VERSION ""

NS_ :

BS_:

BU_:

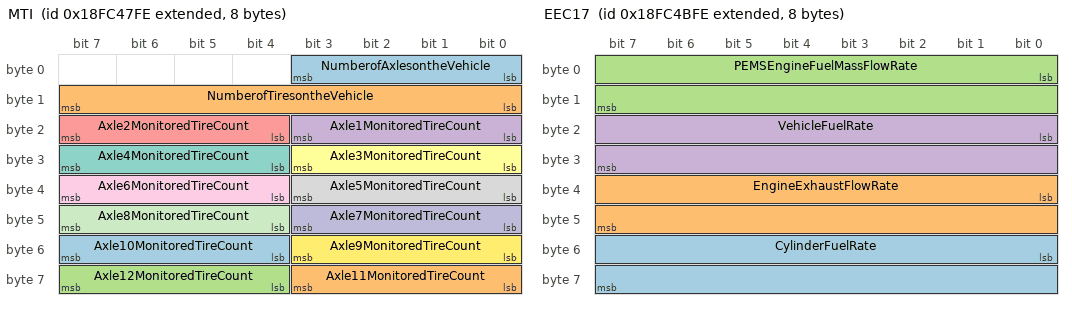
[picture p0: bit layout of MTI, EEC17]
BO_ 2566670334 MTI: 8 Vector__XXX
 SG_ Axle10MonitoredTireCount : 52|4@1+ (1,0) [0|13] "count" Vector__XXX
 SG_ Axle11MonitoredTireCount : 56|4@1+ (1,0) [0|13] "count" Vector__XXX
 SG_ Axle12MonitoredTireCount : 60|4@1+ (1,0) [0|13] "count" Vector__XXX
 SG_ Axle1MonitoredTireCount : 16|4@1+ (1,0) [0|13] "count" Vector__XXX
 SG_ Axle2MonitoredTireCount : 20|4@1+ (1,0) [0|13] "count" Vector__XXX
 SG_ Axle3MonitoredTireCount : 24|4@1+ (1,0) [0|13] "count" Vector__XXX
 SG_ Axle4MonitoredTireCount : 28|4@1+ (1,0) [0|13] "count" Vector__XXX
 SG_ Axle5MonitoredTireCount : 32|4@1+ (1,0) [0|13] "count" Vector__XXX
 SG_ Axle6MonitoredTireCount : 36|4@1+ (1,0) [0|13] "count" Vector__XXX
 SG_ Axle7MonitoredTireCount : 40|4@1+ (1,0) [0|13] "count" Vector__XXX
 SG_ Axle8MonitoredTireCount : 44|4@1+ (1,0) [0|13] "count" Vector__XXX
 SG_ Axle9MonitoredTireCount : 48|4@1+ (1,0) [0|13] "count" Vector__XXX
 SG_ NumberofAxlesontheVehicle : 0|4@1+ (1,0) [0|13] "count" Vector__XXX
 SG_ NumberofTiresontheVehicle : 8|8@1+ (1,0) [0|250] "count" Vector__XXX

BO_ 2566670590 AT2HI2: 24 Vector__XXX
 SG_ Atttt2SCRSstAvDstBtwSstCEvts : 160|32@1+ (0.125,0) [0|526385151.875] "km" Vector__XXX
 SG_ Atttt2SCRSstAvTBtwSstCEvts : 128|32@1+ (1,0) [0|4211081215] "s" Vector__XXX
 SG_ Atttt2SCRSstTtNSstCEvts : 32|32@1+ (1,0) [0|4211081215] "count" Vector__XXX
 SG_ Atttt2SCRSstTtNSstCItRqsts : 64|32@1+ (1,0) [0|4211081215] "count" Vector__XXX
 SG_ Atttt2SCRSstTtNSstCMRqsts : 96|32@1+ (1,0) [0|4211081215] "count" Vector__XXX
 SG_ Atttt2SCRSstTtSstCT : 0|32@1+ (1,0) [0|4211081215] "s" Vector__XXX

BO_ 2566670846 AT1HI2: 28 Vector__XXX
 SG_ Aftrtrtmnt1SCRSstmTtlClnngTm : 0|32@1+ (1,0) [0|4211081215] "s" Vector__XXX
 SG_ Atttt1SCRSstAvDstBtwSstCEvts : 160|32@1+ (0.125,0) [0|526385151.875] "km" Vector__XXX
 SG_ Atttt1SCRSstAvTBtwSstCEvts : 128|32@1+ (1,0) [0|4211081215] "s" Vector__XXX
 SG_ Atttt1SCRSstTtNSstCEvts : 32|32@1+ (1,0) [0|4211081215] "count" Vector__XXX
 SG_ Atttt1SCRSstTtNSstCItRqsts : 64|32@1+ (1,0) [0|4211081215] "count" Vector__XXX
 SG_ Atttt1SCRSstTtNSstCMRqsts : 96|32@1+ (1,0) [0|4211081215] "count" Vector__XXX
 SG_ TtlAftrtrtmntOprtngHrs : 192|32@1+ (1,0) [0|4211081215] "s" Vector__XXX

BO_ 2566671102 SCRSC: 8 Vector__XXX
 SG_ Atttt1SCRSstCdtsNtMtAtvC : 60|2@1+ (1,0) [0|3] "" Vector__XXX
 SG_ SCRSstCItdDtAtPdOId : 26|2@1+ (1,0) [0|3] "" Vector__XXX
 SG_ SCRSstCItdDtLwExstTpt : 34|2@1+ (1,0) [0|3] "" Vector__XXX
 SG_ SCRSstCItdDtPtSstLt : 42|2@1+ (1,0) [0|3] "" Vector__XXX
 SG_ SCRSstCItdDtVSpdAvAwdSpd : 30|2@1+ (1,0) [0|3] "" Vector__XXX
 SG_ SCRSstCItdDtVSpdBwAwdSpd : 46|2@1+ (1,0) [0|3] "" Vector__XXX
 SG_ SCRSstmClnngAtmtInttnCnfgrtn : 48|2@1+ (1,0) [0|3] "" Vector__XXX
 SG_ SCRSstmClnngInhtdDtClthDsnggd : 20|2@1+ (1,0) [0|3] "" Vector__XXX
 SG_ SCRSstmClnngInhtdDtEngnNtWrmdUp : 44|2@1+ (1,0) [0|3] "" Vector__XXX
 SG_ SCRSstmClnngInhtdDtInhtSwth : 18|2@1+ (1,0) [0|3] "" Vector__XXX
 SG_ SCRSstmClnngInhtdDtOtfNtrl : 28|2@1+ (1,0) [0|3] "" Vector__XXX
 SG_ SCRSstmClnngInhtdDtPrkngBrkNtSt : 32|2@1+ (1,0) [0|3] "" Vector__XXX
 SG_ SCRSstmClnngInhtdDtPTOAtv : 24|2@1+ (1,0) [0|3] "" Vector__XXX
 SG_ SCRSstmClnngInhtdDtSrvBrkAtv : 22|2@1+ (1,0) [0|3] "" Vector__XXX
 SG_ SCRSstmClnngInhtdDtSstmFltAtv : 36|2@1+ (1,0) [0|3] "" Vector__XXX
 SG_ SCRSstmClnngInhtdDtSstmTmt : 38|2@1+ (1,0) [0|3] "" Vector__XXX
 SG_ SCRSstmClnngInhtdDtTmprrSstmLkt : 40|2@1+ (1,0) [0|3] "" Vector__XXX
 SG_ SCRSstmClnngInhtdStts : 16|2@1+ (1,0) [0|3] "" Vector__XXX
 SG_ SCRSystemCleaningForcedStatus : 53|3@1+ (1,0) [0|7] "" Vector__XXX
 SG_ SCRSystemCleaningLampCommand : 0|3@1+ (1,0) [0|7] "" Vector__XXX
 SG_ SCRSystemCleaningStatus : 10|2@1+ (1,0) [0|3] "" Vector__XXX

BO_ 2566671358 EEC17: 8 Vector__XXX
 SG_ CylinderFuelRate : 48|16@1+ (0.03125,0) [0|2007.96875] "mg/stroke" Vector__XXX
 SG_ EngineExhaustFlowRate : 32|16@1+ (0.2,0) [0|12851] "kg/h" Vector__XXX
 SG_ PEMSEngineFuelMassFlowRate : 0|16@1+ (0.02,0) [0|1285.1] "g/s" Vector__XXX
 SG_ VehicleFuelRate : 16|16@1+ (0.02,0) [0|1285.1] "g/s" Vector__XXX

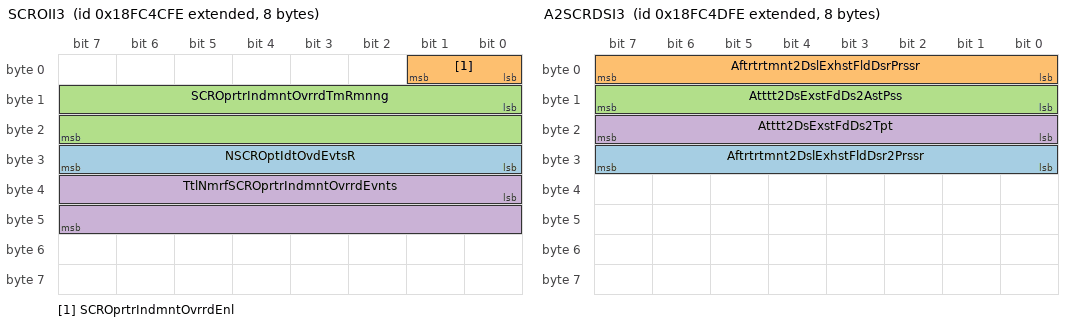
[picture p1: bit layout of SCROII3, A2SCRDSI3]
BO_ 2566671614 SCROII3: 8 Vector__XXX
 SG_ NSCROptIdtOvdEvtsR : 24|8@1+ (1,0) [0|250] "count" Vector__XXX
 SG_ SCROprtrIndmntOvrrdEnl : 0|2@1+ (1,0) [0|3] "" Vector__XXX
 SG_ SCROprtrIndmntOvrrdTmRmnng : 8|16@1+ (1,0) [0|64255] "s" Vector__XXX
 SG_ TtlNmrfSCROprtrIndmntOvrrdEvnts : 32|16@1+ (1,0) [0|64255] "count" Vector__XXX

BO_ 2566671870 A2SCRDSI3: 8 Vector__XXX
 SG_ Aftrtrtmnt2DslExhstFldDsr2Prssr : 24|8@1+ (4,0) [0|1000] "kPa" Vector__XXX
 SG_ Aftrtrtmnt2DslExhstFldDsrPrssr : 0|8@1+ (4,0) [0|1000] "kPa" Vector__XXX
 SG_ Atttt2DsExstFdDs2AstPss : 8|8@1+ (8,0) [0|2000] "kPa" Vector__XXX
 SG_ Atttt2DsExstFdDs2Tpt : 16|8@1+ (1,-40) [-40|210] "degC" Vector__XXX

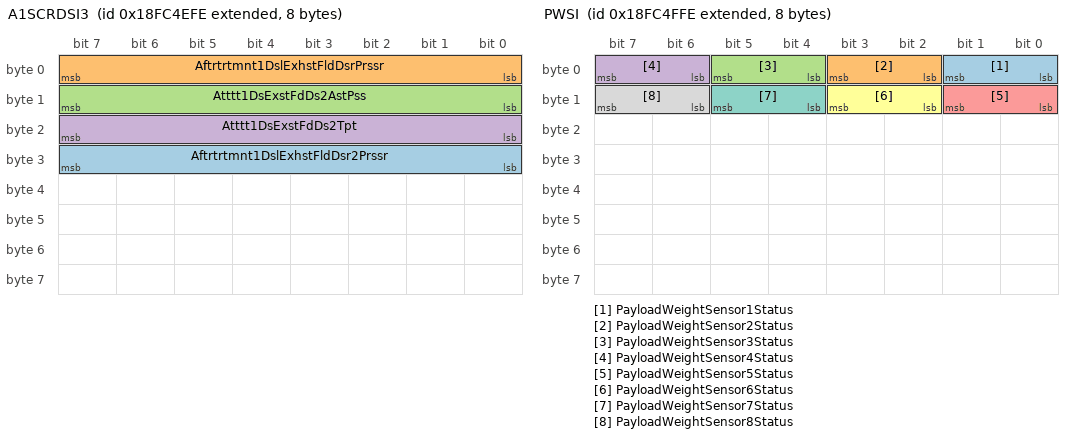
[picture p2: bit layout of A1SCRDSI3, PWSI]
BO_ 2566672126 A1SCRDSI3: 8 Vector__XXX
 SG_ Aftrtrtmnt1DslExhstFldDsr2Prssr : 24|8@1+ (4,0) [0|1000] "kPa" Vector__XXX
 SG_ Aftrtrtmnt1DslExhstFldDsrPrssr : 0|8@1+ (4,0) [0|1000] "kPa" Vector__XXX
 SG_ Atttt1DsExstFdDs2AstPss : 8|8@1+ (8,0) [0|2000] "kPa" Vector__XXX
 SG_ Atttt1DsExstFdDs2Tpt : 16|8@1+ (1,-40) [-40|210] "degC" Vector__XXX

BO_ 2566672382 PWSI: 8 Vector__XXX
 SG_ PayloadWeightSensor1Status : 0|2@1+ (1,0) [0|3] "" Vector__XXX
 SG_ PayloadWeightSensor2Status : 2|2@1+ (1,0) [0|3] "" Vector__XXX
 SG_ PayloadWeightSensor3Status : 4|2@1+ (1,0) [0|3] "" Vector__XXX
 SG_ PayloadWeightSensor4Status : 6|2@1+ (1,0) [0|3] "" Vector__XXX
 SG_ PayloadWeightSensor5Status : 8|2@1+ (1,0) [0|3] "" Vector__XXX
 SG_ PayloadWeightSensor6Status : 10|2@1+ (1,0) [0|3] "" Vector__XXX
 SG_ PayloadWeightSensor7Status : 12|2@1+ (1,0) [0|3] "" Vector__XXX
 SG_ PayloadWeightSensor8Status : 14|2@1+ (1,0) [0|3] "" Vector__XXX

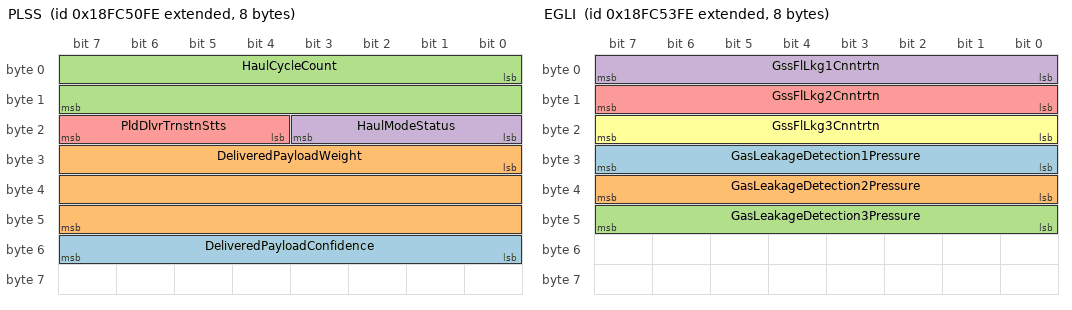
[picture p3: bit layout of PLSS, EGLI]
BO_ 2566672638 PLSS: 8 Vector__XXX
 SG_ DeliveredPayloadConfidence : 48|8@1+ (0.5,0) [0|125] "%" Vector__XXX
 SG_ DeliveredPayloadWeight : 24|24@1+ (2,0) [0|32899070] "kg" Vector__XXX
 SG_ HaulCycleCount : 0|16@1+ (1,0) [0|64255] "count" Vector__XXX
 SG_ HaulModeStatus : 16|4@1+ (1,0) [0|15] "" Vector__XXX
 SG_ PldDlvrTrnstnStts : 20|4@1+ (1,0) [0|15] "" Vector__XXX

BO_ 2566673406 EGLI: 8 Vector__XXX
 SG_ GasLeakageDetection1Pressure : 24|8@1+ (4,0) [0|1000] "kPa" Vector__XXX
 SG_ GasLeakageDetection2Pressure : 32|8@1+ (4,0) [0|1000] "kPa" Vector__XXX
 SG_ GasLeakageDetection3Pressure : 40|8@1+ (4,0) [0|1000] "kPa" Vector__XXX
 SG_ GssFlLkg1Cnntrtn : 0|8@1+ (0.5,0) [0|125] "%" Vector__XXX
 SG_ GssFlLkg2Cnntrtn : 8|8@1+ (0.5,0) [0|125] "%" Vector__XXX
 SG_ GssFlLkg3Cnntrtn : 16|8@1+ (0.5,0) [0|125] "%" Vector__XXX

BO_ 2566674174 SCROII2: 8 Vector__XXX
 SG_ AftrtrtmntSCRMlfntnTm : 0|32@1+ (1,0) [0|4211081215] "s" Vector__XXX
 SG_ SCROperatorInducementTotalTime : 32|32@1+ (1,0) [0|4211081215] "s" Vector__XXX

BO_ 2566674430 SCROII1: 8 Vector__XXX
 SG_ DslExhstFldQltMlfntnTm : 32|32@1+ (1,0) [0|4211081215] "s" Vector__XXX
 SG_ DslExhstFldTnk1EmptTm : 0|32@1+ (1,0) [0|4211081215] "s" Vector__XXX

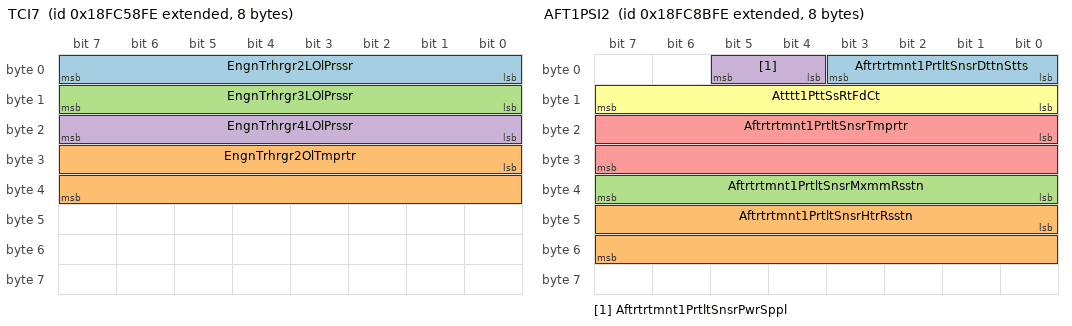
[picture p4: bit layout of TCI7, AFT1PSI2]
BO_ 2566674686 TCI7: 8 Vector__XXX
 SG_ EngnTrhrgr2LOlPrssr : 0|8@1+ (4,0) [0|1000] "kPa" Vector__XXX
 SG_ EngnTrhrgr2OlTmprtr : 24|16@1+ (0.03125,-273) [-273|1734.96875] "degC" Vector__XXX
 SG_ EngnTrhrgr3LOlPrssr : 8|8@1+ (4,0) [0|1000] "kPa" Vector__XXX
 SG_ EngnTrhrgr4LOlPrssr : 16|8@1+ (4,0) [0|1000] "kPa" Vector__XXX

BO_ 2566675966 HVESSCFG: 200 Vector__XXX
 SG_ HVESSNominalVoltage : 0|16@1+ (0.05,0) [0|3212.75] "V" Vector__XXX
 SG_ HVESSRmmnddMnmmOprtngVltg : 16|16@1+ (0.05,0) [0|3212.75] "V" Vector__XXX
 SG_ HVESSRmmnddMxmmOprtngVltg : 32|16@1+ (0.05,0) [0|3212.75] "V" Vector__XXX
 SG_ HVESSRmmnddMnmmSttOfChrg : 48|16@1+ (0.0015625,0) [0|100.3984375] "%" Vector__XXX
 SG_ HVESSRmmnddMxmmSttOfChrg : 64|16@1+ (0.0015625,0) [0|100.3984375] "%" Vector__XXX
 SG_ HVESSRmmnddMxmmOprtngTmprtr : 80|16@1+ (0.03125,-273) [-273|1734.96875] "degC" Vector__XXX
 SG_ HVESSRmmnddMnmmOprtngTmprtr : 96|16@1+ (0.03125,-273) [-273|1734.96875] "degC" Vector__XXX
 SG_ HVESSCellMaximumVoltageLimit : 112|8@1+ (0.02044,0) [0|5.11] "V" Vector__XXX
 SG_ HVESSCellMinimumVoltageLimit : 120|8@1+ (0.02044,0) [0|5.11] "V" Vector__XXX
 SG_ HVESSNumberofHVESPsConfigured : 128|8@1+ (1,0) [0|250] "count" Vector__XXX

BO_ 2566687742 AFT1PSI2: 8 Vector__XXX
 SG_ Aftrtrtmnt1PrtltSnsrDttnStts : 0|4@1+ (1,0) [0|15] "" Vector__XXX
 SG_ Aftrtrtmnt1PrtltSnsrHtrRsstn : 40|16@1+ (0.1,0) [0|6425.5] "ohm" Vector__XXX
 SG_ Aftrtrtmnt1PrtltSnsrMxmmRsstn : 32|8@1+ (250,0) [0|62500] "kohm" Vector__XXX
 SG_ Aftrtrtmnt1PrtltSnsrPwrSppl : 4|2@1+ (1,0) [0|3] "" Vector__XXX
 SG_ Aftrtrtmnt1PrtltSnsrTmprtr : 16|16@1+ (0.03125,-273) [-273|1734.96875] "degC" Vector__XXX
 SG_ Atttt1PttSsRtFdCt : 8|8@1+ (1,0) [0|250] "count" Vector__XXX

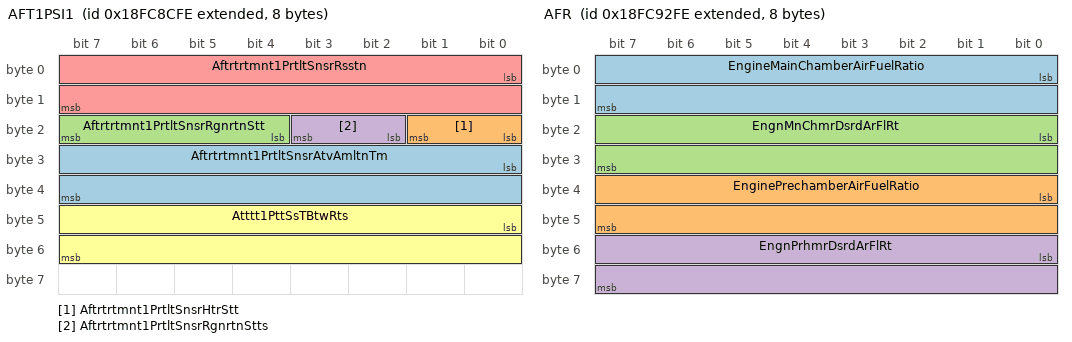
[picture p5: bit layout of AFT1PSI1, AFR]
BO_ 2566687998 AFT1PSI1: 8 Vector__XXX
 SG_ Aftrtrtmnt1PrtltSnsrAtvAmltnTm : 24|16@1+ (6,0) [0|385530] "s" Vector__XXX
 SG_ Aftrtrtmnt1PrtltSnsrHtrStt : 16|2@1+ (1,0) [0|3] "" Vector__XXX
 SG_ Aftrtrtmnt1PrtltSnsrRgnrtnStt : 20|4@1+ (1,0) [0|15] "" Vector__XXX
 SG_ Aftrtrtmnt1PrtltSnsrRgnrtnStts : 18|2@1+ (1,0) [0|3] "" Vector__XXX
 SG_ Aftrtrtmnt1PrtltSnsrRsstn : 0|16@1+ (1,0) [0|64255] "kohm" Vector__XXX
 SG_ Atttt1PttSsTBtwRts : 40|16@1+ (6,0) [0|385530] "s" Vector__XXX

BO_ 2566689278 EEN: 8 Vector__XXX
 SG_ EngineExhaustDesiredNOx : 16|16@1+ (0.05,-200) [-200|3012.75] "ppm" Vector__XXX
 SG_ EngineExhaustNOx : 0|16@1+ (0.05,-200) [-200|3012.75] "ppm" Vector__XXX
 SG_ EngnExhstNOxSnsrPwrSppl : 32|2@1+ (1,0) [0|3] "" Vector__XXX

BO_ 2566689534 AFR: 8 Vector__XXX
 SG_ EngineMainChamberAirFuelRatio : 0|16@1+ (0.001,0) [0|64.255] "Ratio" Vector__XXX
 SG_ EnginePrechamberAirFuelRatio : 32|16@1+ (0.001,0) [0|64.255] "Ratio" Vector__XXX
 SG_ EngnMnChmrDsrdArFlRt : 16|16@1+ (0.001,0) [0|64.255] "Ratio" Vector__XXX
 SG_ EngnPrhmrDsrdArFlRt : 48|16@1+ (0.001,0) [0|64.255] "Ratio" Vector__XXX

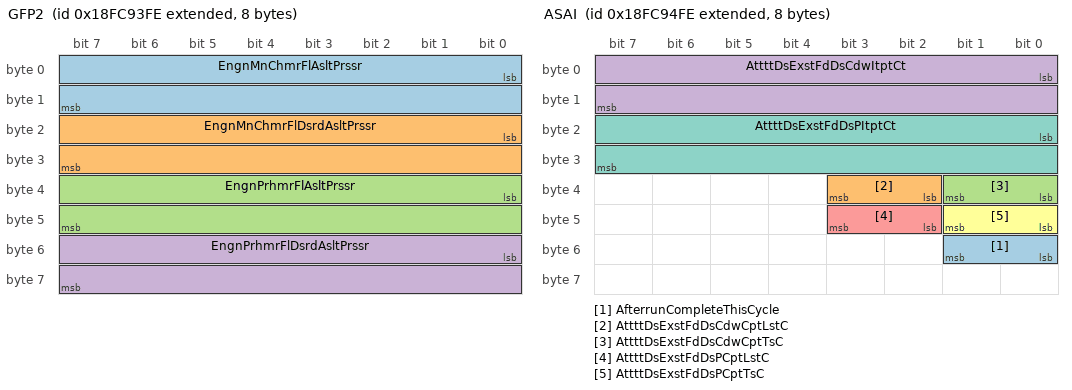
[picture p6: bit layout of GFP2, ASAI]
BO_ 2566689790 GFP2: 8 Vector__XXX
 SG_ EngnMnChmrFlAsltPrssr : 0|16@1+ (0.1,0) [0|6425.5] "kPa" Vector__XXX
 SG_ EngnMnChmrFlDsrdAsltPrssr : 16|16@1+ (0.1,0) [0|6425.5] "kPa" Vector__XXX
 SG_ EngnPrhmrFlAsltPrssr : 32|16@1+ (0.1,0) [0|6425.5] "kPa" Vector__XXX
 SG_ EngnPrhmrFlDsrdAsltPrssr : 48|16@1+ (0.1,0) [0|6425.5] "kPa" Vector__XXX

BO_ 2566690046 ASAI: 8 Vector__XXX
 SG_ AfterrunCompleteThisCycle : 48|2@1+ (1,0) [0|3] "" Vector__XXX
 SG_ AttttDsExstFdDsCdwCptLstC : 34|2@1+ (1,0) [0|3] "" Vector__XXX
 SG_ AttttDsExstFdDsCdwCptTsC : 32|2@1+ (1,0) [0|3] "" Vector__XXX
 SG_ AttttDsExstFdDsCdwItptCt : 0|16@1+ (1,0) [0|64255] "count" Vector__XXX
 SG_ AttttDsExstFdDsPCptLstC : 42|2@1+ (1,0) [0|3] "" Vector__XXX
 SG_ AttttDsExstFdDsPCptTsC : 40|2@1+ (1,0) [0|3] "" Vector__XXX
 SG_ AttttDsExstFdDsPItptCt : 16|16@1+ (1,0) [0|64255] "count" Vector__XXX

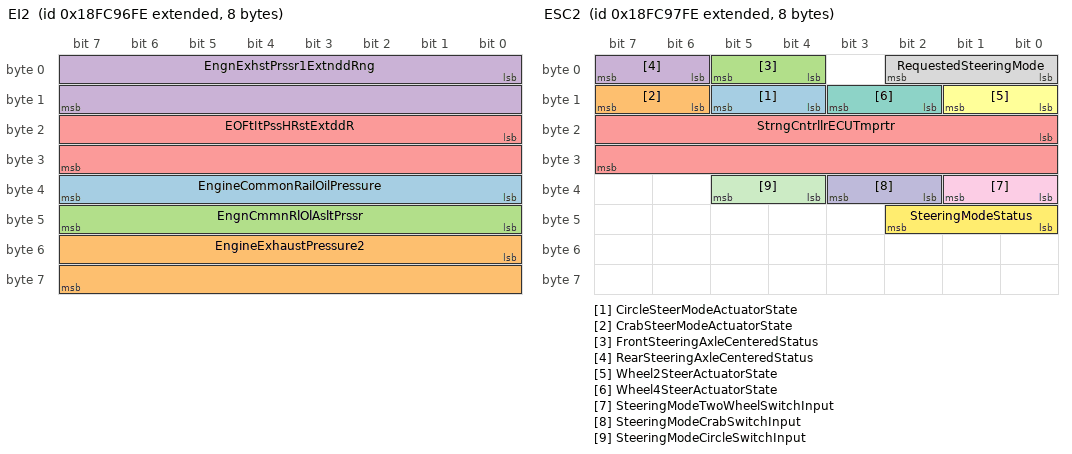
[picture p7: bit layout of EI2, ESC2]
BO_ 2566690558 EI2: 8 Vector__XXX
 SG_ EngineCommonRailOilPressure : 32|8@1+ (4,0) [0|1000] "kPa" Vector__XXX
 SG_ EngineExhaustPressure2 : 48|16@1+ (0.0078125,-250) [-250|251.99] "kPa" Vector__XXX
 SG_ EngnCmmnRlOlAsltPrssr : 40|8@1+ (4,0) [0|1000] "kPa" Vector__XXX
 SG_ EngnExhstPrssr1ExtnddRng : 0|16@1+ (0.125,0) [0|8031.875] "kPa" Vector__XXX
 SG_ EOFtItPssHRstExtddR : 16|16@1+ (0.1,0) [0|6425.5] "kPa" Vector__XXX

BO_ 2566690814 ESC2: 8 Vector__XXX
 SG_ CircleSteerModeActuatorState : 12|2@1+ (1,0) [0|3] "" Vector__XXX
 SG_ CrabSteerModeActuatorState : 14|2@1+ (1,0) [0|3] "" Vector__XXX
 SG_ FrontSteeringAxleCenteredStatus : 4|2@1+ (1,0) [0|3] "" Vector__XXX
 SG_ RearSteeringAxleCenteredStatus : 6|2@1+ (1,0) [0|3] "" Vector__XXX
 SG_ StrngCntrllrECUTmprtr : 16|16@1+ (0.03125,-273) [-273|1734.96875] "degC" Vector__XXX
 SG_ Wheel2SteerActuatorState : 8|2@1+ (1,0) [0|3] "" Vector__XXX
 SG_ Wheel4SteerActuatorState : 10|2@1+ (1,0) [0|3] "" Vector__XXX
 SG_ RequestedSteeringMode : 0|3@1+ (1,0) [0|7] "" Vector__XXX
 SG_ SteeringModeTwoWheelSwitchInput : 32|2@1+ (1,0) [0|3] "" Vector__XXX
 SG_ SteeringModeCrabSwitchInput : 34|2@1+ (1,0) [0|3] "" Vector__XXX
 SG_ SteeringModeCircleSwitchInput : 36|2@1+ (1,0) [0|3] "" Vector__XXX
 SG_ SteeringModeStatus : 40|3@1+ (1,0) [0|7] "" Vector__XXX

BO_ 2566691326 AUI: 200 Vector__XXX
 SG_ AssemblyUnitIdentification : 8|8@1+ (1,0) [0|255] "ASCII" Vector__XXX
 SG_ NmrfAssmlUntIdntftnFlds : 0|8@1+ (1,0) [0|250] "count" Vector__XXX

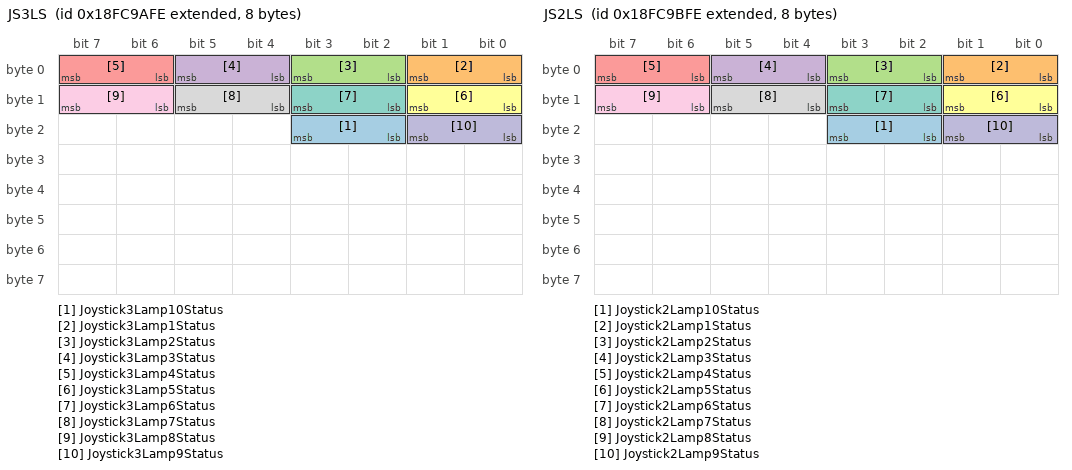
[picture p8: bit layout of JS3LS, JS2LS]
BO_ 2566691582 JS3LS: 8 Vector__XXX
 SG_ Joystick3Lamp10Status : 18|2@1+ (1,0) [0|3] "" Vector__XXX
 SG_ Joystick3Lamp1Status : 0|2@1+ (1,0) [0|3] "" Vector__XXX
 SG_ Joystick3Lamp2Status : 2|2@1+ (1,0) [0|3] "" Vector__XXX
 SG_ Joystick3Lamp3Status : 4|2@1+ (1,0) [0|3] "" Vector__XXX
 SG_ Joystick3Lamp4Status : 6|2@1+ (1,0) [0|3] "" Vector__XXX
 SG_ Joystick3Lamp5Status : 8|2@1+ (1,0) [0|3] "" Vector__XXX
 SG_ Joystick3Lamp6Status : 10|2@1+ (1,0) [0|3] "" Vector__XXX
 SG_ Joystick3Lamp7Status : 12|2@1+ (1,0) [0|3] "" Vector__XXX
 SG_ Joystick3Lamp8Status : 14|2@1+ (1,0) [0|3] "" Vector__XXX
 SG_ Joystick3Lamp9Status : 16|2@1+ (1,0) [0|3] "" Vector__XXX

BO_ 2566691838 JS2LS: 8 Vector__XXX
 SG_ Joystick2Lamp10Status : 18|2@1+ (1,0) [0|3] "" Vector__XXX
 SG_ Joystick2Lamp1Status : 0|2@1+ (1,0) [0|3] "" Vector__XXX
 SG_ Joystick2Lamp2Status : 2|2@1+ (1,0) [0|3] "" Vector__XXX
 SG_ Joystick2Lamp3Status : 4|2@1+ (1,0) [0|3] "" Vector__XXX
 SG_ Joystick2Lamp4Status : 6|2@1+ (1,0) [0|3] "" Vector__XXX
 SG_ Joystick2Lamp5Status : 8|2@1+ (1,0) [0|3] "" Vector__XXX
 SG_ Joystick2Lamp6Status : 10|2@1+ (1,0) [0|3] "" Vector__XXX
 SG_ Joystick2Lamp7Status : 12|2@1+ (1,0) [0|3] "" Vector__XXX
 SG_ Joystick2Lamp8Status : 14|2@1+ (1,0) [0|3] "" Vector__XXX
 SG_ Joystick2Lamp9Status : 16|2@1+ (1,0) [0|3] "" Vector__XXX

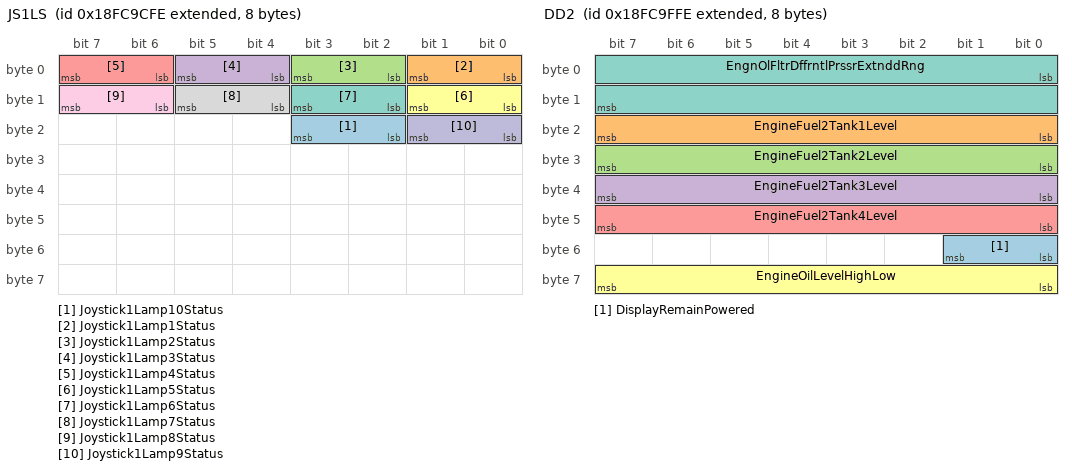
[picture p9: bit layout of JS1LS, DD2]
BO_ 2566692094 JS1LS: 8 Vector__XXX
 SG_ Joystick1Lamp10Status : 18|2@1+ (1,0) [0|3] "" Vector__XXX
 SG_ Joystick1Lamp1Status : 0|2@1+ (1,0) [0|3] "" Vector__XXX
 SG_ Joystick1Lamp2Status : 2|2@1+ (1,0) [0|3] "" Vector__XXX
 SG_ Joystick1Lamp3Status : 4|2@1+ (1,0) [0|3] "" Vector__XXX
 SG_ Joystick1Lamp4Status : 6|2@1+ (1,0) [0|3] "" Vector__XXX
 SG_ Joystick1Lamp5Status : 8|2@1+ (1,0) [0|3] "" Vector__XXX
 SG_ Joystick1Lamp6Status : 10|2@1+ (1,0) [0|3] "" Vector__XXX
 SG_ Joystick1Lamp7Status : 12|2@1+ (1,0) [0|3] "" Vector__XXX
 SG_ Joystick1Lamp8Status : 14|2@1+ (1,0) [0|3] "" Vector__XXX
 SG_ Joystick1Lamp9Status : 16|2@1+ (1,0) [0|3] "" Vector__XXX

BO_ 2566692862 DD2: 8 Vector__XXX
 SG_ DisplayRemainPowered : 48|2@1+ (1,0) [0|3] "" Vector__XXX
 SG_ EngineFuel2Tank1Level : 16|8@1+ (0.4,0) [0|100] "%" Vector__XXX
 SG_ EngineFuel2Tank2Level : 24|8@1+ (0.4,0) [0|100] "%" Vector__XXX
 SG_ EngineFuel2Tank3Level : 32|8@1+ (0.4,0) [0|100] "%" Vector__XXX
 SG_ EngineFuel2Tank4Level : 40|8@1+ (0.4,0) [0|100] "%" Vector__XXX
 SG_ EngineOilLevelHighLow : 56|8@1+ (0.5,-62.5) [-62.5|62.5] "l" Vector__XXX
 SG_ EngnOlFltrDffrntlPrssrExtnddRng : 0|16@1+ (0.0078125,-250) [-250|251.99] "kPa" Vector__XXX

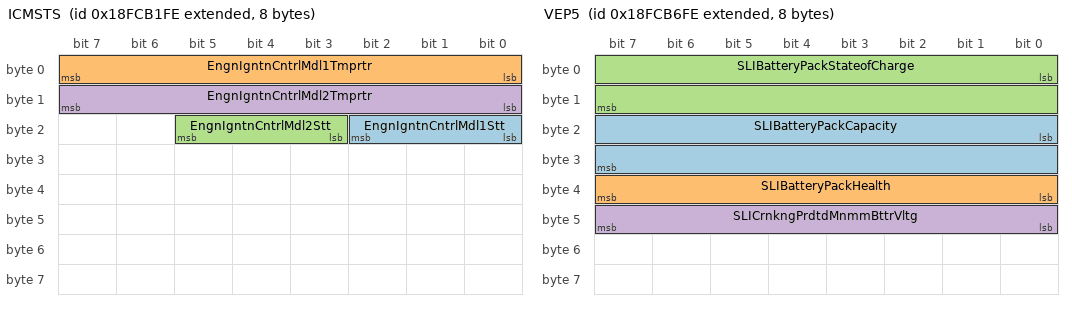
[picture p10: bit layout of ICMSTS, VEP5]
BO_ 2566697470 ICMSTS: 8 Vector__XXX
 SG_ EngnIgntnCntrlMdl1Stt : 16|3@1+ (1,0) [0|7] "" Vector__XXX
 SG_ EngnIgntnCntrlMdl1Tmprtr : 0|8@1+ (1,-40) [-40|210] "degC" Vector__XXX
 SG_ EngnIgntnCntrlMdl2Stt : 19|3@1+ (1,0) [0|7] "" Vector__XXX
 SG_ EngnIgntnCntrlMdl2Tmprtr : 8|8@1+ (1,-40) [-40|210] "degC" Vector__XXX

BO_ 2566697726 SPOC1: 64 Vector__XXX
 SG_ SwitchedOutput10Current : 144|16@1+ (0.005,0) [0|321.275] "A" Vector__XXX
 SG_ SwitchedOutput11Current : 160|16@1+ (0.005,0) [0|321.275] "A" Vector__XXX
 SG_ SwitchedOutput12Current : 176|16@1+ (0.005,0) [0|321.275] "A" Vector__XXX
 SG_ SwitchedOutput13Current : 192|16@1+ (0.005,0) [0|321.275] "A" Vector__XXX
 SG_ SwitchedOutput14Current : 208|16@1+ (0.005,0) [0|321.275] "A" Vector__XXX
 SG_ SwitchedOutput15Current : 224|16@1+ (0.005,0) [0|321.275] "A" Vector__XXX
 SG_ SwitchedOutput16Current : 240|16@1+ (0.005,0) [0|321.275] "A" Vector__XXX
 SG_ SwitchedOutput17Current : 256|16@1+ (0.005,0) [0|321.275] "A" Vector__XXX
 SG_ SwitchedOutput18Current : 272|16@1+ (0.005,0) [0|321.275] "A" Vector__XXX
 SG_ SwitchedOutput19Current : 288|16@1+ (0.005,0) [0|321.275] "A" Vector__XXX
 SG_ SwitchedOutput1Current : 0|16@1+ (0.005,0) [0|321.275] "A" Vector__XXX
 SG_ SwitchedOutput20Current : 304|16@1+ (0.005,0) [0|321.275] "A" Vector__XXX
 SG_ SwitchedOutput21Current : 320|16@1+ (0.005,0) [0|321.275] "A" Vector__XXX
 SG_ SwitchedOutput22Current : 336|16@1+ (0.005,0) [0|321.275] "A" Vector__XXX
 SG_ SwitchedOutput23Current : 352|16@1+ (0.005,0) [0|321.275] "A" Vector__XXX
 SG_ SwitchedOutput24Current : 368|16@1+ (0.005,0) [0|321.275] "A" Vector__XXX
 SG_ SwitchedOutput25Current : 384|16@1+ (0.005,0) [0|321.275] "A" Vector__XXX
 SG_ SwitchedOutput26Current : 400|16@1+ (0.005,0) [0|321.275] "A" Vector__XXX
 SG_ SwitchedOutput27Current : 416|16@1+ (0.005,0) [0|321.275] "A" Vector__XXX
 SG_ SwitchedOutput28Current : 432|16@1+ (0.005,0) [0|321.275] "A" Vector__XXX
 SG_ SwitchedOutput29Current : 448|16@1+ (0.005,0) [0|321.275] "A" Vector__XXX
 SG_ SwitchedOutput2Current : 16|16@1+ (0.005,0) [0|321.275] "A" Vector__XXX
 SG_ SwitchedOutput30Current : 464|16@1+ (0.005,0) [0|321.275] "A" Vector__XXX
 SG_ SwitchedOutput31Current : 480|16@1+ (0.005,0) [0|321.275] "A" Vector__XXX
 SG_ SwitchedOutput32Current : 496|16@1+ (0.005,0) [0|321.275] "A" Vector__XXX
 SG_ SwitchedOutput3Current : 32|16@1+ (0.005,0) [0|321.275] "A" Vector__XXX
 SG_ SwitchedOutput4Current : 48|16@1+ (0.005,0) [0|321.275] "A" Vector__XXX
 SG_ SwitchedOutput5Current : 64|16@1+ (0.005,0) [0|321.275] "A" Vector__XXX
 SG_ SwitchedOutput6Current : 80|16@1+ (0.005,0) [0|321.275] "A" Vector__XXX
 SG_ SwitchedOutput7Current : 96|16@1+ (0.005,0) [0|321.275] "A" Vector__XXX
 SG_ SwitchedOutput8Current : 112|16@1+ (0.005,0) [0|321.275] "A" Vector__XXX
 SG_ SwitchedOutput9Current : 128|16@1+ (0.005,0) [0|321.275] "A" Vector__XXX

BO_ 2566697982 FPOC: 64 Vector__XXX
 SG_ FusedOutput10Current : 144|16@1+ (0.005,0) [0|321.275] "A" Vector__XXX
 SG_ FusedOutput11Current : 160|16@1+ (0.005,0) [0|321.275] "A" Vector__XXX
 SG_ FusedOutput12Current : 176|16@1+ (0.005,0) [0|321.275] "A" Vector__XXX
 SG_ FusedOutput13Current : 192|16@1+ (0.005,0) [0|321.275] "A" Vector__XXX
 SG_ FusedOutput14Current : 208|16@1+ (0.005,0) [0|321.275] "A" Vector__XXX
 SG_ FusedOutput15Current : 224|16@1+ (0.005,0) [0|321.275] "A" Vector__XXX
 SG_ FusedOutput16Current : 240|16@1+ (0.005,0) [0|321.275] "A" Vector__XXX
 SG_ FusedOutput17Current : 256|16@1+ (0.005,0) [0|321.275] "A" Vector__XXX
 SG_ FusedOutput18Current : 272|16@1+ (0.005,0) [0|321.275] "A" Vector__XXX
 SG_ FusedOutput19Current : 288|16@1+ (0.005,0) [0|321.275] "A" Vector__XXX
 SG_ FusedOutput1Current : 0|16@1+ (0.005,0) [0|321.275] "A" Vector__XXX
 SG_ FusedOutput20Current : 304|16@1+ (0.005,0) [0|321.275] "A" Vector__XXX
 SG_ FusedOutput21Current : 320|16@1+ (0.005,0) [0|321.275] "A" Vector__XXX
 SG_ FusedOutput22Current : 336|16@1+ (0.005,0) [0|321.275] "A" Vector__XXX
 SG_ FusedOutput23Current : 352|16@1+ (0.005,0) [0|321.275] "A" Vector__XXX
 SG_ FusedOutput24Current : 368|16@1+ (0.005,0) [0|321.275] "A" Vector__XXX
 SG_ FusedOutput25Current : 384|16@1+ (0.005,0) [0|321.275] "A" Vector__XXX
 SG_ FusedOutput26Current : 400|16@1+ (0.005,0) [0|321.275] "A" Vector__XXX
 SG_ FusedOutput27Current : 416|16@1+ (0.005,0) [0|321.275] "A" Vector__XXX
 SG_ FusedOutput28Current : 432|16@1+ (0.005,0) [0|321.275] "A" Vector__XXX
 SG_ FusedOutput29Current : 448|16@1+ (0.005,0) [0|321.275] "A" Vector__XXX
 SG_ FusedOutput2Current : 16|16@1+ (0.005,0) [0|321.275] "A" Vector__XXX
 SG_ FusedOutput30Current : 464|16@1+ (0.005,0) [0|321.275] "A" Vector__XXX
 SG_ FusedOutput31Current : 480|16@1+ (0.005,0) [0|321.275] "A" Vector__XXX
 SG_ FusedOutput32Current : 496|16@1+ (0.005,0) [0|321.275] "A" Vector__XXX
 SG_ FusedOutput3Current : 32|16@1+ (0.005,0) [0|321.275] "A" Vector__XXX
 SG_ FusedOutput4Current : 48|16@1+ (0.005,0) [0|321.275] "A" Vector__XXX
 SG_ FusedOutput5Current : 64|16@1+ (0.005,0) [0|321.275] "A" Vector__XXX
 SG_ FusedOutput6Current : 80|16@1+ (0.005,0) [0|321.275] "A" Vector__XXX
 SG_ FusedOutput7Current : 96|16@1+ (0.005,0) [0|321.275] "A" Vector__XXX
 SG_ FusedOutput8Current : 112|16@1+ (0.005,0) [0|321.275] "A" Vector__XXX
 SG_ FusedOutput9Current : 128|16@1+ (0.005,0) [0|321.275] "A" Vector__XXX

BO_ 2566698238 SPOS: 8 Vector__XXX
 SG_ SwitchedOutput1 : 6|2@1+ (1,0) [0|3] "" Vector__XXX
 SG_ SwitchedOutput10 : 20|2@1+ (1,0) [0|3] "" Vector__XXX
 SG_ SwitchedOutput11 : 18|2@1+ (1,0) [0|3] "" Vector__XXX
 SG_ SwitchedOutput12 : 16|2@1+ (1,0) [0|3] "" Vector__XXX
 SG_ SwitchedOutput13 : 30|2@1+ (1,0) [0|3] "" Vector__XXX
 SG_ SwitchedOutput14 : 28|2@1+ (1,0) [0|3] "" Vector__XXX
 SG_ SwitchedOutput15 : 26|2@1+ (1,0) [0|3] "" Vector__XXX
 SG_ SwitchedOutput16 : 24|2@1+ (1,0) [0|3] "" Vector__XXX
 SG_ SwitchedOutput17 : 38|2@1+ (1,0) [0|3] "" Vector__XXX
 SG_ SwitchedOutput18 : 36|2@1+ (1,0) [0|3] "" Vector__XXX
 SG_ SwitchedOutput19 : 34|2@1+ (1,0) [0|3] "" Vector__XXX
 SG_ SwitchedOutput2 : 4|2@1+ (1,0) [0|3] "" Vector__XXX
 SG_ SwitchedOutput20 : 32|2@1+ (1,0) [0|3] "" Vector__XXX
 SG_ SwitchedOutput21 : 46|2@1+ (1,0) [0|3] "" Vector__XXX
 SG_ SwitchedOutput22 : 44|2@1+ (1,0) [0|3] "" Vector__XXX
 SG_ SwitchedOutput23 : 42|2@1+ (1,0) [0|3] "" Vector__XXX
 SG_ SwitchedOutput24 : 40|2@1+ (1,0) [0|3] "" Vector__XXX
 SG_ SwitchedOutput25 : 54|2@1+ (1,0) [0|3] "" Vector__XXX
 SG_ SwitchedOutput26 : 52|2@1+ (1,0) [0|3] "" Vector__XXX
 SG_ SwitchedOutput27 : 50|2@1+ (1,0) [0|3] "" Vector__XXX
 SG_ SwitchedOutput28 : 48|2@1+ (1,0) [0|3] "" Vector__XXX
 SG_ SwitchedOutput29 : 62|2@1+ (1,0) [0|3] "" Vector__XXX
 SG_ SwitchedOutput3 : 2|2@1+ (1,0) [0|3] "" Vector__XXX
 SG_ SwitchedOutput30 : 60|2@1+ (1,0) [0|3] "" Vector__XXX
 SG_ SwitchedOutput31 : 58|2@1+ (1,0) [0|3] "" Vector__XXX
 SG_ SwitchedOutput32 : 56|2@1+ (1,0) [0|3] "" Vector__XXX
 SG_ SwitchedOutput4 : 0|2@1+ (1,0) [0|3] "" Vector__XXX
 SG_ SwitchedOutput5 : 14|2@1+ (1,0) [0|3] "" Vector__XXX
 SG_ SwitchedOutput6 : 12|2@1+ (1,0) [0|3] "" Vector__XXX
 SG_ SwitchedOutput7 : 10|2@1+ (1,0) [0|3] "" Vector__XXX
 SG_ SwitchedOutput8 : 8|2@1+ (1,0) [0|3] "" Vector__XXX
 SG_ SwitchedOutput9 : 22|2@1+ (1,0) [0|3] "" Vector__XXX

BO_ 2566698494 FPOS: 8 Vector__XXX
 SG_ FusedOutput1 : 6|2@1+ (1,0) [0|3] "" Vector__XXX
 SG_ FusedOutput10 : 20|2@1+ (1,0) [0|3] "" Vector__XXX
 SG_ FusedOutput11 : 18|2@1+ (1,0) [0|3] "" Vector__XXX
 SG_ FusedOutput12 : 16|2@1+ (1,0) [0|3] "" Vector__XXX
 SG_ FusedOutput13 : 30|2@1+ (1,0) [0|3] "" Vector__XXX
 SG_ FusedOutput14 : 28|2@1+ (1,0) [0|3] "" Vector__XXX
 SG_ FusedOutput15 : 26|2@1+ (1,0) [0|3] "" Vector__XXX
 SG_ FusedOutput16 : 24|2@1+ (1,0) [0|3] "" Vector__XXX
 SG_ FusedOutput17 : 38|2@1+ (1,0) [0|3] "" Vector__XXX
 SG_ FusedOutput18 : 36|2@1+ (1,0) [0|3] "" Vector__XXX
 SG_ FusedOutput19 : 34|2@1+ (1,0) [0|3] "" Vector__XXX
 SG_ FusedOutput2 : 4|2@1+ (1,0) [0|3] "" Vector__XXX
 SG_ FusedOutput20 : 32|2@1+ (1,0) [0|3] "" Vector__XXX
 SG_ FusedOutput21 : 46|2@1+ (1,0) [0|3] "" Vector__XXX
 SG_ FusedOutput22 : 44|2@1+ (1,0) [0|3] "" Vector__XXX
 SG_ FusedOutput23 : 42|2@1+ (1,0) [0|3] "" Vector__XXX
 SG_ FusedOutput24 : 40|2@1+ (1,0) [0|3] "" Vector__XXX
 SG_ FusedOutput25 : 54|2@1+ (1,0) [0|3] "" Vector__XXX
 SG_ FusedOutput26 : 52|2@1+ (1,0) [0|3] "" Vector__XXX
 SG_ FusedOutput27 : 50|2@1+ (1,0) [0|3] "" Vector__XXX
 SG_ FusedOutput28 : 48|2@1+ (1,0) [0|3] "" Vector__XXX
 SG_ FusedOutput29 : 62|2@1+ (1,0) [0|3] "" Vector__XXX
 SG_ FusedOutput3 : 2|2@1+ (1,0) [0|3] "" Vector__XXX
 SG_ FusedOutput30 : 60|2@1+ (1,0) [0|3] "" Vector__XXX
 SG_ FusedOutput31 : 58|2@1+ (1,0) [0|3] "" Vector__XXX
 SG_ FusedOutput32 : 56|2@1+ (1,0) [0|3] "" Vector__XXX
 SG_ FusedOutput4 : 0|2@1+ (1,0) [0|3] "" Vector__XXX
 SG_ FusedOutput5 : 14|2@1+ (1,0) [0|3] "" Vector__XXX
 SG_ FusedOutput6 : 12|2@1+ (1,0) [0|3] "" Vector__XXX
 SG_ FusedOutput7 : 10|2@1+ (1,0) [0|3] "" Vector__XXX
 SG_ FusedOutput8 : 8|2@1+ (1,0) [0|3] "" Vector__XXX
 SG_ FusedOutput9 : 22|2@1+ (1,0) [0|3] "" Vector__XXX

BO_ 2566698750 VEP5: 8 Vector__XXX
 SG_ SLIBatteryPackCapacity : 16|16@1+ (1,0) [0|64255] "Ah" Vector__XXX
 SG_ SLIBatteryPackHealth : 32|8@1+ (0.5,0) [0|125] "%" Vector__XXX
 SG_ SLIBatteryPackStateofCharge : 0|16@1+ (0.0025,0) [0|160.6375] "%" Vector__XXX
 SG_ SLICrnkngPrdtdMnmmBttrVltg : 40|8@1+ (0.2,0) [0|50] "V" Vector__XXX

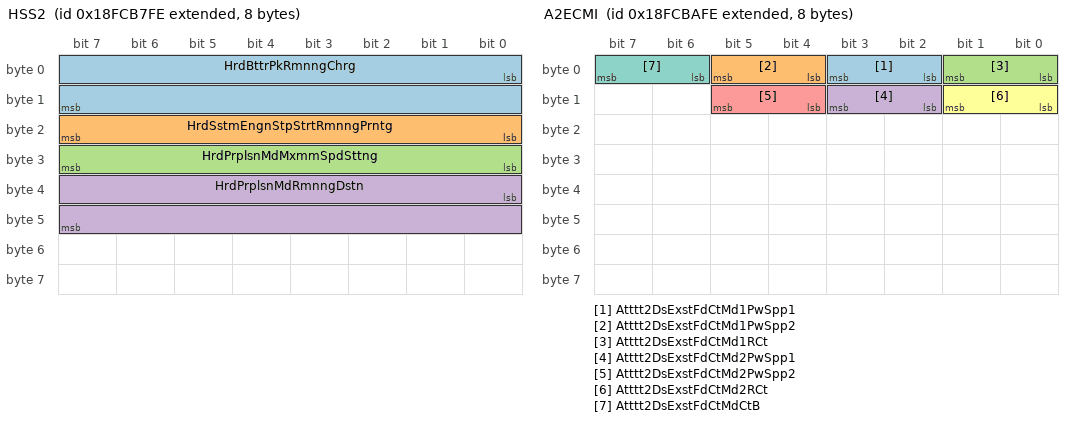
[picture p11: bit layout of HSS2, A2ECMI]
BO_ 2566699006 HSS2: 8 Vector__XXX
 SG_ HrdBttrPkRmnngChrg : 0|16@1+ (0.0025,0) [0|160.6375] "%" Vector__XXX
 SG_ HrdSstmEngnStpStrtRmnngPrntg : 16|8@1+ (0.4,0) [0|100] "%" Vector__XXX
 SG_ HrdPrplsnMdMxmmSpdSttng : 24|8@1+ (1,0) [0|250] "km/h" Vector__XXX
 SG_ HrdPrplsnMdRmnngDstn : 32|16@1+ (0.03125,0) [0|2007.96875] "km" Vector__XXX

BO_ 2566699262 AT2S2: 8 Vector__XXX
 SG_ Atttt2DsPttFtTtNxtAtvRt : 0|32@1+ (1,0) [0|4211081215] "s" Vector__XXX
 SG_ Atttt2SCRSstTSLstSstCEvt : 32|32@1+ (1,0) [0|4211081215] "s" Vector__XXX

BO_ 2566699518 AT1S2: 8 Vector__XXX
 SG_ Atttt1DsPttFtTtNxtAtvRt : 0|32@1+ (1,0) [0|4211081215] "s" Vector__XXX
 SG_ Atttt1SCRSstTSLstSstCEvt : 32|32@1+ (1,0) [0|4211081215] "s" Vector__XXX

BO_ 2566699774 A2ECMI: 8 Vector__XXX
 SG_ Atttt2DsExstFdCtMd1PwSpp1 : 2|2@1+ (1,0) [0|3] "" Vector__XXX
 SG_ Atttt2DsExstFdCtMd1PwSpp2 : 4|2@1+ (1,0) [0|3] "" Vector__XXX
 SG_ Atttt2DsExstFdCtMd1RCt : 0|2@1+ (1,0) [0|3] "" Vector__XXX
 SG_ Atttt2DsExstFdCtMd2PwSpp1 : 10|2@1+ (1,0) [0|3] "" Vector__XXX
 SG_ Atttt2DsExstFdCtMd2PwSpp2 : 12|2@1+ (1,0) [0|3] "" Vector__XXX
 SG_ Atttt2DsExstFdCtMd2RCt : 8|2@1+ (1,0) [0|3] "" Vector__XXX
 SG_ Atttt2DsExstFdCtMdCtB : 6|2@1+ (1,0) [0|3] "" Vector__XXX

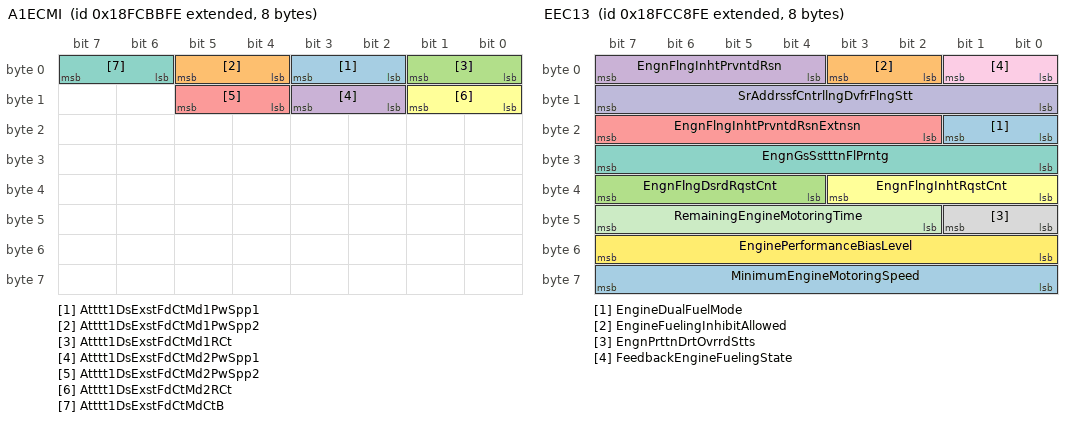
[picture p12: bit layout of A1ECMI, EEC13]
BO_ 2566700030 A1ECMI: 8 Vector__XXX
 SG_ Atttt1DsExstFdCtMd1PwSpp1 : 2|2@1+ (1,0) [0|3] "" Vector__XXX
 SG_ Atttt1DsExstFdCtMd1PwSpp2 : 4|2@1+ (1,0) [0|3] "" Vector__XXX
 SG_ Atttt1DsExstFdCtMd1RCt : 0|2@1+ (1,0) [0|3] "" Vector__XXX
 SG_ Atttt1DsExstFdCtMd2PwSpp1 : 10|2@1+ (1,0) [0|3] "" Vector__XXX
 SG_ Atttt1DsExstFdCtMd2PwSpp2 : 12|2@1+ (1,0) [0|3] "" Vector__XXX
 SG_ Atttt1DsExstFdCtMd2RCt : 8|2@1+ (1,0) [0|3] "" Vector__XXX
 SG_ Atttt1DsExstFdCtMdCtB : 6|2@1+ (1,0) [0|3] "" Vector__XXX

BO_ 2566700286 A2SCRSI2: 8 Vector__XXX
 SG_ Aftrtrtmnt2TtlDslExhstFldUsd : 0|32@1+ (0.5,0) [0|2105540607.5] "l" Vector__XXX

BO_ 2566700542 A1SCRSI2: 8 Vector__XXX
 SG_ Aftrtrtmnt1TtlDslExhstFldUsd : 0|32@1+ (0.5,0) [0|2105540607.5] "l" Vector__XXX
 SG_ AftrtrtmntTrpDslExhstFld : 32|32@1+ (0.05,0) [0|210554060.75] "l" Vector__XXX

BO_ 2566701566 TRF3: 8 Vector__XXX
 SG_ TransmissionClutch2Pressure : 0|8@1+ (16,0) [0|4000] "kPa" Vector__XXX
 SG_ TrnsmssnOlTrnsmssnClrOtltTmprtr : 8|8@1+ (1,-40) [-40|210] "degC" Vector__XXX

BO_ 2566701822 HSS1: 8 Vector__XXX
 SG_ ExtrnlEnrgSrCnntnStts : 48|4@1+ (1,0) [0|15] "" Vector__XXX
 SG_ HrdPrplsnMdTrnstnStts : 44|4@1+ (1,0) [0|15] "" Vector__XXX
 SG_ HrdSstmEltrAltrntrIndtr : 18|2@1+ (1,0) [0|3] "" Vector__XXX
 SG_ HrdSstmHghVltgExpsrIndtr : 24|2@1+ (1,0) [0|3] "" Vector__XXX
 SG_ HrdSstmIntlztnIndtr : 22|2@1+ (1,0) [0|3] "" Vector__XXX
 SG_ HrdSstmMtrOvrspdAdlAlrm : 16|2@1+ (1,0) [0|3] "" Vector__XXX
 SG_ HrdSstmMtrOvrspdIndtr : 14|2@1+ (1,0) [0|3] "" Vector__XXX
 SG_ HrdSstmPrplsnDslStts : 52|2@1+ (1,0) [0|3] "" Vector__XXX
 SG_ HrdSstmRgnrtvBrkngIndtr : 20|2@1+ (1,0) [0|3] "" Vector__XXX
 SG_ HybridPropulsionModeStatus : 40|4@1+ (1,0) [0|15] "" Vector__XXX
 SG_ HybridSystemEngineAssistStatus : 10|2@1+ (1,0) [0|3] "" Vector__XXX
 SG_ HybridSystemOBDRelatedDTCStatus : 6|2@1+ (1,0) [0|3] "" Vector__XXX
 SG_ HybridSystemOverheatIndicator : 2|2@1+ (1,0) [0|3] "" Vector__XXX
 SG_ HybridSystemServiceIndicator : 12|2@1+ (1,0) [0|3] "" Vector__XXX
 SG_ HybridSystemStopIndicator : 4|2@1+ (1,0) [0|3] "" Vector__XXX
 SG_ HybridSystemWarningIndicator : 0|2@1+ (1,0) [0|3] "" Vector__XXX
 SG_ PropulsionSystemActive : 8|2@1+ (1,0) [0|3] "" Vector__XXX
 SG_ StoredEnergySourceLevel : 32|8@1+ (0.4,0) [0|100] "%" Vector__XXX
 SG_ StrdEnrgSrInrsngMdAllwd : 28|2@1+ (1,0) [0|3] "" Vector__XXX
 SG_ StrdEnrgSrOnlMdAllwd : 26|2@1+ (1,0) [0|3] "" Vector__XXX

BO_ 2566702078 GFI4: 8 Vector__XXX
 SG_ SupplyGasMethanePercentage : 0|16@1+ (0.0025,0) [0|160.6375] "%" Vector__XXX

BO_ 2566702334 A2SCREGT2: 8 Vector__XXX
 SG_ Aftrtrtmnt2SCRIntrmdtTmprtr : 0|16@1+ (0.03125,-273) [-273|1734.96875] "degC" Vector__XXX
 SG_ Atttt2SCRItdtTptPFMI : 16|5@1+ (1,0) [0|31] "binary" Vector__XXX

BO_ 2566702590 A1SCREGT2: 8 Vector__XXX
 SG_ Aftrtrtmnt1SCRIntrmdtTmprtr : 0|16@1+ (0.03125,-273) [-273|1734.96875] "degC" Vector__XXX
 SG_ Atttt1SCRItdtTptPFMI : 16|5@1+ (1,0) [0|31] "binary" Vector__XXX

BO_ 2566703358 EEC13: 8 Vector__XXX
 SG_ EngineDualFuelMode : 16|2@1+ (1,0) [0|3] "" Vector__XXX
 SG_ EngineFuelingInhibitAllowed : 2|2@1+ (1,0) [0|3] "" Vector__XXX
 SG_ EngnFlngDsrdRqstCnt : 36|4@1+ (1,0) [0|15] "" Vector__XXX
 SG_ EngnFlngInhtPrvntdRsn : 4|4@1+ (1,0) [0|15] "" Vector__XXX
 SG_ EngnFlngInhtPrvntdRsnExtnsn : 18|6@1+ (1,0) [0|63] "" Vector__XXX
 SG_ EngnFlngInhtRqstCnt : 32|4@1+ (1,0) [0|15] "" Vector__XXX
 SG_ EngnGsSstttnFlPrntg : 24|8@1+ (0.5,0) [0|125] "%" Vector__XXX
 SG_ EngnPrttnDrtOvrrdStts : 40|2@1+ (1,0) [0|3] "" Vector__XXX
 SG_ FeedbackEngineFuelingState : 0|2@1+ (1,0) [0|3] "" Vector__XXX
 SG_ SrAddrssfCntrllngDvfrFlngStt : 8|8@1+ (1,0) [0|255] "SA" Vector__XXX
 SG_ RemainingEngineMotoringTime : 42|6@1+ (1,0) [0|58] "s" Vector__XXX
 SG_ EnginePerformanceBiasLevel : 48|8@1+ (0.4,0) [0|100] "%" Vector__XXX
 SG_ MinimumEngineMotoringSpeed : 56|8@1+ (10,0) [0|2500] "rpm" Vector__XXX

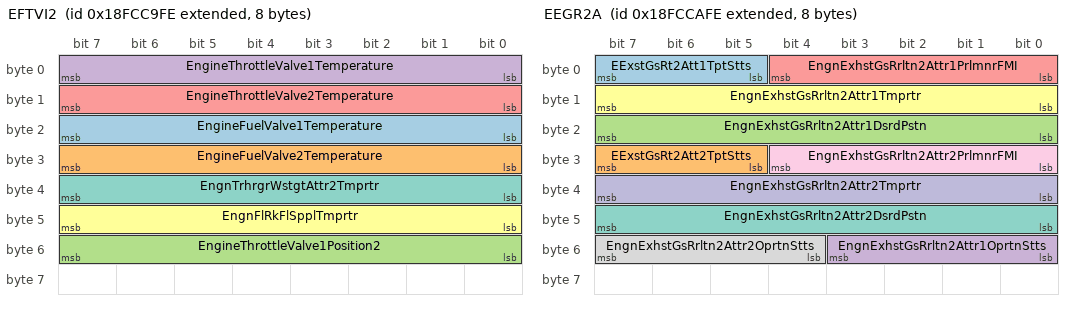
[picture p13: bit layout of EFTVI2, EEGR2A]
BO_ 2566703614 EFTVI2: 8 Vector__XXX
 SG_ EngineFuelValve1Temperature : 16|8@1+ (1,-40) [-40|210] "degC" Vector__XXX
 SG_ EngineFuelValve2Temperature : 24|8@1+ (1,-40) [-40|210] "degC" Vector__XXX
 SG_ EngineThrottleValve1Position2 : 48|8@1+ (0.4,0) [0|100] "%" Vector__XXX
 SG_ EngineThrottleValve1Temperature : 0|8@1+ (1,-40) [-40|210] "degC" Vector__XXX
 SG_ EngineThrottleValve2Temperature : 8|8@1+ (1,-40) [-40|210] "degC" Vector__XXX
 SG_ EngnFlRkFlSpplTmprtr : 40|8@1+ (1,-40) [-40|210] "degC" Vector__XXX
 SG_ EngnTrhrgrWstgtAttr2Tmprtr : 32|8@1+ (1,-40) [-40|210] "degC" Vector__XXX

BO_ 2566703870 EEGR2A: 8 Vector__XXX
 SG_ EExstGsRt2Att1TptStts : 5|3@1+ (1,0) [0|7] "" Vector__XXX
 SG_ EExstGsRt2Att2TptStts : 29|3@1+ (1,0) [0|7] "" Vector__XXX
 SG_ EngnExhstGsRrltn2Attr1DsrdPstn : 16|8@1+ (0.4,0) [0|100] "%" Vector__XXX
 SG_ EngnExhstGsRrltn2Attr1OprtnStts : 48|4@1+ (1,0) [0|15] "" Vector__XXX
 SG_ EngnExhstGsRrltn2Attr1PrlmnrFMI : 0|5@1+ (1,0) [0|31] "binary" Vector__XXX
 SG_ EngnExhstGsRrltn2Attr1Tmprtr : 8|8@1+ (1,-40) [-40|210] "degC" Vector__XXX
 SG_ EngnExhstGsRrltn2Attr2DsrdPstn : 40|8@1+ (0.4,0) [0|100] "%" Vector__XXX
 SG_ EngnExhstGsRrltn2Attr2OprtnStts : 52|4@1+ (1,0) [0|15] "" Vector__XXX
 SG_ EngnExhstGsRrltn2Attr2PrlmnrFMI : 24|5@1+ (1,0) [0|31] "binary" Vector__XXX
 SG_ EngnExhstGsRrltn2Attr2Tmprtr : 32|8@1+ (1,-40) [-40|210] "degC" Vector__XXX

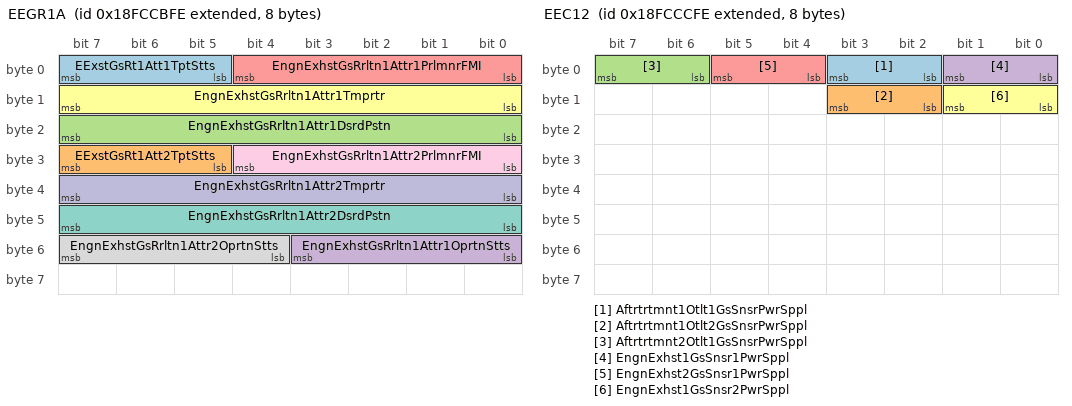
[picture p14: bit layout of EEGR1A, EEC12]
BO_ 2566704126 EEGR1A: 8 Vector__XXX
 SG_ EExstGsRt1Att1TptStts : 5|3@1+ (1,0) [0|7] "" Vector__XXX
 SG_ EExstGsRt1Att2TptStts : 29|3@1+ (1,0) [0|7] "" Vector__XXX
 SG_ EngnExhstGsRrltn1Attr1DsrdPstn : 16|8@1+ (0.4,0) [0|100] "%" Vector__XXX
 SG_ EngnExhstGsRrltn1Attr1OprtnStts : 48|4@1+ (1,0) [0|15] "" Vector__XXX
 SG_ EngnExhstGsRrltn1Attr1PrlmnrFMI : 0|5@1+ (1,0) [0|31] "binary" Vector__XXX
 SG_ EngnExhstGsRrltn1Attr1Tmprtr : 8|8@1+ (1,-40) [-40|210] "degC" Vector__XXX
 SG_ EngnExhstGsRrltn1Attr2DsrdPstn : 40|8@1+ (0.4,0) [0|100] "%" Vector__XXX
 SG_ EngnExhstGsRrltn1Attr2OprtnStts : 52|4@1+ (1,0) [0|15] "" Vector__XXX
 SG_ EngnExhstGsRrltn1Attr2PrlmnrFMI : 24|5@1+ (1,0) [0|31] "binary" Vector__XXX
 SG_ EngnExhstGsRrltn1Attr2Tmprtr : 32|8@1+ (1,-40) [-40|210] "degC" Vector__XXX

BO_ 2566704382 EEC12: 8 Vector__XXX
 SG_ Aftrtrtmnt1Otlt1GsSnsrPwrSppl : 2|2@1+ (1,0) [0|3] "" Vector__XXX
 SG_ Aftrtrtmnt1Otlt2GsSnsrPwrSppl : 10|2@1+ (1,0) [0|3] "" Vector__XXX
 SG_ Aftrtrtmnt2Otlt1GsSnsrPwrSppl : 6|2@1+ (1,0) [0|3] "" Vector__XXX
 SG_ EngnExhst1GsSnsr1PwrSppl : 0|2@1+ (1,0) [0|3] "" Vector__XXX
 SG_ EngnExhst2GsSnsr1PwrSppl : 4|2@1+ (1,0) [0|3] "" Vector__XXX
 SG_ EngnExhst1GsSnsr2PwrSppl : 8|2@1+ (1,0) [0|3] "" Vector__XXX

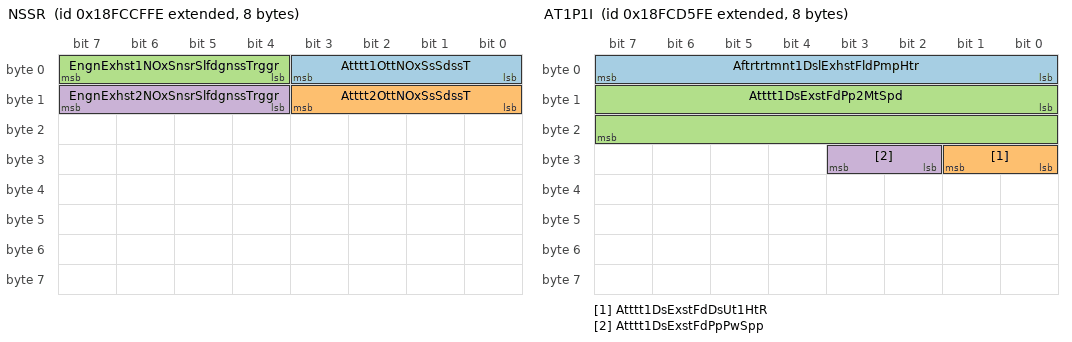
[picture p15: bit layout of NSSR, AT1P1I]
BO_ 2566705150 NSSR: 8 Vector__XXX
 SG_ Atttt1OttNOxSsSdssT : 0|4@1+ (1,0) [0|15] "" Vector__XXX
 SG_ Atttt2OttNOxSsSdssT : 8|4@1+ (1,0) [0|15] "" Vector__XXX
 SG_ EngnExhst1NOxSnsrSlfdgnssTrggr : 4|4@1+ (1,0) [0|15] "" Vector__XXX
 SG_ EngnExhst2NOxSnsrSlfdgnssTrggr : 12|4@1+ (1,0) [0|15] "" Vector__XXX

BO_ 2566705406 EPSI: 8 Vector__XXX
 SG_ Aftrtrtmnt1PrtltSnsr : 0|16@1+ (0.0125,0) [0|803.1875] "mg/(m*m*m)" Vector__XXX
 SG_ Aftrtrtmnt1PrtltSnsrCrrnt : 32|16@1+ (0.00390625,0) [0|250.99609375] "micro A" Vector__XXX
 SG_ Aftrtrtmnt2PrtltSnsr : 16|16@1+ (0.0125,0) [0|803.1875] "mg/(m*m*m)" Vector__XXX

BO_ 2566706686 AT1P1I: 8 Vector__XXX
 SG_ Aftrtrtmnt1DslExhstFldPmpHtr : 0|8@1+ (0.4,0) [0|100] "%" Vector__XXX
 SG_ Atttt1DsExstFdDsUt1HtR : 24|2@1+ (1,0) [0|3] "" Vector__XXX
 SG_ Atttt1DsExstFdPp2MtSpd : 8|16@1+ (0.5,0) [0|32127.5] "rpm" Vector__XXX
 SG_ Atttt1DsExstFdPpPwSpp : 26|2@1+ (1,0) [0|3] "" Vector__XXX

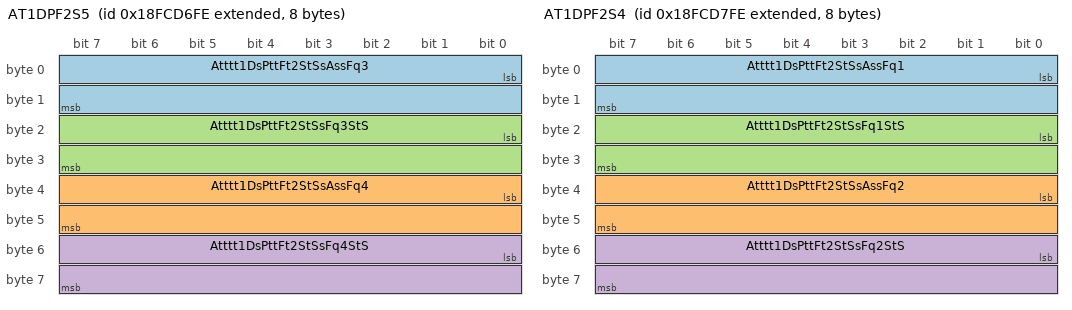
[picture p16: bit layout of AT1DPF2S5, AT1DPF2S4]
BO_ 2566706942 AT1DPF2S5: 8 Vector__XXX
 SG_ Atttt1DsPttFt2StSsAssFq3 : 0|16@1+ (0.1,0) [0|6425.5] "MHz" Vector__XXX
 SG_ Atttt1DsPttFt2StSsAssFq4 : 32|16@1+ (0.1,0) [0|6425.5] "MHz" Vector__XXX
 SG_ Atttt1DsPttFt2StSsFq3StS : 16|16@1+ (0.0025,0) [0|160.6375] "%" Vector__XXX
 SG_ Atttt1DsPttFt2StSsFq4StS : 48|16@1+ (0.0025,0) [0|160.6375] "%" Vector__XXX

BO_ 2566707198 AT1DPF2S4: 8 Vector__XXX
 SG_ Atttt1DsPttFt2StSsAssFq1 : 0|16@1+ (0.1,0) [0|6425.5] "MHz" Vector__XXX
 SG_ Atttt1DsPttFt2StSsAssFq2 : 32|16@1+ (0.1,0) [0|6425.5] "MHz" Vector__XXX
 SG_ Atttt1DsPttFt2StSsFq1StS : 16|16@1+ (0.0025,0) [0|160.6375] "%" Vector__XXX
 SG_ Atttt1DsPttFt2StSsFq2StS : 48|16@1+ (0.0025,0) [0|160.6375] "%" Vector__XXX

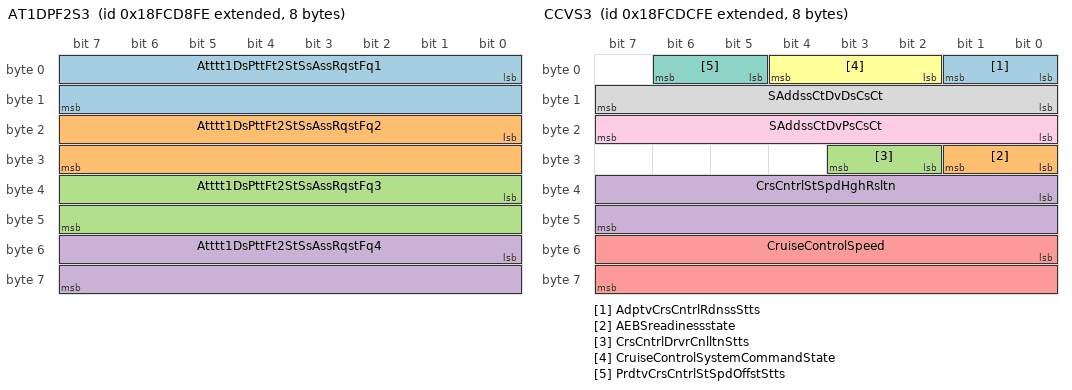
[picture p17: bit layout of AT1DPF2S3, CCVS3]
BO_ 2566707454 AT1DPF2S3: 8 Vector__XXX
 SG_ Atttt1DsPttFt2StSsAssRqstFq1 : 0|16@1+ (0.1,0) [0|6425.5] "MHz" Vector__XXX
 SG_ Atttt1DsPttFt2StSsAssRqstFq2 : 16|16@1+ (0.1,0) [0|6425.5] "MHz" Vector__XXX
 SG_ Atttt1DsPttFt2StSsAssRqstFq3 : 32|16@1+ (0.1,0) [0|6425.5] "MHz" Vector__XXX
 SG_ Atttt1DsPttFt2StSsAssRqstFq4 : 48|16@1+ (0.1,0) [0|6425.5] "MHz" Vector__XXX

BO_ 2566707710 AT1DPF1S5: 8 Vector__XXX
 SG_ Atttt1DsPttFt1StSsAssFq3 : 0|16@1+ (0.1,0) [0|6425.5] "MHz" Vector__XXX
 SG_ Atttt1DsPttFt1StSsAssFq4 : 32|16@1+ (0.1,0) [0|6425.5] "MHz" Vector__XXX
 SG_ Atttt1DsPttFt1StSsFq3StS : 16|16@1+ (0.0025,0) [0|160.6375] "%" Vector__XXX
 SG_ Atttt1DsPttFt1StSsFq4StS : 48|16@1+ (0.0025,0) [0|160.6375] "%" Vector__XXX

BO_ 2566707966 AT1DPF1S4: 8 Vector__XXX
 SG_ Atttt1DsPttFt1StSsAssFq1 : 0|16@1+ (0.1,0) [0|6425.5] "MHz" Vector__XXX
 SG_ Atttt1DsPttFt1StSsAssFq2 : 32|16@1+ (0.1,0) [0|6425.5] "MHz" Vector__XXX
 SG_ Atttt1DsPttFt1StSsFq1StS : 16|16@1+ (0.0025,0) [0|160.6375] "%" Vector__XXX
 SG_ Atttt1DsPttFt1StSsFq2StS : 48|16@1+ (0.0025,0) [0|160.6375] "%" Vector__XXX

BO_ 2566708222 AT1DPF1S3: 8 Vector__XXX
 SG_ Atttt1DsPttFt1StSsAssRqstFq1 : 0|16@1+ (0.1,0) [0|6425.5] "MHz" Vector__XXX
 SG_ Atttt1DsPttFt1StSsAssRqstFq2 : 16|16@1+ (0.1,0) [0|6425.5] "MHz" Vector__XXX
 SG_ Atttt1DsPttFt1StSsAssRqstFq3 : 32|16@1+ (0.1,0) [0|6425.5] "MHz" Vector__XXX
 SG_ Atttt1DsPttFt1StSsAssRqstFq4 : 48|16@1+ (0.1,0) [0|6425.5] "MHz" Vector__XXX

BO_ 2566708478 CCVS3: 8 Vector__XXX
 SG_ AdptvCrsCntrlRdnssStts : 0|2@1+ (1,0) [0|3] "" Vector__XXX
 SG_ AEBSreadinessstate : 24|2@1+ (1,0) [0|3] "" Vector__XXX
 SG_ CrsCntrlDrvrCnlltnStts : 26|2@1+ (1,0) [0|3] "" Vector__XXX
 SG_ CrsCntrlStSpdHghRsltn : 32|16@1+ (0.00390625,0) [0|250.996] "km/h" Vector__XXX
 SG_ CruiseControlSpeed : 48|16@1+ (0.00390625,0) [0|250.996] "km/h" Vector__XXX
 SG_ CruiseControlSystemCommandState : 2|3@1+ (1,0) [0|7] "" Vector__XXX
 SG_ PrdtvCrsCntrlStSpdOffstStts : 5|2@1+ (1,0) [0|3] "" Vector__XXX
 SG_ SAddssCtDvDsCsCt : 8|8@1+ (1,0) [0|255] "SA" Vector__XXX
 SG_ SAddssCtDvPsCsCt : 16|8@1+ (1,0) [0|255] "SA" Vector__XXX

BO_ 2566708734 AT2AC3: 8 Vector__XXX
 SG_ Aftrtrtmnt2SndrArAsltPrssr : 0|16@1+ (0.1,0) [0|6425.5] "kPa" Vector__XXX

BO_ 2566708990 AT1AC3: 8 Vector__XXX
 SG_ Aftrtrtmnt1SndrArAsltPrssr : 0|16@1+ (0.1,0) [0|6425.5] "kPa" Vector__XXX
 SG_ OprtrIndmntOvrrdRnwlRqrd : 16|2@1+ (1,0) [0|3] "" Vector__XXX

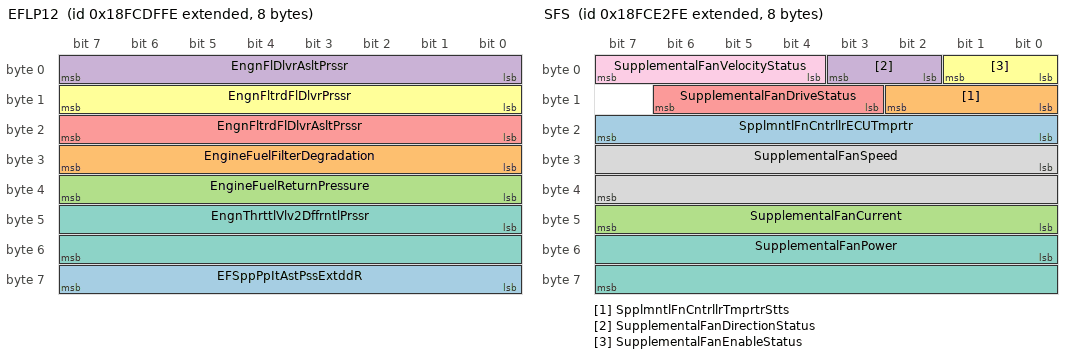
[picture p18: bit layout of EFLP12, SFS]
BO_ 2566709246 EFLP12: 8 Vector__XXX
 SG_ EFSppPpItAstPssExtddR : 56|8@1+ (5,0) [0|1250] "kPa" Vector__XXX
 SG_ EngineFuelFilterDegradation : 24|8@1+ (1,0) [0|250] "%" Vector__XXX
 SG_ EngineFuelReturnPressure : 32|8@1+ (1.64,-7) [-7|403] "kPa" Vector__XXX
 SG_ EngnFlDlvrAsltPrssr : 0|8@1+ (4,0) [0|1000] "kPa" Vector__XXX
 SG_ EngnFltrdFlDlvrAsltPrssr : 16|8@1+ (4,0) [0|1000] "kPa" Vector__XXX
 SG_ EngnFltrdFlDlvrPrssr : 8|8@1+ (4,0) [0|1000] "kPa" Vector__XXX
 SG_ EngnThrttlVlv2DffrntlPrssr : 40|16@1+ (0.1,0) [0|6425.5] "kPa" Vector__XXX

BO_ 2566709502 DPFC2: 8 Vector__XXX
 SG_ Aftertreatment1FuelMassRate : 32|16@1+ (0.05,0) [0|3212.75] "g/min" Vector__XXX
 SG_ Aftertreatment2FuelMassRate : 48|16@1+ (0.05,0) [0|3212.75] "g/min" Vector__XXX
 SG_ Atttt1DsPttFtItTptStPt : 0|16@1+ (0.03125,-273) [-273|1734.96875] "degC" Vector__XXX
 SG_ EngineUnburnedFuelPercentage : 16|16@1+ (0.0025,0) [0|160.6375] "%" Vector__XXX

BO_ 2566709758 LFE2: 8 Vector__XXX
 SG_ EngineDieselFuelDemandRate : 32|16@1+ (0.05,0) [0|3212.75] "l/h" Vector__XXX
 SG_ EngineFuelRateHighResolution : 0|32@1+ (0.001,0) [0|4211081.215] "l/h" Vector__XXX

BO_ 2566710014 SFS: 8 Vector__XXX
 SG_ SpplmntlFnCntrllrECUTmprtr : 16|8@1+ (1,-40) [-40|210] "degC" Vector__XXX
 SG_ SpplmntlFnCntrllrTmprtrStts : 8|3@1+ (1,0) [0|7] "" Vector__XXX
 SG_ SupplementalFanCurrent : 40|8@1+ (1,-125) [-125|125] "A" Vector__XXX
 SG_ SupplementalFanDirectionStatus : 2|2@1+ (1,0) [0|3] "" Vector__XXX
 SG_ SupplementalFanDriveStatus : 11|4@1+ (1,0) [0|15] "" Vector__XXX
 SG_ SupplementalFanEnableStatus : 0|2@1+ (1,0) [0|3] "" Vector__XXX
 SG_ SupplementalFanPower : 48|16@1+ (0.5,0) [0|32127.5] "W" Vector__XXX
 SG_ SupplementalFanSpeed : 24|16@1+ (0.5,0) [0|32127.5] "rpm" Vector__XXX
 SG_ SupplementalFanVelocityStatus : 4|4@1+ (1,0) [0|15] "" Vector__XXX

BO_ 2566710526 EFP: 8 Vector__XXX
 SG_ EngineFuelDensity : 16|16@1+ (0.00003052,0) [0|1.961] "g/cc" Vector__XXX
 SG_ EngineFuelDynamicViscosity : 0|16@1+ (0.015625,0) [0|1003.984375] "Cp" Vector__XXX
 SG_ EngnFl1Tmprtr1HghRsltn : 48|16@1+ (0.03125,-273) [-273|1734.96875] "degC" Vector__XXX
 SG_ EngnFlDltrtHghRsltn : 32|16@1+ (0.0001220703125,0) [0|7.844] "" Vector__XXX

BO_ 2566710782 HOP: 8 Vector__XXX
 SG_ HdrlOlRltvDltrtHghRsltn : 32|16@1+ (0.0001220703125,0) [0|7.844] "" Vector__XXX
 SG_ HdrlOlTmprtrHghRsltn : 48|16@1+ (0.03125,-273) [-273|1734.96875] "degC" Vector__XXX
 SG_ HydraulicOilDensity : 16|16@1+ (0.00003052,0) [0|1.961] "g/cc" Vector__XXX
 SG_ HydraulicOilDynamicViscosity : 0|16@1+ (0.015625,0) [0|1003.984375] "Cp" Vector__XXX

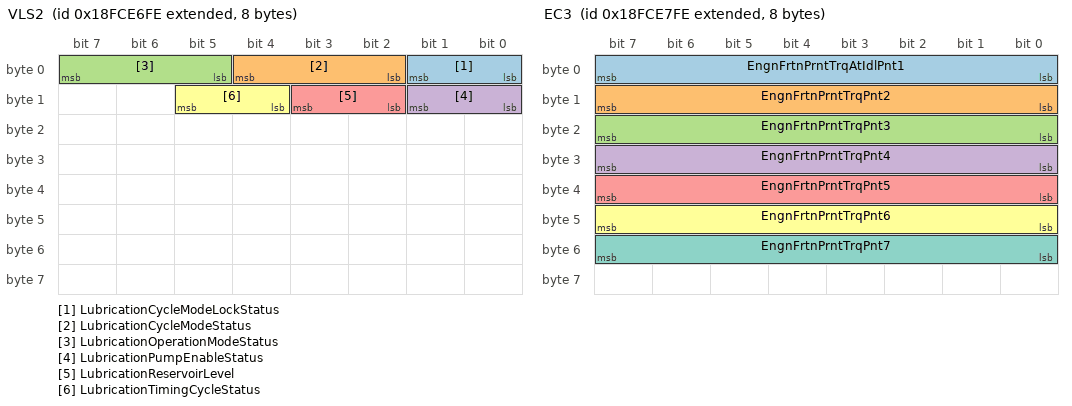
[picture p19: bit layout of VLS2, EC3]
BO_ 2566711038 VLS2: 8 Vector__XXX
 SG_ LubricationCycleModeLockStatus : 0|2@1+ (1,0) [0|3] "" Vector__XXX
 SG_ LubricationCycleModeStatus : 2|3@1+ (1,0) [0|7] "" Vector__XXX
 SG_ LubricationOperationModeStatus : 5|3@1+ (1,0) [0|7] "" Vector__XXX
 SG_ LubricationPumpEnableStatus : 8|2@1+ (1,0) [0|3] "" Vector__XXX
 SG_ LubricationReservoirLevel : 10|2@1+ (1,0) [0|3] "" Vector__XXX
 SG_ LubricationTimingCycleStatus : 12|2@1+ (1,0) [0|3] "" Vector__XXX

BO_ 2566711294 EC3: 8 Vector__XXX
 SG_ EngnFrtnPrntTrqAtIdlPnt1 : 0|8@1+ (1,-125) [-125|125] "%" Vector__XXX
 SG_ EngnFrtnPrntTrqPnt2 : 8|8@1+ (1,-125) [-125|125] "%" Vector__XXX
 SG_ EngnFrtnPrntTrqPnt3 : 16|8@1+ (1,-125) [-125|125] "%" Vector__XXX
 SG_ EngnFrtnPrntTrqPnt4 : 24|8@1+ (1,-125) [-125|125] "%" Vector__XXX
 SG_ EngnFrtnPrntTrqPnt5 : 32|8@1+ (1,-125) [-125|125] "%" Vector__XXX
 SG_ EngnFrtnPrntTrqPnt6 : 40|8@1+ (1,-125) [-125|125] "%" Vector__XXX
 SG_ EngnFrtnPrntTrqPnt7 : 48|8@1+ (1,-125) [-125|125] "%" Vector__XXX

BO_ 2566711550 IVAC: 8 Vector__XXX
 SG_ ItVvAttSstOPss1SdCt : 0|2@1+ (1,0) [0|3] "" Vector__XXX
 SG_ ItVvAttSstOPss2SdCt : 2|2@1+ (1,0) [0|3] "" Vector__XXX

CM_ BO_ 2566670334 "Monitored Tire Information";
CM_ SG_ 2566670334 Axle10MonitoredTireCount "Axle 10 Monitored Tire Count: The number of tires on Axle 10 which are monitored by the tire monitor controller. The axle number increments from front to rear of the vehicle when facing the vehicle in the forward vehicle travel orientation. If the ax...";
CM_ SG_ 2566670334 Axle11MonitoredTireCount "Axle 11 Monitored Tire Count: The number of tires on Axle 11 which are monitored by the tire monitor controller. The axle number increments from front to rear of the vehicle when facing the vehicle in the forward vehicle travel orientation. If the ax...";
CM_ SG_ 2566670334 Axle12MonitoredTireCount "Axle 12 Monitored Tire Count: The number of tires on Axle 12 which are monitored by the tire monitor controller. The axle number increments from front to rear of the vehicle when facing the vehicle in the forward vehicle travel orientation. If the ax...";
CM_ SG_ 2566670334 Axle1MonitoredTireCount "Axle 1 Monitored Tire Count: The number of tires on Axle 1 which are monitored by the tire monitor controller. The axle number increments from front to rear of the vehicle when facing the vehicle in the forward vehicle travel orientation. If the axle...";
CM_ SG_ 2566670334 Axle2MonitoredTireCount "Axle 2 Monitored Tire Count: The number of tires on Axle 2 which are monitored by the tire monitor controller. The axle number increments from front to rear of the vehicle when facing the vehicle in the forward vehicle travel orientation. If the axle...";
CM_ SG_ 2566670334 Axle3MonitoredTireCount "Axle 3 Monitored Tire Count: The number of tires on Axle 3 which are monitored by the tire monitor controller. The axle number increments from front to rear of the vehicle when facing the vehicle in the forward vehicle travel orientation. If the axle...";
CM_ SG_ 2566670334 Axle4MonitoredTireCount "Axle 4 Monitored Tire Count: The number of tires on Axle 4 which are monitored by the tire monitor controller. The axle number increments from front to rear of the vehicle when facing the vehicle in the forward vehicle travel orientation. If the axle...";
CM_ SG_ 2566670334 Axle5MonitoredTireCount "Axle 5 Monitored Tire Count: The number of tires on Axle 5 which are monitored by the tire monitor controller. The axle number increments from front to rear of the vehicle when facing the vehicle in the forward vehicle travel orientation. If the axle...";
CM_ SG_ 2566670334 Axle6MonitoredTireCount "Axle 6 Monitored Tire Count: The number of tires on Axle 6 which are monitored by the tire monitor controller. The axle number increments from front to rear of the vehicle when facing the vehicle in the forward vehicle travel orientation. If the axle...";
CM_ SG_ 2566670334 Axle7MonitoredTireCount "Axle 7 Monitored Tire Count: The number of tires on Axle 7 which are monitored by the tire monitor controller. The axle number increments from front to rear of the vehicle when facing the vehicle in the forward vehicle travel orientation. If the axle...";
CM_ SG_ 2566670334 Axle8MonitoredTireCount "Axle 8 Monitored Tire Count: The number of tires on Axle 8 which are monitored by the tire monitor controller. The axle number increments from front to rear of the vehicle when facing the vehicle in the forward vehicle travel orientation. If the axle...";
CM_ SG_ 2566670334 Axle9MonitoredTireCount "Axle 9 Monitored Tire Count: The number of tires on Axle 9 which are monitored by the tire monitor controller. The axle number increments from front to rear of the vehicle when facing the vehicle in the forward vehicle travel orientation. If the axle...";
CM_ SG_ 2566670334 NumberofAxlesontheVehicle "Number of Axles on the Vehicle: The number of axles monitored for tire parameters. A maximum of 12 axles is defined.";
CM_ SG_ 2566670334 NumberofTiresontheVehicle "Number of Tires on the Vehicle: The total number of tires monitored for tire parameters. A maximum of 250 tires is defined.";
CM_ BO_ 2566670590 "Aftertreatment 2 Historical Information 2";
CM_ SG_ 2566670590 Atttt2SCRSstAvDstBtwSstCEvts "Aftertreatment 2 SCR System Average Distance Between System Cleaning Events: Indicates the average distance since last reset between cleaning events for the SCR system in bank 2.If the manufacturer allows this parameter to be reset, this distance is ...";
CM_ SG_ 2566670590 Atttt2SCRSstAvTBtwSstCEvts "Aftertreatment 2 SCR System Average Time Between System Cleaning Events: Indicates the average time since last reset between cleaning events for the SCR system in bank 2.If the manufacturer allows this parameter to be reset, this time is the average ...";
CM_ SG_ 2566670590 Atttt2SCRSstTtNSstCEvts "Aftertreatment 2 SCR System Total Number of System Cleaning Events: Total number of cleaning events that have occurred on the SCR system in bank 2 over the lifetime of the device.";
CM_ SG_ 2566670590 Atttt2SCRSstTtNSstCItRqsts "Aftertreatment 2 SCR System Total Number of System Cleaning Inhibit Requests: Total number of cleaning inhibit requests on the SCR system in bank 2 by the operator over the lifetime of the device.";
CM_ SG_ 2566670590 Atttt2SCRSstTtNSstCMRqsts "Aftertreatment 2 SCR System Total Number of System Cleaning Manual Requests: Total number of manual cleaning requests on the SCR system in bank 2 by the operator over the lifetime of the device.";
CM_ SG_ 2566670590 Atttt2SCRSstTtSstCT "Aftertreatment 2 SCR System Total System Cleaning Time: Total amount of time that a cleaning event has been active in the SCR system in bank 2 over the lifetime of the device.";
CM_ BO_ 2566670846 "Aftertreatment 1 Historical Information 2";
CM_ SG_ 2566670846 Aftrtrtmnt1SCRSstmTtlClnngTm "Aftertreatment 1 SCR System Total Cleaning Time: Total amount of time that a cleaning event has been active in the SCR system in bank 1 over the lifetime of the device.";
CM_ SG_ 2566670846 Atttt1SCRSstAvDstBtwSstCEvts "Aftertreatment 1 SCR System Average Distance Between System Cleaning Events: Indicates the average distance since last reset between cleaning events for the SCR system in bank 1.If the manufacturer allows this parameter to be reset, this distance is ...";
CM_ SG_ 2566670846 Atttt1SCRSstAvTBtwSstCEvts "Aftertreatment 1 SCR System Average Time Between System Cleaning Events: Indicates the average time since last reset between cleaning events for the SCR system in bank 1. If the manufacturer allows this parameter to be reset, this time is the average...";
CM_ SG_ 2566670846 Atttt1SCRSstTtNSstCEvts "Aftertreatment 1 SCR System Total Number of System Cleaning Events: Total number of cleaning events that have occurred on the SCR system in bank 1 over the lifetime of the device.";
CM_ SG_ 2566670846 Atttt1SCRSstTtNSstCItRqsts "Aftertreatment 1 SCR System Total Number of System Cleaning Inhibit Requests: Total number of cleaning inhibit requests on the SCR system in bank 1 by the operator over the lifetime of the device.";
CM_ SG_ 2566670846 Atttt1SCRSstTtNSstCMRqsts "Aftertreatment 1 SCR System Total Number of System Cleaning Manual Requests: Total number of manual cleaning requests on the SCR system in bank 1 by the operator over the lifetime of the device.";
CM_ SG_ 2566670846 TtlAftrtrtmntOprtngHrs "Total Aftertreatment Operating Hours: Accumulated time of operation of aftertreatment system.  Operating hours are accumulated only when there is air flowing thru the aftertreatment system.";
CM_ BO_ 2566671102 "SCR System Cleaning";
CM_ SG_ 2566671102 Atttt1SCRSstCdtsNtMtAtvC "Aftertreatment 1 SCR System Conditions Not Met for Active Cleaning: Indicates that SCR System 1 is not able to begin or continue an active cleaning event at the current engine operating conditions.00b = SCR System Cleaning not Inhibited01b = SCR Syst...";
CM_ SG_ 2566671102 SCRSstCItdDtAtPdOId "SCR System Cleaning Inhibited Due to Accelerator Pedal Off Idle: Indicates the state of SCR system cleaning inhibition due to the accelerator pedal being off idle.00b = not inhibited01b = inhibited10b = reserved for SAE assignment11b = not availableT...";
CM_ SG_ 2566671102 SCRSstCItdDtLwExstTpt "SCR System Cleaning Inhibited Due to Low Exhaust Temperature: Indicates the state of SCR system cleaning inhibition due to the exhaust temperature being too low.  This implies that the SCR system is too cold for cleaning.00b = not inhibited01b = inhi...";
CM_ SG_ 2566671102 SCRSstCItdDtPtSstLt "SCR System Cleaning Inhibited Due to Permanent System Lockout: Indicates the state of SCR system cleaning inhibition due to a permanent system lockout.00b = not inhibited01b = inhibited10b = reserved for SAE assignment11b = not availableThis SP indic...";
CM_ SG_ 2566671102 SCRSstCItdDtVSpdAvAwdSpd "SCR System Cleaning Inhibited Due to Vehicle Speed Above Allowed Speed: Indicates the state of SCR system cleaning inhibition due to the vehicle speed being above an allowed limit.00b = not inhibited01b = inhibited10b = reserved for SAE assignment11b...";
CM_ SG_ 2566671102 SCRSstCItdDtVSpdBwAwdSpd "SCR System Cleaning Inhibited Due to Vehicle Speed Below Allowed Speed: Indicates the state of SCR system cleaning inhibition due to the vehicle speed being less than the allowed vehicle speed.00b = not inhibited01b = inhibited10b = reserved for SAE ...";
CM_ SG_ 2566671102 SCRSstmClnngAtmtInttnCnfgrtn "SCR System Cleaning Automatic Initiation Configuration: Indicates the configuration of SCR system cleaning automatic initiation.00b = not enabled01b = enabled10b = reserved for SAE assignment11b = not available";
CM_ SG_ 2566671102 SCRSstmClnngInhtdDtClthDsnggd "SCR System Cleaning Inhibited Due to Clutch Disengaged: Indicates the state of SCR system cleaning event inhibition due to the clutch being disengaged.00b = not inhibited01b = inhibited10b = reserved for SAE assignment11b = not availableThis SP indic...";
CM_ SG_ 2566671102 SCRSstmClnngInhtdDtEngnNtWrmdUp "SCR System Cleaning Inhibited Due to Engine Not Warmed Up: Indicates the state of SCR system cleaning inhibition due to the engine not being warmed up.00b = not inhibited01b = inhibited10b = reserved for SAE assignment11b = not availableThis SP indic...";
CM_ SG_ 2566671102 SCRSstmClnngInhtdDtInhtSwth "SCR System Cleaning Inhibited Due to Inhibit Switch: Indicates the state of SCR system cleaning inhibition due to the SCR system cleaning Inhibit Switch.00b = not inhibited01b = inhibited10b = reserved for SAE assignment11b = not availableThis SP ind...";
CM_ SG_ 2566671102 SCRSstmClnngInhtdDtOtfNtrl "SCR System Cleaning Inhibited Due to Out of Neutral: Indicates the state of SCR system cleaning inhibition due to the accelerator pedal being out of neutral.00b = not inhibited01b = inhibited10b = reserved for SAE assignment11b = not availableThis SP...";
CM_ SG_ 2566671102 SCRSstmClnngInhtdDtPrkngBrkNtSt "SCR System Cleaning Inhibited Due to Parking Brake Not Set: Indicates the state of SCR system cleaning inhibition due to the parking brake being not set.00b = not inhibited01b = inhibited10b = reserved for SAE assignment11b = not availableThis SP ind...";
CM_ SG_ 2566671102 SCRSstmClnngInhtdDtPTOAtv "SCR System Cleaning Inhibited Due to PTO Active: Indicates the state of SCR system cleaning inhibition due to the PTO being active.00b = not inhibited01b = inhibited10b = reserved for SAE assignment11b = not availableThis SP indicates the reason for ...";
CM_ SG_ 2566671102 SCRSstmClnngInhtdDtSrvBrkAtv "SCR System Cleaning Inhibited Due to Service Brake Active: Indicates the state of SCR system cleaning inhibition due to the service brake being active.00b = not inhibited01b = inhibited10b = reserved for SAE assignment11b = not availableThis SP indic...";
CM_ SG_ 2566671102 SCRSstmClnngInhtdDtSstmFltAtv "SCR System Cleaning Inhibited Due to System Fault Active: Indicates the state of SCR system cleaning inhibition due to a system fault being active.00b = not inhibited01b = inhibited10b = reserved for SAE assignment11b = not availableThis SP indicates...";
CM_ SG_ 2566671102 SCRSstmClnngInhtdDtSstmTmt "SCR System Cleaning Inhibited Due to System Timeout: Indicates the state of SCR system cleaning inhibition due to a system timeout.00b = not inhibited01b = inhibited10b = reserved for SAE assignment11b = not availableThis SP indicates the reason for ...";
CM_ SG_ 2566671102 SCRSstmClnngInhtdDtTmprrSstmLkt "SCR System Cleaning Inhibited Due to Temporary System Lockout: Indicates the state of SCR system cleaning inhibition due to a temporary system lockout.00b = not inhibited01b = inhibited10b = reserved for SAE assignment11b = not availableThis SP indic...";
CM_ SG_ 2566671102 SCRSstmClnngInhtdStts "SCR System Cleaning Inhibited Status: Indicates the state of SCR system cleaning inhibition.00b = not inhibited01b = inhibited10b = reserved for SAE assignment11b = not availableThis SP indicates the reason for the SCR system cleaning event not being...";
CM_ SG_ 2566671102 SCRSystemCleaningForcedStatus "SCR System Cleaning Forced Status: Indicates the forced execution status of SCR system cleaning.000b = Not Active001b = Active – Forced by Switch (See SPN 3696)010b = Active – Forced by Service Tool 011b = Reserved for SAE Assignment100b = Reserved f...";
CM_ SG_ 2566671102 SCRSystemCleaningLampCommand "SCR System Cleaning Lamp Command: Command to control the SCR system cleaning lamp.000b = Off001b = On – solid010b = reserved for SAE assignment 011b = reserved for SAE assignment100b = On – fast blink (1 HZ)101b = reserved for SAE assignment110b = re...";
CM_ SG_ 2566671102 SCRSystemCleaningStatus "SCR System Cleaning Status: Indicates the state of SCR system cleaning.  This is an aggregate of bank 1 and bank 2.  It is a system status and not individual bank status.00b = not active01b = active10b = SCR system cleaning is needed - automatically ...";
CM_ BO_ 2566671358 "Electronic Engine Controller 17";
CM_ SG_ 2566671358 CylinderFuelRate "Cylinder Fuel Rate: Cylinder fuel rate shall indicate the amount of fuel injected into the cylinder for combustion during the most recent intake stroke of the engine.NOTE: Cylinder fuel rate shall indicate zero mg/stroke when the engine is not runnin...";
CM_ SG_ 2566671358 EngineExhaustFlowRate "Engine Exhaust Flow Rate: Engine Exhaust Flow Rate shall indicate the measured/calculated exhaust gas mass flow upstream of the aftertreatment system.Engine Exhaust Flow Rate shall be calculated as the average exhaust flow rate over the last 1000 mil...";
CM_ SG_ 2566671358 PEMSEngineFuelMassFlowRate "PEMS Engine Fuel Mass Flow Rate: PEMS Engine Fuel Mass Flow Rate shall indicate the amount of fuel consumed by the engine per unit of time (does not include fuel injected directly into the aftertreatment system, but does include fuel injected into th...";
CM_ SG_ 2566671358 VehicleFuelRate "Vehicle Fuel Rate: Vehicle Fuel Rate shall indicate the amount of fuel consumed by the engine and fuel injected directly into the aftertreatment system per unit of time, in grams per second.Vehicle Fuel Rate shall be calculated as the sum of the fuel...";
CM_ BO_ 2566671614 "SCR Operator Inducement Information 3";
CM_ SG_ 2566671614 NSCROptIdtOvdEvtsR "Number of SCR Operator Inducement Override Events Remaining: During an operator inducement event, the operator may be able to override the inducement multiple times. This parameter indicates the remaining number of times that the currently active ind...";
CM_ SG_ 2566671614 SCROprtrIndmntOvrrdEnl "SCR Operator Inducement Override Enable: Indicates if an operator inducement derate is allowed to be overridden.Note: Inducement override is only allowed under certain conditions approved by EPA/ARB.00b = Override not allowed01b = Override allowed10b...";
CM_ SG_ 2566671614 SCROprtrIndmntOvrrdTmRmnng "SCR Operator Inducement Override Time Remaining: This parameter is used to indicate the time remaining during an operator inducement override event.  See also SPN 7344 for an alternate SLOT.When an operator inducement is not active, this parameter in...";
CM_ SG_ 2566671614 TtlNmrfSCROprtrIndmntOvrrdEvnts "Total Number of SCR Operator Inducement Override Events: Indicates total number of operator inducement override events activated throughout the lifetime of engine operation.This number will remain at the maximum value once it is reached.See EU Commis...";
CM_ BO_ 2566671870 "Aftertreatment 2 SCR Dosing System Information 3";
CM_ SG_ 2566671870 Aftrtrtmnt2DslExhstFldDsr2Prssr "Aftertreatment 2 Diesel Exhaust Fluid Doser 2 Pressure: The SCR doser 2 diesel exhaust fluid gage pressure (measured closest to dosing valve) for aftertreatment system 2 (exhaust bank ). This is the gage equivalent to SPN 7464 .";
CM_ SG_ 2566671870 Aftrtrtmnt2DslExhstFldDsrPrssr "Aftertreatment 2 Diesel Exhaust Fluid Doser Pressure: The SCR dosing diesel exhaust fluid gage pressure (measured closest to dosing valve) for aftertreatment system 2 (exhaust bank 2). This is the gage equivalent to SPN 4387.";
CM_ SG_ 2566671870 Atttt2DsExstFdDs2AstPss "Aftertreatment 2 Diesel Exhaust Fluid Doser 2 Absolute Pressure: The SCR doser 2 diesel exhaust fluid absolute pressure (measured closest to dosing valve) for aftertreatment system 2 (exhaust bank 2).";
CM_ SG_ 2566671870 Atttt2DsExstFdDs2Tpt "Aftertreatment 2 Diesel Exhaust Fluid Doser 2 Temperature: The temperature (measured closest to doser valve) of the second DEF doser unit for aftertreatment system 2 (exhaust bank 2).";
CM_ BO_ 2566672126 "Aftertreatment 1 SCR Dosing System Information 3";
CM_ SG_ 2566672126 Aftrtrtmnt1DslExhstFldDsr2Prssr "Aftertreatment 1 Diesel Exhaust Fluid Doser 2 Pressure: The SCR doser 2 diesel exhaust fluid gage pressure (measured closest to dosing valve) for aftertreatment system 1 (exhaust bank 1). This is the gage equivalent to SPN 7459 .";
CM_ SG_ 2566672126 Aftrtrtmnt1DslExhstFldDsrPrssr "Aftertreatment 1 Diesel Exhaust Fluid Doser Pressure: The SCR dosing diesel exhaust fluid gage pressure (measured closest to dosing valve) for aftertreatment system 1 (exhaust bank 1). This is the gage equivalent to SPN 4334.";
CM_ SG_ 2566672126 Atttt1DsExstFdDs2AstPss "Aftertreatment 1 Diesel Exhaust Fluid Doser 2 Absolute Pressure: The SCR doser 2 diesel exhaust fluid absolute pressure (measured closest to dosing valve) for aftertreatment system 1 (exhaust bank 1).";
CM_ SG_ 2566672126 Atttt1DsExstFdDs2Tpt "Aftertreatment 1 Diesel Exhaust Fluid Doser 2 Temperature: The temperature (measured closest to dosing valve) of the second DEF dosing unit for aftertreatment system 1 (exhaust bank 1).";
CM_ BO_ 2566672382 "Payload Weight Sensor Information";
CM_ SG_ 2566672382 PayloadWeightSensor1Status "Payload Weight Sensor 1 Status: Status of the payload system sensor 1 measurement.00b = Sensor fully functional01b = Sensor degraded10b = Error (Sensor failed)11b = Not available";
CM_ SG_ 2566672382 PayloadWeightSensor2Status "Payload Weight Sensor 2 Status: Status of the payload system sensor 2 measurement.00b = Sensor fully functional01b = Sensor degraded10b = Error (Sensor failed)11b = Not available";
CM_ SG_ 2566672382 PayloadWeightSensor3Status "Payload Weight Sensor 3 Status: Status of the payload system sensor 3 measurement.00b = Sensor fully functional01b = Sensor degraded10b = Error (Sensor failed)11b = Not available";
CM_ SG_ 2566672382 PayloadWeightSensor4Status "Payload Weight Sensor 4 Status: Status of the payload system sensor 4 measurement.00b = Sensor fully functional01b = Sensor degraded10b = Error (Sensor failed)11b = Not available";
CM_ SG_ 2566672382 PayloadWeightSensor5Status "Payload Weight Sensor 5 Status: Status of the payload system sensor 5 measurement.00b = Sensor fully functional01b = Sensor degraded10b = Error (Sensor failed)11b = Not available";
CM_ SG_ 2566672382 PayloadWeightSensor6Status "Payload Weight Sensor 6 Status: Status of the payload system sensor 6 measurement.00b = Sensor fully functional01b = Sensor degraded10b = Error (Sensor failed)11b = Not available";
CM_ SG_ 2566672382 PayloadWeightSensor7Status "Payload Weight Sensor 7 Status: Status of the payload system sensor 7 measurement.00b = Sensor fully functional01b = Sensor degraded10b = Error (Sensor failed)11b = Not available";
CM_ SG_ 2566672382 PayloadWeightSensor8Status "Payload Weight Sensor 8 Status: Status of the payload system sensor 8 measurement.00b = Sensor fully functional01b = Sensor degraded10b = Error (Sensor failed)11b = Not available";
CM_ BO_ 2566672638 "Payload System Status";
CM_ SG_ 2566672638 DeliveredPayloadConfidence "Delivered Payload Confidence: The level of confidence of the delivered payload weight measurement. Higher confidence values indicate greater probability the delivered payload weight is the actual weight and providing feedback on the potential for imp...";
CM_ SG_ 2566672638 DeliveredPayloadWeight "Delivered Payload Weight: The delivered payload mass during the last haul cycle. This is the amount of material moved and delivered by a machine is a key work cycle parameter.Delivered payload weight is defined as the last loaded weight less the carr...";
CM_ SG_ 2566672638 HaulCycleCount "Haul Cycle Count: A counter incremented by 1 with each instance of a new haul cycle, defined as a dump to dump cycle. The counter shall increment from 0 to 64255, rolling over to 0 on the next increment after 64255.";
CM_ SG_ 2566672638 HaulModeStatus "Haul Mode Status: The current operating state of the haul cycle.0000b = Not in Haul Mode0001b = Loading -- Payload is being added to the machine0010b = Approaching Loaded -- Machine is near its maximum capacity0011b = Loaded -- Loading operation has ...";
CM_ SG_ 2566672638 PldDlvrTrnstnStts "Payload Delivery Transaction Status: The current state of the payload delivery transaction.When a transaction is in progress, a receiving node may monitor Haul Cycle Count (SPN 6847) and Delivered Payload Weight (SPN 6849) in order to track the progr...";
CM_ BO_ 2566673406 "Engine Gaseous Leakage Information";
CM_ SG_ 2566673406 GasLeakageDetection1Pressure "Gas Leakage Detection 1 Pressure: Pressure measured in gas leakage detection point 1. Measured media is of the gas, meaning it could be air, inert gas, fuel air mixture or charge air mixture, depending on the failure mode detected. The measurement po...";
CM_ SG_ 2566673406 GasLeakageDetection2Pressure "Gas Leakage Detection 2 Pressure: Pressure measured in gas leakage detection point 2. Measured media is of the gas, meaning it could be air, inert gas, fuel air mixture or charge air mixture, depending on the failure mode detected. The second measure...";
CM_ SG_ 2566673406 GasLeakageDetection3Pressure "Gas Leakage Detection 3 Pressure: Pressure measured in gas leakage detection point 3. Measured media is of the gas, meaning it could be air, inert gas, fuel air mixture or charge air mixture, depending on the failure mode detected. The third measurem...";
CM_ SG_ 2566673406 GssFlLkg1Cnntrtn "Gaseous Fuel Leakage 1 Concentration: Percentage of detected gaseous fuel leak compared to the lower explosion limit (LEL). 100% means the measured value is on the lower explosion limit. 0% means no detected gaseous fuel in measurement point. The mea...";
CM_ SG_ 2566673406 GssFlLkg2Cnntrtn "Gaseous Fuel Leakage 2 Concentration: Percentage of detected gaseous fuel leak compared to the lower explosion limit (LEL). 100% means the measured value is on the lower explosion limit. 0% means no detected gaseous fuel in measurement point. The sec...";
CM_ SG_ 2566673406 GssFlLkg3Cnntrtn "Gaseous Fuel Leakage 3 Concentration: Percentage of detected gaseous fuel leak compared to the lower explosion limit (LEL). 100% means the measured value is on the lower explosion limit. 0% means no detected gaseous fuel in measurement point. The thi...";
CM_ BO_ 2566674174 "SCR Operator Inducement Information 2";
CM_ SG_ 2566674174 AftrtrtmntSCRMlfntnTm "Aftertreatment SCR Malfunction Time: Indicates the amount of time an error condition has been active due to a malfunction in the Aftertreatment SCR system.The source of the malfunction condition could be a component failure, detection of tampering, o...";
CM_ SG_ 2566674174 SCROperatorInducementTotalTime "SCR Operator Inducement Total Time: Indicates the time that operator inducement has been active. This will accumulate over the life of the product and will never be reset.";
CM_ BO_ 2566674430 "SCR Operator Inducement Information 1";
CM_ SG_ 2566674430 DslExhstFldQltMlfntnTm "Diesel Exhaust Fluid Quality Malfunction Time: Indicates the amount of time an error has been active due to detection of low Diesel Exhaust Fluid Quality. This will accumulate over the life of the product and will never be reset.";
CM_ SG_ 2566674430 DslExhstFldTnk1EmptTm "Diesel Exhaust Fluid Tank 1 Empty Time: Indicates the time the Diesel Exhaust Fluid Tank 1 Level is indicated as empty. This will accumulate over the life of the product and will never be reset.";
CM_ BO_ 2566674686 "Turbocharger Information 7";
CM_ SG_ 2566674686 EngnTrhrgr2LOlPrssr "Engine Turbocharger 2 Lube Oil Pressure: Gage pressure of oil in the lubrication system for the 2nd turbocharger.";
CM_ SG_ 2566674686 EngnTrhrgr2OlTmprtr "Engine Turbocharger 2 Oil Temperature: Temperature of the lubricant for the second turbocharger.";
CM_ SG_ 2566674686 EngnTrhrgr3LOlPrssr "Engine Turbocharger 3 Lube Oil Pressure: Gage pressure of oil in the lubrication system for the 3rd turbocharger.";
CM_ SG_ 2566674686 EngnTrhrgr4LOlPrssr "Engine Turbocharger 4 Lube Oil Pressure: Gage pressure of oil in the lubrication system for the 4th turbocharger.";
CM_ BO_ 2566675966 "High Voltage Energy Storage System Configuration";
CM_ SG_ 2566675966 HVESSNominalVoltage "HVESS Nominal Voltage: Per the HVES manufacturer, this is the nominal operating voltage of the High Voltage Energy Storage System (or Pack 1 in systems with only one pack), e.g. “300V” or “600V”.This parameter provides HVES system level information. ...";
CM_ SG_ 2566675966 HVESSRmmnddMnmmOprtngVltg "HVESS Recommended Minimum Operating Voltage: Per the HVES manufacturer, this is the minimum recommended voltage level for High Voltage Energy Storage System (or Pack 1 in systems with only one pack) operation.  Operating below this value may compromi...";
CM_ SG_ 2566675966 HVESSRmmnddMxmmOprtngVltg "HVESS Recommended Maximum Operating Voltage: Per the HVES manufacturer, this is the maximum recommended voltage level for High Voltage Energy Storage System (or Pack 1 in systems with only one pack) operation.  Operating above this value may compromi...";
CM_ SG_ 2566675966 HVESSRmmnddMnmmSttOfChrg "HVESS Recommended Minimum State Of Charge: Per the HVES manufacturer, this is the recommended minimum state of charge for High Voltage Energy Storage System (or Pack 1 in systems with only one pack) operation.  Operating below this value may compromi...";
CM_ SG_ 2566675966 HVESSRmmnddMxmmSttOfChrg "HVESS Recommended Maximum State Of Charge: Per the HVES manufacturer, this is the recommended maximum state of charge for High Voltage Energy Storage System (or Pack 1 in systems with only one pack) operation.  Operating above this value may compromi...";
CM_ SG_ 2566675966 HVESSRmmnddMxmmOprtngTmprtr "HVESS Recommended Maximum Operating Temperature: Per the HVES manufacturer, this is the recommended maximum temperature for High Voltage Energy Storage System (or Pack 1 in systems with only one pack) operation.  Operating above this value may damage...";
CM_ SG_ 2566675966 HVESSRmmnddMnmmOprtngTmprtr "HVESS Recommended Minimum Operating Temperature: Per the HVES manufacturer, this is the recommended minimum temperature for High Voltage Energy Storage System (or Pack 1 in systems with only one pack) operation.  Operating below this value may damage...";
CM_ SG_ 2566675966 HVESSCellMaximumVoltageLimit "HVESS Cell Maximum Voltage Limit: Per the HVES manufacturer, this is the maximum cell voltage for High Voltage Energy Storage System (or Pack 1 in systems with only one pack) operation.  Operating above this value may damage HVES hardware, or comprom...";
CM_ SG_ 2566675966 HVESSCellMinimumVoltageLimit "HVESS Cell Minimum Voltage Limit: Per the HVES manufacturer, this is the minimum cell voltage for High Voltage Energy Storage System (or Pack 1 in systems with only one pack) operation.  Operating below this value may damage HVES hardware, or comprom...";
CM_ SG_ 2566675966 HVESSNumberofHVESPsConfigured "HVESS Number of HVESPs Configured: The number of High Voltage Energy Storage Packs that are currently configured in the HVESS system.";
CM_ BO_ 2566687742 "Aftertreatment 1 Particulate Sensor Information 2";
CM_ SG_ 2566687742 Aftrtrtmnt1PrtltSnsrDttnStts "Aftertreatment 1 Particulate Sensor Detection Status: Detection status of the particulate sensor0000b = Initialization for particulate matter detection0001b = Waiting for dew point (see SPN 6784)0010b = Particulate matter detection0011b = Heater is a...";
CM_ SG_ 2566687742 Aftrtrtmnt1PrtltSnsrHtrRsstn "Aftertreatment 1 Particulate Sensor Heater Resistance: The resistance of the particulate sensor heater.";
CM_ SG_ 2566687742 Aftrtrtmnt1PrtltSnsrMxmmRsstn "Aftertreatment 1 Particulate Sensor Maximum Resistance: This is the maximum resistance that the particulate sensor can measure.";
CM_ SG_ 2566687742 Aftrtrtmnt1PrtltSnsrPwrSppl "Aftertreatment 1 Particulate Sensor Power Supply: State signal which indicates when the Aftertreatment 1 particulate sensor has power applied to it. Note that this is referring to the power supplied to the sensor, not the power supplied to the contro...";
CM_ SG_ 2566687742 Aftrtrtmnt1PrtltSnsrTmprtr "Aftertreatment 1 Particulate Sensor Temperature: Temperature of the particulate sensor.";
CM_ SG_ 2566687742 Atttt1PttSsRtFdCt "Aftertreatment 1 Particulate Sensor Regeneration Failed Count: This is the number of times that the particulate sensor regeneration process has been attempted but failed to complete this power cycle.";
CM_ BO_ 2566687998 "Aftertreatment 1 Particulate Sensor Information 1";
CM_ SG_ 2566687998 Aftrtrtmnt1PrtltSnsrAtvAmltnTm "Aftertreatment 1 Particulate Sensor Active Accumulation Time: This is the amount of time since the last successful regeneration completed.  The sensor has been accumulating particulate matter since that time.";
CM_ SG_ 2566687998 Aftrtrtmnt1PrtltSnsrHtrStt "Aftertreatment 1 Particulate Sensor Heater State: The states of the particulate sensor heater.  The heater will change states from 11b to 10b, 10b to 01b, and 01b to 00b in a typical heating event.00b = Heater is in closed loop control01b = Heater is...";
CM_ SG_ 2566687998 Aftrtrtmnt1PrtltSnsrRgnrtnStt "Aftertreatment 1 Particulate Sensor Regeneration State: Indicates if the particulate sensor regeneration is currently active, and if so, the reason for the regeneration.0000b = Regeneration is not active0001b = Regneration is active and has been init...";
CM_ SG_ 2566687998 Aftrtrtmnt1PrtltSnsrRgnrtnStts "Aftertreatment 1 Particulate Sensor Regeneration Status: The status of the most recent attempt of this power cycle to activate the particulate sensor regeneration process. This will not be updated until the regeneration is no longer active, as indica...";
CM_ SG_ 2566687998 Aftrtrtmnt1PrtltSnsrRsstn "Aftertreatment 1 Particulate Sensor Resistance: This sensor is located in the exhaust stream somewhere after the DPF, but not necessarily immediately after the DPF.  It provides a resistance value that can be used to determine particulate matter in t...";
CM_ SG_ 2566687998 Atttt1PttSsTBtwRts "Aftertreatment 1 Particulate Sensor Time Between Regenerations: This is the time between the last two successful regenerations of the particulate sensor for the current power cycle. This parameter reflects the time when the engine was running, not a ...";
CM_ BO_ 2566689278 "Engine Exhaust NOx";
CM_ SG_ 2566689278 EngineExhaustDesiredNOx "Engine Exhaust Desired NOx: Desired NOx concentration in the engine exhaust, prior to any aftertreatment of the exhaust.";
CM_ SG_ 2566689278 EngineExhaustNOx "Engine Exhaust NOx: Calculated NOx concentration for the total engine exhaust, prior to any aftertreatment of the exhaust.  This parameter is primarily intended for engines that have separate NOx sensors in separate exhaust manifolds, but the engine ...";
CM_ SG_ 2566689278 EngnExhstNOxSnsrPwrSppl "Engine Exhaust NOx Sensor Power Supply: State signal which indicates when the engine exhaust NOx sensor power supply driver output is being driven. On means the ECU is powering the engine exhaust NOx sensor. Note that the ECU is external to the senso...";
CM_ BO_ 2566689534 "Air Fuel Ratio";
CM_ SG_ 2566689534 EngineMainChamberAirFuelRatio "Engine Main Chamber Air Fuel Ratio: Actual air to fuel ratio of the charge entering the cylinder main chamber.";
CM_ SG_ 2566689534 EnginePrechamberAirFuelRatio "Engine Prechamber Air Fuel Ratio: Actual air to fuel ratio of the charge entering the cylinder prechamber.";
CM_ SG_ 2566689534 EngnMnChmrDsrdArFlRt "Engine Main Chamber Desired Air Fuel Ratio: Desired air to fuel ratio of the charge entering the cylinder main chamber.";
CM_ SG_ 2566689534 EngnPrhmrDsrdArFlRt "Engine Prechamber Desired Air Fuel Ratio: Desired air to fuel ratio of the charge entering the cylinder prechamber.";
CM_ BO_ 2566689790 "Gaseous Fuel Pressure 2";
CM_ SG_ 2566689790 EngnMnChmrFlAsltPrssr "Engine Main Chamber Fuel Absolute Pressure: Absolute pressure of the gaseous fuel for the main chamber of the cylinder. This parameter is intended for applications, which use a pre and main chamber fuel systems, which report the pressure of more than...";
CM_ SG_ 2566689790 EngnMnChmrFlDsrdAsltPrssr "Engine Main Chamber Fuel Desired Absolute Pressure: Desired absolute pressure of the gaseous fuel for the main chamber of the cylinder. This parameter is intended for applications with pre and main chamber fuel systems, which report the pressure of m...";
CM_ SG_ 2566689790 EngnPrhmrFlAsltPrssr "Engine Prechamber Fuel Absolute Pressure: Absolute pressure of the gaseous fuel for the separate cylinder pre-chamber rail. This parameter is intended for applications, which use a pre and main chamber fuel systems, which report the pressure of more ...";
CM_ SG_ 2566689790 EngnPrhmrFlDsrdAsltPrssr "Engine Prechamber Fuel Desired Absolute Pressure: Desired absolute pressure of the gaseous fuel in the separate cylinder pre-chamber rail. This parameter is intended for applications with pre and main chamber fuel systems, which report the pressure o...";
CM_ BO_ 2566690046 "Aftertreatment System Abuse Information";
CM_ SG_ 2566690046 AfterrunCompleteThisCycle "After-run Complete This Cycle: Indication of after-run routine completion in the current power cycle.Complete This Cycle parameters are used to indicate to the engine controller that is powering the aftertreatment controller via relay that it is ok t...";
CM_ SG_ 2566690046 AttttDsExstFdDsCdwCptLstC "Aftertreatment Diesel Exhaust Fluid Doser Cooldown Complete Last Cycle: Indication of cooldown routine completion in the previous power cycle.00b = Not complete01b = Complete10b = Error11b = Not SupportedNote:  One purpose for tracking the status of ...";
CM_ SG_ 2566690046 AttttDsExstFdDsCdwCptTsC "Aftertreatment Diesel Exhaust Fluid Doser Cooldown Complete This Cycle: Indication of cooldown routine completion in the current power cycle.Complete This Cycle parameters are used to indicate to the engine controller that is powering the aftertreatm...";
CM_ SG_ 2566690046 AttttDsExstFdDsCdwItptCt "Aftertreatment Diesel Exhaust Fluid Doser Cooldown Interrupt Count: Non-volatile record of the number of interrupted cooldown routines since the last clear event.  The counter shall be reset by PGN 56832 request.";
CM_ SG_ 2566690046 AttttDsExstFdDsPCptLstC "Aftertreatment Diesel Exhaust Fluid Doser Purge Complete Last Cycle: Indication of purge routine completion in the previous power cycle00b = Not complete01b = Complete10b = Error11b = Not SupportedNote:  One purpose for tracking the status of the Die...";
CM_ SG_ 2566690046 AttttDsExstFdDsPCptTsC "Aftertreatment Diesel Exhaust Fluid Doser Purge Complete This Cycle: Indication of purge routine completion in the current power cycle.Complete This Cycle parameters are used to indicate to the engine controller that is powering the aftertreatment co...";
CM_ SG_ 2566690046 AttttDsExstFdDsPItptCt "Aftertreatment Diesel Exhaust Fluid Doser Purge Interrupt Count: Non-volatile record of the number of interrupted purge routines since the last clear event.  The counter shall be reset by PGN 56832 request.";
CM_ BO_ 2566690558 "Engine Information 2";
CM_ SG_ 2566690558 EngineCommonRailOilPressure "Engine Common Rail Oil Pressure: Gage pressure of oil in common rail's lubrication system as provided by oil pump.";
CM_ SG_ 2566690558 EngineExhaustPressure2 "Engine Exhaust Pressure 2: Gage pressure of the exhaust gasses as measured at the turbine intake of the turbocharger of exhaust bank 2. See SPN 1209 for exhaust bank 1.";
CM_ SG_ 2566690558 EngnCmmnRlOlAsltPrssr "Engine Common Rail Oil Absolute Pressure: Absolute pressure of oil in common rail's lubrication system as provided by oil pump.";
CM_ SG_ 2566690558 EngnExhstPrssr1ExtnddRng "Engine Exhaust Pressure 1 (Extended Range): Gage pressure of the exhaust gasses as measured at the turbine intake of the turbocharger. This SP to be used for inline engines or exhaust bank 1 of multiple bank engines.  See SPN 1209 for alternate resol...";
CM_ SG_ 2566690558 EOFtItPssHRstExtddR "Engine Oil Filter Intake Pressure (High Resolution/Extended Range): Gage pressure of the engine oil before the oil reaches the oil filter. See SPN 1208 for alternate resolution.";
CM_ BO_ 2566690814 "Electronic Steering Control 2";
CM_ SG_ 2566690814 CircleSteerModeActuatorState "Circle Steer Mode Actuator State: Signal which indicates the current state of the actuator that control the circle steering mode00b = Circle Steer Mode actuator inactive01b = Circle Steer Mode actuator active10b = Error11b = Not Available";
CM_ SG_ 2566690814 CrabSteerModeActuatorState "Crab Steer Mode Actuator State: Signal which indicates the current state of the actuator that control the crab steering mode00b = Crab Steer Mode actuator inactive01b = Crab Steer Mode actuator active10b = Error11b = Not Available";
CM_ SG_ 2566690814 FrontSteeringAxleCenteredStatus "Front Steering Axle Centered Status: The status of the front steering axle being centered. The axle is centered if the axle's centerline is parallel to the vehicle's X-axis, where the vehicle's X-axis is as defined in SAE J67000b = Front Axle Centere...";
CM_ SG_ 2566690814 RearSteeringAxleCenteredStatus "Rear Steering Axle Centered Status: The status of the rear steering axle being centered. The axle is centered if the axle's centerline is parallel to the vehicle's X-axis, where the vehicle's X-axis is as defined in SAE J67000b = Rear Axle Centered01...";
CM_ SG_ 2566690814 StrngCntrllrECUTmprtr "Steering Controller ECU Temperature: Temperature of the steering controller ECU";
CM_ SG_ 2566690814 Wheel2SteerActuatorState "2 Wheel Steer Actuator State: The current state of the actuator that control the 2 wheel steering mode00b = 2 Wheel Steer actuator inactive01b = 2 Wheel Steer actuator active10b = Error11b = Not Available";
CM_ SG_ 2566690814 Wheel4SteerActuatorState "4 Wheel Steer Actuator State: Signal which indicates the current state of the actuator that control the 4 wheel steering mode00b = 4 Wheel Steer actuator inactive01b = 4 Wheel Steer actuator active10b = Error11b = Not Available";
CM_ SG_ 2566690814 RequestedSteeringMode "Requested Steering Mode: The operator's desired steering input to the electronic steering controller. For the individual status parameters, reference Two Wheel, Circle, and Crab Mode Switch Inputs.000b = 2 Wheel Steer Mode001b = Circle Steer Mode010b...";
CM_ SG_ 2566690814 SteeringModeTwoWheelSwitchInput "Steering Mode Two Wheel Switch Input: The status of the Two Wheel Steering Mode input to the ECU for determining the operator requested steering mode.00b = Off01b = On10b = Error11b = Not available";
CM_ SG_ 2566690814 SteeringModeCrabSwitchInput "Steering Mode Crab Switch Input: The status of the Crab Steering Mode input to the ECU for determining the operator requested steering mode.00b = Off01b = On10b = Error11b = Not available";
CM_ SG_ 2566690814 SteeringModeCircleSwitchInput "Steering Mode Circle Switch Input: The status of the Circle Steering Mode input to the ECU for determining the operator requested steering mode00b = Off01b = On10b = Error11b = Not available";
CM_ SG_ 2566690814 SteeringModeStatus "Steering Mode Status: The actual mode of the all-wheel steering system.000b = 2 Wheel Steer Mode001b = Circle Steer Mode010b = Reserved for future use011b = Crab Steer Mode100b = Reserved for future use101b = Reserved for future use110b = Error111b =...";
CM_ BO_ 2566691326 "Assembly Unit Identification";
CM_ SG_ 2566691326 AssemblyUnitIdentification "Assembly Unit Identification: A combination of alphanumeric characters representing the Identification number of an assembly unit installed on a component.  Multiple assembly unit IDs can be transmitted by appropriately setting Number of Assembly Uni...";
CM_ SG_ 2566691326 NmrfAssmlUntIdntftnFlds "Number of Assembly Unit Identification Fields: Number of Assembly Unit Identification designators represented in the Assembly Unit Identification parameter group.";
CM_ BO_ 2566691582 "Joystick 3 Lamp Status";
CM_ SG_ 2566691582 Joystick3Lamp10Status "Joystick 3 Lamp 10 Status: Report the actual value of Joystick 3 Lamp 1000b = Off01b = On10b = Flashing11b = Not available";
CM_ SG_ 2566691582 Joystick3Lamp1Status "Joystick 3 Lamp 1 Status: Report the actual value of Joystick 3 Lamp 100b = Off01b = On10b = Flashing11b = Not available";
CM_ SG_ 2566691582 Joystick3Lamp2Status "Joystick 3 Lamp 2 Status: Report the actual value of Joystick 3 Lamp 200b = Off01b = On10b = Flashing11b = Not available";
CM_ SG_ 2566691582 Joystick3Lamp3Status "Joystick 3 Lamp 3 Status: Report the actual value of Joystick 3 Lamp 300b = Off01b = On10b = Flashing11b = Not available";
CM_ SG_ 2566691582 Joystick3Lamp4Status "Joystick 3 Lamp 4 Status: Report the actual value of Joystick 3 Lamp 400b = Off01b = On10b = Flashing11b = Not available";
CM_ SG_ 2566691582 Joystick3Lamp5Status "Joystick 3 Lamp 5 Status: Report the actual value of Joystick 3 Lamp 500b = Off01b = On10b = Flashing11b = Not available";
CM_ SG_ 2566691582 Joystick3Lamp6Status "Joystick 3 Lamp 6 Status: Report the actual value of Joystick 3 Lamp 600b = Off01b = On10b = Flashing11b = Not available";
CM_ SG_ 2566691582 Joystick3Lamp7Status "Joystick 3 Lamp 7 Status: Report the actual value of Joystick 3 Lamp 700b = Off01b = On10b = Flashing11b = Not available";
CM_ SG_ 2566691582 Joystick3Lamp8Status "Joystick 3 Lamp 8 Status: Report the actual value of Joystick 3 Lamp 800b = Off01b = On10b = Flashing11b = Not available";
CM_ SG_ 2566691582 Joystick3Lamp9Status "Joystick 3 Lamp 9 Status: Report the actual value of Joystick 3 Lamp 900b = Off01b = On10b = Flashing11b = Not available";
CM_ BO_ 2566691838 "Joystick 2 Lamp Status";
CM_ SG_ 2566691838 Joystick2Lamp10Status "Joystick 2 Lamp 10 Status: Report the actual value of Joystick 2 Lamp 1000b = Off01b = On10b = Flashing11b = Not available";
CM_ SG_ 2566691838 Joystick2Lamp1Status "Joystick 2 Lamp 1 Status: Report the actual value of Joystick 2 Lamp 100b = Off01b = On10b = Flashing11b = Not available";
CM_ SG_ 2566691838 Joystick2Lamp2Status "Joystick 2 Lamp 2 Status: Report the actual value of Joystick 2 Lamp 200b = Off01b = On10b = Flashing11b = Not available";
CM_ SG_ 2566691838 Joystick2Lamp3Status "Joystick 2 Lamp 3 Status: Report the actual value of Joystick 2 Lamp 300b = Off01b = On10b = Flashing11b = Not available";
CM_ SG_ 2566691838 Joystick2Lamp4Status "Joystick 2 Lamp 4 Status: Report the actual value of Joystick 2 Lamp 400b = Off01b = On10b = Flashing11b = Not available";
CM_ SG_ 2566691838 Joystick2Lamp5Status "Joystick 2 Lamp 5 Status: Report the actual value of Joystick 2 Lamp 500b = Off01b = On10b = Flashing11b = Not available";
CM_ SG_ 2566691838 Joystick2Lamp6Status "Joystick 2 Lamp 6 Status: Report the actual value of Joystick 2 Lamp 600b = Off01b = On10b = Flashing11b = Not available";
CM_ SG_ 2566691838 Joystick2Lamp7Status "Joystick 2 Lamp 7 Status: Report the actual value of Joystick 2 Lamp 700b = Off01b = On10b = Flashing11b = Not available";
CM_ SG_ 2566691838 Joystick2Lamp8Status "Joystick 2 Lamp 8 Status: Report the actual value of Joystick 2 Lamp 800b = Off01b = On10b = Flashing11b = Not available";
CM_ SG_ 2566691838 Joystick2Lamp9Status "Joystick 2 Lamp 9 Status: Report the actual value of Joystick 2 Lamp 900b = Off01b = On10b = Flashing11b = Not available";
CM_ BO_ 2566692094 "Joystick 1 Lamp Status";
CM_ SG_ 2566692094 Joystick1Lamp10Status "Joystick 1 Lamp 10 Status: Report the actual value of Joystick 1 Lamp 1000b = Off01b = On10b = Flashing11b = Not available";
CM_ SG_ 2566692094 Joystick1Lamp1Status "Joystick 1 Lamp 1 Status: Report the actual value of Joystick 1 Lamp 100b = Off01b = On10b = Flashing11b = Not available";
CM_ SG_ 2566692094 Joystick1Lamp2Status "Joystick 1 Lamp 2 Status: Report the actual value of Joystick 1 Lamp 200b = Off01b = On10b = Flashing11b = Not available";
CM_ SG_ 2566692094 Joystick1Lamp3Status "Joystick 1 Lamp 3 Status: Report the actual value of Joystick 1 Lamp 300b = Off01b = On10b = Flashing11b = Not available";
CM_ SG_ 2566692094 Joystick1Lamp4Status "Joystick 1 Lamp 4 Status: Report the actual value of Joystick 1 Lamp 400b = Off01b = On10b = Flashing11b = Not available";
CM_ SG_ 2566692094 Joystick1Lamp5Status "Joystick 1 Lamp 5 Status: Report the actual value of Joystick 1 Lamp 500b = Off01b = On10b = Flashing11b = Not available";
CM_ SG_ 2566692094 Joystick1Lamp6Status "Joystick 1 Lamp 6 Status: Report the actual value of Joystick 1 Lamp 600b = Off01b = On10b = Flashing11b = Not available";
CM_ SG_ 2566692094 Joystick1Lamp7Status "Joystick 1 Lamp 7 Status: Report the actual value of Joystick 1 Lamp 700b = Off01b = On10b = Flashing11b = Not available";
CM_ SG_ 2566692094 Joystick1Lamp8Status "Joystick 1 Lamp 8 Status: Report the actual value of Joystick 1 Lamp 800b = Off01b = On10b = Flashing11b = Not available";
CM_ SG_ 2566692094 Joystick1Lamp9Status "Joystick 1 Lamp 9 Status: Report the actual value of Joystick 1 Lamp 900b = Off01b = On10b = Flashing11b = Not available";
CM_ BO_ 2566692862 "Dash Display 2";
CM_ SG_ 2566692862 DisplayRemainPowered "Display Remain Powered: Indicates the ECU needs the display (i.e. monitor device) to continue to remain powered after ignition key off. An ECU would use this when the ECU needs the display to remain powered after key off so the ECU can communicate to...";
CM_ SG_ 2566692862 EngineFuel2Tank1Level "Engine Fuel 2 Tank 1 Level: Fuel level in tank 1 containing the second fuel type..";
CM_ SG_ 2566692862 EngineFuel2Tank2Level "Engine Fuel 2 Tank 2 Level: Fuel level in tank 2 containing the second fuel type.";
CM_ SG_ 2566692862 EngineFuel2Tank3Level "Engine Fuel 2 Tank 3 Level: Fuel level in tank 3 containing the second fuel type.";
CM_ SG_ 2566692862 EngineFuel2Tank4Level "Engine Fuel 2 Tank 4 Level: Fuel level in tank 4 containing the second fuel type.";
CM_ SG_ 2566692862 EngineOilLevelHighLow "Engine Oil Level High / Low: Conveys the amount of current volume of engine oil compared to recommended volume. Positive values indicate overfill.  Zero means the engine oil is filled to the recommended level. Negative values indicate the amount in w...";
CM_ SG_ 2566692862 EngnOlFltrDffrntlPrssrExtnddRng "Engine Oil Filter Differential Pressure (Extended Range): Change in engine oil differential pressure measured across the oil filter element. The differential pressure is the measured as the pressure at the filter intake with respect to the pressure a...";
CM_ BO_ 2566697470 "Engine Ignition Control Module Status";
CM_ SG_ 2566697470 EngnIgntnCntrlMdl1Stt "Engine Ignition Control Module 1 State: This parameter is used to indicate the current state of Engine Ignition Control Module 1.000b = Disabled (by user)001b = Shutdown (due to alarm)010b = Stalled (waiting for timing signals)011b = Firing Ignition ...";
CM_ SG_ 2566697470 EngnIgntnCntrlMdl1Tmprtr "Engine Ignition Control Module 1 Temperature: Measured internal temperature of the Engine Ignition Control Module 1 circuitry.";
CM_ SG_ 2566697470 EngnIgntnCntrlMdl2Stt "Engine Ignition Control Module 2 State: This parameter is used to indicate the current state of Engine Ignition Control Module 2.000b = Disabled (by user)001b = Shutdown (due to alarm)010b = Stalled (waiting for timing signals)011b = Firing Ignition ...";
CM_ SG_ 2566697470 EngnIgntnCntrlMdl2Tmprtr "Engine Ignition Control Module 2 Temperature: Measured internal temperature of the Engine Ignition Control Module 2 circuitry.";
CM_ BO_ 2566697726 "Switched Power Output Current";
CM_ SG_ 2566697726 SwitchedOutput10Current "Switched Output #10 Current: Measured electrical current flowing out of Power Distribution Module (PDM) Switched Output #10.";
CM_ SG_ 2566697726 SwitchedOutput11Current "Switched Output #11 Current: Measured electrical current flowing out of Power Distribution Module (PDM) Switched Output #11.";
CM_ SG_ 2566697726 SwitchedOutput12Current "Switched Output #12 Current: Measured electrical current flowing out of Power Distribution Module (PDM) Switched Output #12.";
CM_ SG_ 2566697726 SwitchedOutput13Current "Switched Output #13 Current: Measured electrical current flowing out of Power Distribution Module (PDM) Switched Output #13.";
CM_ SG_ 2566697726 SwitchedOutput14Current "Switched Output #14 Current: Measured electrical current flowing out of Power Distribution Module (PDM) Switched Output #14.";
CM_ SG_ 2566697726 SwitchedOutput15Current "Switched Output #15 Current: Measured electrical current flowing out of Power Distribution Module (PDM) Switched Output #15.";
CM_ SG_ 2566697726 SwitchedOutput16Current "Switched Output #16 Current: Measured electrical current flowing out of Power Distribution Module (PDM) Switched Output #16.";
CM_ SG_ 2566697726 SwitchedOutput17Current "Switched Output #17 Current: Measured electrical current flowing out of Power Distribution Module (PDM) Switched Output #17.";
CM_ SG_ 2566697726 SwitchedOutput18Current "Switched Output #18 Current: Measured electrical current flowing out of Power Distribution Module (PDM) Switched Output #18.";
CM_ SG_ 2566697726 SwitchedOutput19Current "Switched Output #19 Current: Measured electrical current flowing out of Power Distribution Module (PDM) Switched Output #19.";
CM_ SG_ 2566697726 SwitchedOutput1Current "Switched Output #1 Current: Measured electrical current flowing out of Power Distribution Module (PDM) Switched Output #1.";
CM_ SG_ 2566697726 SwitchedOutput20Current "Switched Output #20 Current: Measured electrical current flowing out of Power Distribution Module (PDM) Switched Output #20.";
CM_ SG_ 2566697726 SwitchedOutput21Current "Switched Output #21 Current: Measured electrical current flowing out of Power Distribution Module (PDM) Switched Output #21.";
CM_ SG_ 2566697726 SwitchedOutput22Current "Switched Output #22 Current: Measured electrical current flowing out of Power Distribution Module (PDM) Switched Output #22.";
CM_ SG_ 2566697726 SwitchedOutput23Current "Switched Output #23 Current: Measured electrical current flowing out of Power Distribution Module (PDM) Switched Output #23.";
CM_ SG_ 2566697726 SwitchedOutput24Current "Switched Output #24 Current: Measured electrical current flowing out of Power Distribution Module (PDM) Switched Output #24.";
CM_ SG_ 2566697726 SwitchedOutput25Current "Switched Output #25 Current: Measured electrical current flowing out of Power Distribution Module (PDM) Switched Output #25.";
CM_ SG_ 2566697726 SwitchedOutput26Current "Switched Output #26 Current: Measured electrical current flowing out of Power Distribution Module (PDM) Switched Output #26.";
CM_ SG_ 2566697726 SwitchedOutput27Current "Switched Output #27 Current: Measured electrical current flowing out of Power Distribution Module (PDM) Switched Output #27.";
CM_ SG_ 2566697726 SwitchedOutput28Current "Switched Output #28 Current: Measured electrical current flowing out of Power Distribution Module (PDM) Switched Output #28.";
CM_ SG_ 2566697726 SwitchedOutput29Current "Switched Output #29 Current: Measured electrical current flowing out of Power Distribution Module (PDM) Switched Output #29.";
CM_ SG_ 2566697726 SwitchedOutput2Current "Switched Output #2 Current: Measured electrical current flowing out of Power Distribution Module (PDM) Switched Output #2.";
CM_ SG_ 2566697726 SwitchedOutput30Current "Switched Output #30 Current: Measured electrical current flowing out of Power Distribution Module (PDM) Switched Output #30.";
CM_ SG_ 2566697726 SwitchedOutput31Current "Switched Output #31 Current: Measured electrical current flowing out of Power Distribution Module (PDM) Switched Output #31.";
CM_ SG_ 2566697726 SwitchedOutput32Current "Switched Output #32 Current: Measured electrical current flowing out of Power Distribution Module (PDM) Switched Output #32.";
CM_ SG_ 2566697726 SwitchedOutput3Current "Switched Output #3 Current: Measured electrical current flowing out of Power Distribution Module (PDM) Switched Output #3.";
CM_ SG_ 2566697726 SwitchedOutput4Current "Switched Output #4 Current: Measured electrical current flowing out of Power Distribution Module (PDM) Switched Output #4.";
CM_ SG_ 2566697726 SwitchedOutput5Current "Switched Output #5 Current: Measured electrical current flowing out of Power Distribution Module (PDM) Switched Output #5.";
CM_ SG_ 2566697726 SwitchedOutput6Current "Switched Output #6 Current: Measured electrical current flowing out of Power Distribution Module (PDM) Switched Output #6.";
CM_ SG_ 2566697726 SwitchedOutput7Current "Switched Output #7 Current: Measured electrical current flowing out of Power Distribution Module (PDM) Switched Output #7.";
CM_ SG_ 2566697726 SwitchedOutput8Current "Switched Output #8 Current: Measured electrical current flowing out of Power Distribution Module (PDM) Switched Output #8.";
CM_ SG_ 2566697726 SwitchedOutput9Current "Switched Output #9 Current: Measured electrical current flowing out of Power Distribution Module (PDM) Switched Output #9.";
CM_ BO_ 2566697982 "Fused Power Output Current";
CM_ SG_ 2566697982 FusedOutput10Current "Fused Output #10 Current: Measured electrical current flowing out of Power Distribution Module (PDM) Fused Output #10.";
CM_ SG_ 2566697982 FusedOutput11Current "Fused Output #11 Current: Measured electrical current flowing out of Power Distribution Module (PDM) Fused Output #11.";
CM_ SG_ 2566697982 FusedOutput12Current "Fused Output #12 Current: Measured electrical current flowing out of Power Distribution Module (PDM) Fused Output #12.";
CM_ SG_ 2566697982 FusedOutput13Current "Fused Output #13 Current: Measured electrical current flowing out of Power Distribution Module (PDM) Fused Output #13.";
CM_ SG_ 2566697982 FusedOutput14Current "Fused Output #14 Current: Measured electrical current flowing out of Power Distribution Module (PDM) Fused Output #14.";
CM_ SG_ 2566697982 FusedOutput15Current "Fused Output #15 Current: Measured electrical current flowing out of Power Distribution Module (PDM) Fused Output #15.";
CM_ SG_ 2566697982 FusedOutput16Current "Fused Output #16 Current: Measured electrical current flowing out of Power Distribution Module (PDM) Fused Output #16.";
CM_ SG_ 2566697982 FusedOutput17Current "Fused Output #17 Current: Measured electrical current flowing out of Power Distribution Module (PDM) Fused Output #17.";
CM_ SG_ 2566697982 FusedOutput18Current "Fused Output #18 Current: Measured electrical current flowing out of Power Distribution Module (PDM) Fused Output #18.";
CM_ SG_ 2566697982 FusedOutput19Current "Fused Output #19 Current: Measured electrical current flowing out of Power Distribution Module (PDM) Fused Output #19.";
CM_ SG_ 2566697982 FusedOutput1Current "Fused Output #1 Current: Measured electrical current flowing out of Power Distribution Module (PDM) Fused Output #1.";
CM_ SG_ 2566697982 FusedOutput20Current "Fused Output #20 Current: Measured electrical current flowing out of Power Distribution Module (PDM) Fused Output #20.";
CM_ SG_ 2566697982 FusedOutput21Current "Fused Output #21 Current: Measured electrical current flowing out of Power Distribution Module (PDM) Fused Output #21.";
CM_ SG_ 2566697982 FusedOutput22Current "Fused Output #22 Current: Measured electrical current flowing out of Power Distribution Module (PDM) Fused Output #22.";
CM_ SG_ 2566697982 FusedOutput23Current "Fused Output #23 Current: Measured electrical current flowing out of Power Distribution Module (PDM) Fused Output #23.";
CM_ SG_ 2566697982 FusedOutput24Current "Fused Output #24 Current: Measured electrical current flowing out of Power Distribution Module (PDM) Fused Output #24.";
CM_ SG_ 2566697982 FusedOutput25Current "Fused Output #25 Current: Measured electrical current flowing out of Power Distribution Module (PDM) Fused Output #25.";
CM_ SG_ 2566697982 FusedOutput26Current "Fused Output #26 Current: Measured electrical current flowing out of Power Distribution Module (PDM) Fused Output #26.";
CM_ SG_ 2566697982 FusedOutput27Current "Fused Output #27 Current: Measured electrical current flowing out of Power Distribution Module (PDM) Fused Output #27.";
CM_ SG_ 2566697982 FusedOutput28Current "Fused Output #28 Current: Measured electrical current flowing out of Power Distribution Module (PDM) Fused Output #28.";
CM_ SG_ 2566697982 FusedOutput29Current "Fused Output #29 Current: Measured electrical current flowing out of Power Distribution Module (PDM) Fused Output #29.";
CM_ SG_ 2566697982 FusedOutput2Current "Fused Output #2 Current: Measured electrical current flowing out of Power Distribution Module (PDM) Fused Output #2.";
CM_ SG_ 2566697982 FusedOutput30Current "Fused Output #30 Current: Measured electrical current flowing out of Power Distribution Module (PDM) Fused Output #30.";
CM_ SG_ 2566697982 FusedOutput31Current "Fused Output #31 Current: Measured electrical current flowing out of Power Distribution Module (PDM) Fused Output #31.";
CM_ SG_ 2566697982 FusedOutput32Current "Fused Output #32 Current: Measured electrical current flowing out of Power Distribution Module (PDM) Fused Output #32.";
CM_ SG_ 2566697982 FusedOutput3Current "Fused Output #3 Current: Measured electrical current flowing out of Power Distribution Module (PDM) Fused Output #3.";
CM_ SG_ 2566697982 FusedOutput4Current "Fused Output #4 Current: Measured electrical current flowing out of Power Distribution Module (PDM) Fused Output #4.";
CM_ SG_ 2566697982 FusedOutput5Current "Fused Output #5 Current: Measured electrical current flowing out of Power Distribution Module (PDM) Fused Output #5.";
CM_ SG_ 2566697982 FusedOutput6Current "Fused Output #6 Current: Measured electrical current flowing out of Power Distribution Module (PDM) Fused Output #6.";
CM_ SG_ 2566697982 FusedOutput7Current "Fused Output #7 Current: Measured electrical current flowing out of Power Distribution Module (PDM) Fused Output #7.";
CM_ SG_ 2566697982 FusedOutput8Current "Fused Output #8 Current: Measured electrical current flowing out of Power Distribution Module (PDM) Fused Output #8.";
CM_ SG_ 2566697982 FusedOutput9Current "Fused Output #9 Current: Measured electrical current flowing out of Power Distribution Module (PDM) Fused Output #9.";
CM_ BO_ 2566698238 "Switched Power Output Status";
CM_ SG_ 2566698238 SwitchedOutput1 "Switched Output #1: State of Switched Output #1. Used to indicate the output state.00b = Output off01b = Output on10b = Reserved11b = Take no action";
CM_ SG_ 2566698238 SwitchedOutput10 "Switched Output #10: State of Switched Output #10. Used to indicate the output state.00b = Output off01b = Output on10b = Reserved11b = Take no action";
CM_ SG_ 2566698238 SwitchedOutput11 "Switched Output #11: State of Switched Output #11. Used to indicate the output state.00b = Output off01b = Output on10b = Reserved11b = Take no action";
CM_ SG_ 2566698238 SwitchedOutput12 "Switched Output #12: State of Switched Output #12. Used to indicate the output state.00b = Output off01b = Output on10b = Reserved11b = Take no action";
CM_ SG_ 2566698238 SwitchedOutput13 "Switched Output #13: State of Switched Output #13. Used to indicate the output state.00b = Output off01b = Output on10b = Reserved11b = Take no action";
CM_ SG_ 2566698238 SwitchedOutput14 "Switched Output #14: State of Switched Output #14. Used to indicate the output state.00b = Output off01b = Output on10b = Reserved11b = Take no action";
CM_ SG_ 2566698238 SwitchedOutput15 "Switched Output #15: State of Switched Output #15. Used to indicate the output state.00b = Output off01b = Output on10b = Reserved11b = Take no action";
CM_ SG_ 2566698238 SwitchedOutput16 "Switched Output #16: State of Switched Output #16. Used to indicate the output state.00b = Output off01b = Output on10b = Reserved11b = Take no action";
CM_ SG_ 2566698238 SwitchedOutput17 "Switched Output #17: State of Switched Output #17. Used to indicate the output state.00b = Output off01b = Output on10b = Reserved11b = Take no action";
CM_ SG_ 2566698238 SwitchedOutput18 "Switched Output #18: State of Switched Output #18. Used to indicate the output state.00b = Output off01b = Output on10b = Reserved11b = Take no action";
CM_ SG_ 2566698238 SwitchedOutput19 "Switched Output #19: State of Switched Output #19. Used to indicate the output state.00b = Output off01b = Output on10b = Reserved11b = Take no action";
CM_ SG_ 2566698238 SwitchedOutput2 "Switched Output #2: State of Switched Output #2. Used to indicate the output state.00b = Output off01b = Output on10b = Reserved11b = Take no action";
CM_ SG_ 2566698238 SwitchedOutput20 "Switched Output #20: State of Switched Output #20. Used to indicate the output state.00b = Output off01b = Output on10b = Reserved11b = Take no action";
CM_ SG_ 2566698238 SwitchedOutput21 "Switched Output #21: State of Switched Output #21. Used to indicate the output state.00b = Output off01b = Output on10b = Reserved11b = Take no action";
CM_ SG_ 2566698238 SwitchedOutput22 "Switched Output #22: State of Switched Output #22. Used to indicate the output state.00b = Output off01b = Output on10b = Reserved11b = Take no action";
CM_ SG_ 2566698238 SwitchedOutput23 "Switched Output #23: State of Switched Output #23. Used to indicate the output state.00b = Output off01b = Output on10b = Reserved11b = Take no action";
CM_ SG_ 2566698238 SwitchedOutput24 "Switched Output #24: State of Switched Output #24. Used to indicate the output state.00b = Output off01b = Output on10b = Reserved11b = Take no action";
CM_ SG_ 2566698238 SwitchedOutput25 "Switched Output #25: State of Switched Output #25. Used to indicate the output state.00b = Output off01b = Output on10b = Reserved11b = Take no action";
CM_ SG_ 2566698238 SwitchedOutput26 "Switched Output #26: State of Switched Output #26. Used to indicate the output state.00b = Output off01b = Output on10b = Reserved11b = Take no action";
CM_ SG_ 2566698238 SwitchedOutput27 "Switched Output #27: State of Switched Output #27. Used to indicate the output state.00b = Output off01b = Output on10b = Reserved11b = Take no action";
CM_ SG_ 2566698238 SwitchedOutput28 "Switched Output #28: State of Switched Output #28. Used to indicate the output state.00b = Output off01b = Output on10b = Reserved11b = Take no action";
CM_ SG_ 2566698238 SwitchedOutput29 "Switched Output #29: State of Switched Output #29. Used to indicate the output state.00b = Output off01b = Output on10b = Reserved11b = Take no action";
CM_ SG_ 2566698238 SwitchedOutput3 "Switched Output #3: State of Switched Output #3. Used to indicate the output state.00b = Output off01b = Output on10b = Reserved11b = Take no action";
CM_ SG_ 2566698238 SwitchedOutput30 "Switched Output #30: State of Switched Output #30. Used to indicate the output state.00b = Output off01b = Output on10b = Reserved11b = Take no action";
CM_ SG_ 2566698238 SwitchedOutput31 "Switched Output #31: State of Switched Output #31. Used to indicate the output state.00b = Output off01b = Output on10b = Reserved11b = Take no action";
CM_ SG_ 2566698238 SwitchedOutput32 "Switched Output #32: State of Switched Output #32. Used to indicate the output state.00b = Output off01b = Output on10b = Reserved11b = Take no action";
CM_ SG_ 2566698238 SwitchedOutput4 "Switched Output #4: State of Switched Output #4. Used to indicate the output state.00b = Output off01b = Output on10b = Reserved11b = Take no action";
CM_ SG_ 2566698238 SwitchedOutput5 "Switched Output #5: State of Switched Output #5. Used to indicate the output state.00b = Output off01b = Output on10b = Reserved11b = Take no action";
CM_ SG_ 2566698238 SwitchedOutput6 "Switched Output #6: State of Switched Output #6. Used to indicate the output state.00b = Output off01b = Output on10b = Reserved11b = Take no action";
CM_ SG_ 2566698238 SwitchedOutput7 "Switched Output #7: State of Switched Output #7. Used to indicate the output state.00b = Output off01b = Output on10b = Reserved11b = Take no action";
CM_ SG_ 2566698238 SwitchedOutput8 "Switched Output #8: State of Switched Output #8. Used to indicate the output state.00b = Output off01b = Output on10b = Reserved11b = Take no action";
CM_ SG_ 2566698238 SwitchedOutput9 "Switched Output #9: State of Switched Output #9. Used to indicate the output state.00b = Output off01b = Output on10b = Reserved11b = Take no action";
CM_ BO_ 2566698494 "Fused Power Output Status";
CM_ SG_ 2566698494 FusedOutput1 "Fused Output #1: State of Fused Output #1. Used to indicate the output state.00b = Output not powered01b = Output powered10b = Reserved11b = Take no action";
CM_ SG_ 2566698494 FusedOutput10 "Fused Output #10: State of Fused Output #10. Used to indicate the output state.00b = Output not powered01b = Output powered10b = Reserved11b = Take no action";
CM_ SG_ 2566698494 FusedOutput11 "Fused Output #11: State of Fused Output #11. Used to indicate the output state.00b = Output not powered01b = Output powered10b = Reserved11b = Take no action";
CM_ SG_ 2566698494 FusedOutput12 "Fused Output #12: State of Fused Output #12. Used to indicate the output state.00b = Output not powered01b = Output powered10b = Reserved11b = Take no action";
CM_ SG_ 2566698494 FusedOutput13 "Fused Output #13: State of Fused Output #13. Used to indicate the output state.00b = Output not powered01b = Output powered10b = Reserved11b = Take no action";
CM_ SG_ 2566698494 FusedOutput14 "Fused Output #14: State of Fused Output #14. Used to indicate the output state.00b = Output not powered01b = Output powered10b = Reserved11b = Take no action";
CM_ SG_ 2566698494 FusedOutput15 "Fused Output #15: State of Fused Output #15. Used to indicate the output state.00b = Output not powered01b = Output powered10b = Reserved11b = Take no action";
CM_ SG_ 2566698494 FusedOutput16 "Fused Output #16: State of Fused Output #16. Used to indicate the output state.00b = Output not powered01b = Output powered10b = Reserved11b = Take no action";
CM_ SG_ 2566698494 FusedOutput17 "Fused Output #17: State of Fused Output #17. Used to indicate the output state.00b = Output not powered01b = Output powered10b = Reserved11b = Take no action";
CM_ SG_ 2566698494 FusedOutput18 "Fused Output #18: State of Fused Output #18. Used to indicate the output state.00b = Output not powered01b = Output powered10b = Reserved11b = Take no action";
CM_ SG_ 2566698494 FusedOutput19 "Fused Output #19: State of Fused Output #19. Used to indicate the output state.00b = Output not powered01b = Output powered10b = Reserved11b = Take no action";
CM_ SG_ 2566698494 FusedOutput2 "Fused Output #2: State of Fused Output #2. Used to indicate the output state.00b = Output not powered01b = Output powered10b = Reserved11b = Take no action";
CM_ SG_ 2566698494 FusedOutput20 "Fused Output #20: State of Fused Output #20. Used to indicate the output state.00b = Output not powered01b = Output powered10b = Reserved11b = Take no action";
CM_ SG_ 2566698494 FusedOutput21 "Fused Output #21: State of Fused Output #21. Used to indicate the output state.00b = Output not powered01b = Output powered10b = Reserved11b = Take no action";
CM_ SG_ 2566698494 FusedOutput22 "Fused Output #22: State of Fused Output #22. Used to indicate the output state.00b = Output not powered01b = Output powered10b = Reserved11b = Take no action";
CM_ SG_ 2566698494 FusedOutput23 "Fused Output #23: State of Fused Output #23. Used to indicate the output state.00b = Output not powered01b = Output powered10b = Reserved11b = Take no action";
CM_ SG_ 2566698494 FusedOutput24 "Fused Output #24: State of Fused Output #24. Used to indicate the output state.00b = Output not powered01b = Output powered10b = Reserved11b = Take no action";
CM_ SG_ 2566698494 FusedOutput25 "Fused Output #25: State of Fused Output #25. Used to indicate the output state.00b = Output not powered01b = Output powered10b = Reserved11b = Take no action";
CM_ SG_ 2566698494 FusedOutput26 "Fused Output #26: State of Fused Output #26. Used to indicate the output state.00b = Output not powered01b = Output powered10b = Reserved11b = Take no action";
CM_ SG_ 2566698494 FusedOutput27 "Fused Output #27: State of Fused Output #27. Used to indicate the output state.00b = Output not powered01b = Output powered10b = Reserved11b = Take no action";
CM_ SG_ 2566698494 FusedOutput28 "Fused Output #28: State of Fused Output #28. Used to indicate the output state.00b = Output not powered01b = Output powered10b = Reserved11b = Take no action";
CM_ SG_ 2566698494 FusedOutput29 "Fused Output #29: State of Fused Output #29. Used to indicate the output state.00b = Output not powered01b = Output powered10b = Reserved11b = Take no action";
CM_ SG_ 2566698494 FusedOutput3 "Fused Output #3: State of Fused Output #3. Used to indicate the output state.00b = Output not powered01b = Output powered10b = Reserved11b = Take no action";
CM_ SG_ 2566698494 FusedOutput30 "Fused Output #30: State of Fused Output #30. Used to indicate the output state.00b = Output not powered01b = Output powered10b = Reserved11b = Take no action";
CM_ SG_ 2566698494 FusedOutput31 "Fused Output #31: State of Fused Output #31. Used to indicate the output state.00b = Output not powered01b = Output powered10b = Reserved11b = Take no action";
CM_ SG_ 2566698494 FusedOutput32 "Fused Output #32: State of Fused Output #32. Used to indicate the output state.00b = Output not powered01b = Output powered10b = Reserved11b = Take no action";
CM_ SG_ 2566698494 FusedOutput4 "Fused Output #4: State of Fused Output #4. Used to indicate the output state.00b = Output not powered01b = Output powered10b = Reserved11b = Take no action";
CM_ SG_ 2566698494 FusedOutput5 "Fused Output #5: State of Fused Output #5. Used to indicate the output state.00b = Output not powered01b = Output powered10b = Reserved11b = Take no action";
CM_ SG_ 2566698494 FusedOutput6 "Fused Output #6: State of Fused Output #6. Used to indicate the output state.00b = Output not powered01b = Output powered10b = Reserved11b = Take no action";
CM_ SG_ 2566698494 FusedOutput7 "Fused Output #7: State of Fused Output #7. Used to indicate the output state.00b = Output not powered01b = Output powered10b = Reserved11b = Take no action";
CM_ SG_ 2566698494 FusedOutput8 "Fused Output #8: State of Fused Output #8. Used to indicate the output state.00b = Output not powered01b = Output powered10b = Reserved11b = Take no action";
CM_ SG_ 2566698494 FusedOutput9 "Fused Output #9: State of Fused Output #9. Used to indicate the output state.00b = Output not powered01b = Output powered10b = Reserved11b = Take no action";
CM_ BO_ 2566698750 "Vehicle Electrical Power 5";
CM_ SG_ 2566698750 SLIBatteryPackCapacity "SLI Battery Pack Capacity: Original or rated total reserve capacity of the battery pack used for starting the engine, for lighting, and for ignition (SLI).This parameter shall be used to report the capacity of the battery pack.  If the capacity of in...";
CM_ SG_ 2566698750 SLIBatteryPackHealth "SLI Battery Pack Health: Capacity of the battery pack relative to its original specification for the battery pack used for starting the engine, for lighting, and for ignition (SLI). 0% means battery pack is not capable of holding any charge, 100% mea...";
CM_ SG_ 2566698750 SLIBatteryPackStateofCharge "SLI Battery Pack State of Charge: Indicates the remaining charge of the battery pack used for starting the engine, for lighting, and for ignition (SLI). 0% means no charge remaining, 100% means full capacity at the battery pack's current state of hea...";
CM_ SG_ 2566698750 SLICrnkngPrdtdMnmmBttrVltg "SLI Cranking Predicted Minimum Battery Voltage: Prediction of the minimum battery voltage used for starting the engine, for lighting, and for ignition (SLI) during a crank event, under present battery conditions.This parameter shall be used to report...";
CM_ BO_ 2566699006 "Hybrid System Status 2";
CM_ SG_ 2566699006 HrdBttrPkRmnngChrg "Hybrid Battery Pack Remaining Charge: Indicates the hybrid battery pack remaining charge. 0% means no charge remaining, 100% means full charge remaining.";
CM_ SG_ 2566699006 HrdSstmEngnStpStrtRmnngPrntg "Hybrid System Engine Stop-Start Remaining Percentage: Indicates the remaining percentage of engine stop-start operation allowed by the hybrid system.The calculation of the percentage is manufacturer specific.  It is an operational limitation, not a f...";
CM_ SG_ 2566699006 HrdPrplsnMdMxmmSpdSttng "Hybrid Propulsion Mode Maximum Speed Setting: The maximum speed setting as requested using Hybrid Propulsion Mode Requested Maximum Speed (SPN 9706).A value of FBh indicates that the sender supports this parameter, but there is currently no requested...";
CM_ SG_ 2566699006 HrdPrplsnMdRmnngDstn "Hybrid Propulsion Mode Remaining Distance: While in a Hybrid Propulsion Mode (see SPN 7889) other than Mode 1 - Stored Energy Source Sustaining, this reports a count down of the remaining distance until the mode is exited.  When the requested Hybrid ...";
CM_ BO_ 2566699262 "Aftertreatment 2 Service 2";
CM_ SG_ 2566699262 Atttt2DsPttFtTtNxtAtvRt "Aftertreatment 2 Diesel Particulate Filter Time to Next Active Regeneration: Indicates the time to the next active regeneration event of diesel particulate filter 2.";
CM_ SG_ 2566699262 Atttt2SCRSstTSLstSstCEvt "Aftertreatment 2 SCR System Time Since Last System Cleaning Event: Indicates the time since the last cleaning event of the SCR system in bank 2.";
CM_ BO_ 2566699518 "Aftertreatment 1 Service 2";
CM_ SG_ 2566699518 Atttt1DsPttFtTtNxtAtvRt "Aftertreatment 1 Diesel Particulate Filter Time to Next Active Regeneration: Indicates the time to the next active regeneration event of diesel particulate filter 1.";
CM_ SG_ 2566699518 Atttt1SCRSstTSLstSstCEvt "Aftertreatment 1 SCR System Time Since Last System Cleaning Event: Indicates the time since the last cleaning event of the SCR system in bank 1.";
CM_ BO_ 2566699774 "Aftertreatment 2 SCR Electronic Control Module Information";
CM_ SG_ 2566699774 Atttt2DsExstFdCtMd1PwSpp1 "Aftertreatment 2 Diesel Exhaust Fluid Control Module 1 Power Supply 1: State signal which indicates when the DEF control module 1 power supply of aftertreatment 2 is being driven. On means the ECU is powering the aftertreatment 2 DEF control module 1...";
CM_ SG_ 2566699774 Atttt2DsExstFdCtMd1PwSpp2 "Aftertreatment 2 Diesel Exhaust Fluid Control Module 1 Power Supply 2: State signal which indicates when the DEF control module 1 power supply 2 of aftertreatment 2 is being driven. On means the ECU is powering the aftertreatment 2 DEF control module...";
CM_ SG_ 2566699774 Atttt2DsExstFdCtMd1RCt "Aftertreatment 2 Diesel Exhaust Fluid Control Module 1 Relay Control: State signal which indicates when the DEF control module 1 relay of aftertreatment 2 is being energized. On means the ECU is powering the Aftertreatment 2 DEF dosing unit relay. No...";
CM_ SG_ 2566699774 Atttt2DsExstFdCtMd2PwSpp1 "Aftertreatment 2 Diesel Exhaust Fluid Control Module 2 Power Supply 1: State signal which indicates when the DEF control module 2 power supply of aftertreatment 2 is being driven. On means the ECU is powering the aftertreatment 2 DEF control module p...";
CM_ SG_ 2566699774 Atttt2DsExstFdCtMd2PwSpp2 "Aftertreatment 2 Diesel Exhaust Fluid Control Module 2 Power Supply 2: State signal which indicates when the DEF control module 2 power supply 2 of aftertreatment 2 is being driven. On means the ECU is powering the aftertreatment 2 DEF control module...";
CM_ SG_ 2566699774 Atttt2DsExstFdCtMd2RCt "Aftertreatment 2 Diesel Exhaust Fluid Control Module 2 Relay Control: State signal which indicates when the DEF control module 2 relay of aftertreatment 2 is being energized. On means the ECU is powering the Aftertreatment 2 DEF dosing unit relay. No...";
CM_ SG_ 2566699774 Atttt2DsExstFdCtMdCtB "Aftertreatment 2 Diesel Exhaust Fluid Control Module Circuit Breaker: The status of the circuit breaker that is used to power the Diesel Exhaust Fluid control module.00b = Off01b = On10b = Error11b = Not available";
CM_ BO_ 2566700030 "Aftertreatment 1 SCR Electronic Control Module Information";
CM_ SG_ 2566700030 Atttt1DsExstFdCtMd1PwSpp1 "Aftertreatment 1 Diesel Exhaust Fluid Control Module 1 Power Supply 1: State signal which indicates when the DEF control module power supply of aftertreatment 1 is being driven. On means the ECU is powering the aftertreatment 1 DEF control module pow...";
CM_ SG_ 2566700030 Atttt1DsExstFdCtMd1PwSpp2 "Aftertreatment 1 Diesel Exhaust Fluid Control Module 1 Power Supply 2: State signal which indicates when the DEF control module 1 power supply 2 of aftertreatment 1 is being driven. On means the ECU is powering the aftertreatment 1 DEF control module...";
CM_ SG_ 2566700030 Atttt1DsExstFdCtMd1RCt "Aftertreatment 1 Diesel Exhaust Fluid Control Module 1 Relay Control: State signal which indicates when the DEF control module relay of aftertreatment 1 is being energized. On means the ECU is powering the Aftertreatment 1 DEF dosing unit relay. Note...";
CM_ SG_ 2566700030 Atttt1DsExstFdCtMd2PwSpp1 "Aftertreatment 1 Diesel Exhaust Fluid Control Module 2 Power Supply 1: State signal which indicates when the DEF control module 2 power supply of aftertreatment 1 is being driven. On means the ECU is powering the aftertreatment 1 DEF control module p...";
CM_ SG_ 2566700030 Atttt1DsExstFdCtMd2PwSpp2 "Aftertreatment 1 Diesel Exhaust Fluid Control Module 2 Power Supply 2: State signal which indicates when the DEF control module 2 power supply 2 of aftertreatment 1 is being driven. On means the ECU is powering the aftertreatment 1 DEF control module...";
CM_ SG_ 2566700030 Atttt1DsExstFdCtMd2RCt "Aftertreatment 1 Diesel Exhaust Fluid Control Module 2 Relay Control: State signal which indicates when the DEF control module 2 relay of aftertreatment 1 is being energized. On means the ECU is powering the Aftertreatment 1 DEF dosing unit relay. No...";
CM_ SG_ 2566700030 Atttt1DsExstFdCtMdCtB "Aftertreatment 1 Diesel Exhaust Fluid Control Module Circuit Breaker: The status of the circuit breaker that is used to power the diesel exhaust control module.00b = off01b = on10b = error11b = not available";
CM_ BO_ 2566700286 "Aftertreatment 2 SCR Service Information 2";
CM_ SG_ 2566700286 Aftrtrtmnt2TtlDslExhstFldUsd "Aftertreatment 2 Total Diesel Exhaust Fluid Used: Total amount of DEF used by aftertreatment device 2 over the lifetime of the device.";
CM_ BO_ 2566700542 "Aftertreatment 1 SCR Service Information 2";
CM_ SG_ 2566700542 Aftrtrtmnt1TtlDslExhstFldUsd "Aftertreatment 1 Total Diesel Exhaust Fluid Used: Total amount of DEF used by aftertreatment device 1 over the lifetime of the device.";
CM_ SG_ 2566700542 AftrtrtmntTrpDslExhstFld "Aftertreatment Trip Diesel Exhaust Fluid: DEF consumed during all or part of a journey.";
CM_ BO_ 2566701566 "Transmission Fluids 3";
CM_ SG_ 2566701566 TransmissionClutch2Pressure "Transmission Clutch 2 Pressure: Gage pressure of hydraulic actuation fluid for a second transmission clutch. In dual input clutch applications, this refers to the second input clutch.";
CM_ SG_ 2566701566 TrnsmssnOlTrnsmssnClrOtltTmprtr "Transmission Oil Transmission Cooler Outlet Temperature: Temperature of transmission lubricant after it exits from the transmission cooler.";
CM_ BO_ 2566701822 "Hybrid System Status 1";
CM_ SG_ 2566701822 ExtrnlEnrgSrCnntnStts "External Energy Source Connection Status : External Energy Source Connection Status provides feedback to the External Energy Source Connection Demand (SPN 7890) if this SP is used to control the external energy source(s).  If SPN 7890 is not availabl...";
CM_ SG_ 2566701822 HrdPrplsnMdTrnstnStts "Hybrid Propulsion Mode Transition Status : Hybrid Propulsion Mode Transition Status is sent by the Hybrid System controller to indicate the reason for a mode transition occurring or being denied.  This parameter provides confirmation of any mode tran...";
CM_ SG_ 2566701822 HrdSstmEltrAltrntrIndtr "Hybrid System Electric Alternator Indicator: Signal from the hybrid system indicating that the electric alternator is failed or needs servicing.  The alternator Indicator (e.g. dash lamp) is to be activated.00b = Alternator Indicator is off01b = Alte...";
CM_ SG_ 2566701822 HrdSstmHghVltgExpsrIndtr "Hybrid System High Voltage Exposure Indicator: This signal indicates the condition and state of the the hybrid system or electric vehicle system high voltage exposure detection system (e.g. High Voltage Interlock Loop [HVIL]). The high voltage exposu...";
CM_ SG_ 2566701822 HrdSstmIntlztnIndtr "Hybrid System Initialization Indicator: Signal indicating when the hybrid system or electric vehicle system is initialized and ready to start the engine or other power source (e.g. fuel cell). The intent is that this would drive an indicator for the ...";
CM_ SG_ 2566701822 HrdSstmMtrOvrspdAdlAlrm "Hybrid System Motor Overspeed Audible Alarm: Signal from the hybrid system indicating that the overspeed audible alarm should be activated.00b = Motor Overspeed Audible Alarm is off01b = Motor Overspeed Audible Alarm is on10b = Error11b = Not Availab...";
CM_ SG_ 2566701822 HrdSstmMtrOvrspdIndtr "Hybrid System Motor Overspeed Indicator: Signal from the hybrid system indicating that the hybrid system motor is exceeding maximum speed limit.00b = Hybrid System Motor Overspeed Indicator is off01b = Hybrid System Motor Overspeed Indicator is on co...";
CM_ SG_ 2566701822 HrdSstmPrplsnDslStts "Hybrid System Propulsion Disable Status: Indicates if the hybrid system is in a state where propulsion is not available. This may be due to Hybrid System Propulsion Disable Request (SPN 7558), Hybrid System Propulsion Disable Switch (SPN 7554), or Hy...";
CM_ SG_ 2566701822 HrdSstmRgnrtvBrkngIndtr "Hybrid System Regenerative Braking Indicator: Signal from the hybrid system indicating when regenerative braking is active.00b = Regenerative braking is inactive, but not disabled01b = Regenerative braking is active10b = Regenerative braking is disab...";
CM_ SG_ 2566701822 HybridPropulsionModeStatus "Hybrid Propulsion Mode Status : Hybrid Propulsion Mode Status is the current Hybrid System Controller propulsion mode.  This parameter would typically echo the Hybrid Propulsion Mode Request (SPN 7889) assuming the request was honored and the Hybrid ...";
CM_ SG_ 2566701822 HybridSystemEngineAssistStatus "Hybrid System Engine Assist Status: Provides the engine an indication of when the hybrid system is not mechanically assisting rotation (i.e. not motoring) the engine. When this parameter is in state 00b, the engine can perform operations while free o...";
CM_ SG_ 2566701822 HybridSystemOBDRelatedDTCStatus "Hybrid System OBD Related DTC Status: Signal from hybrid system indicating the status of OBD related DTCs00b = Hybrid System does not have an active OBD related DTC01b = Hybrid System has an active OBD related DTC10b = SAE Reserved11b = Not available...";
CM_ SG_ 2566701822 HybridSystemOverheatIndicator "Hybrid System Overheat Indicator: Signal from a hybrid system indicating that at least one of its monitored temperatures is above normal acceptable limits, and as a result, hybrid system operation may be altered or restricted. The indicator is typica...";
CM_ SG_ 2566701822 HybridSystemServiceIndicator "Hybrid System Service Indicator: Signal from the hybrid system indicating that the hybrid system or one of its components requires servicing (e.g. oil change, coolant change).00b = Hybrid Service Indicator is off01b = Hybrid Service Indicator is on c...";
CM_ SG_ 2566701822 HybridSystemStopIndicator "Hybrid System Stop Indicator: Signal from a hybrid system indicating that some aspect of its operation is not functioning correctly, and as a result, the vehicle must be stopped. The indicator is typically a lamp. Distinctions in meaning between the ...";
CM_ SG_ 2566701822 HybridSystemWarningIndicator "Hybrid System Warning Indicator: Signal from a hybrid system indicating that some aspect of its operation is not functioning correctly, and as a result, hybrid system operation may be altered or restricted. The indicator is typically a lamp. Distinct...";
CM_ SG_ 2566701822 PropulsionSystemActive "Propulsion System Active: Indicates when the hybrid system or electric vehicle system is ready to provide or is actively providing propulsion as defined in ARB regulation 13CCR1971.1, which includes the amendments up to the Board hearing date of Augu...";
CM_ SG_ 2566701822 StoredEnergySourceLevel "Stored Energy Source Level: Stored Energy Source Level indicates the current operating stored energy source capacity.In a Diesel-Electric Hybrid, this is the current percentage of the HVES useable capacity.  When the state of charge is below the mini...";
CM_ SG_ 2566701822 StrdEnrgSrInrsngMdAllwd "Stored Energy Source Increasing Mode Allowed : Stored Energy Source Increasing Mode Allowed is sent by the Hybrid System controller to indicate when the Stored Energy Source Increasing Mode is available for use and/or allowed to be used.In a Diesel-E...";
CM_ SG_ 2566701822 StrdEnrgSrOnlMdAllwd "Stored Energy Source Only Mode Allowed: Stored Energy Source Only Mode Allowed is sent by the Hybrid System controller to indicate when Stored Energy Source Only Mode is available for use and/or allowed to be used.In a Diesel-Electric Hybrid, Stored ...";
CM_ BO_ 2566702078 "Fuel Information 4 (Gaseous)";
CM_ SG_ 2566702078 SupplyGasMethanePercentage "Supply Gas Methane Percentage: The percentage of methane in the gas supplied to the engine.";
CM_ BO_ 2566702334 "Aftertreatment 2 SCR Exhaust Gas Temperature 2";
CM_ SG_ 2566702334 Aftrtrtmnt2SCRIntrmdtTmprtr "Aftertreatment 2 SCR Intermediate Temperature: Temperature of engine combustion byproducts at an intermediate point in the SCR component in exhaust bank 2.";
CM_ SG_ 2566702334 Atttt2SCRItdtTptPFMI "Aftertreatment 2 SCR Intermediate Temperature Preliminary FMI: Used to identify the applicable J1939-73 FMI detected in the aftertreatment SCR intermediate temperature sensor by the manufacturer’s sensor control software in exhaust bank 2.  In the ca...";
CM_ BO_ 2566702590 "Aftertreatment 1 SCR Exhaust Gas Temperature 2";
CM_ SG_ 2566702590 Aftrtrtmnt1SCRIntrmdtTmprtr "Aftertreatment 1 SCR Intermediate Temperature: Temperature of engine combustion byproducts at an intermediate point in the SCR component in exhaust bank 1.";
CM_ SG_ 2566702590 Atttt1SCRItdtTptPFMI "Aftertreatment 1 SCR Intermediate Temperature Preliminary FMI: Used to identify the applicable J1939-73 FMI detected in the aftertreatment SCR intermediate temperature sensor by the manufacturer’s sensor control software in exhaust bank 1.  In the ca...";
CM_ BO_ 2566703358 "Electronic Engine Controller 13";
CM_ SG_ 2566703358 EngineDualFuelMode "Engine Dual Fuel Mode: Actual dual fuel mode, off or on.00b = Actual dual fuel mode off01b = Actual dual fuel mode on10b = Reserved11b = Not available";
CM_ SG_ 2566703358 EngineFuelingInhibitAllowed "Engine Fueling Inhibit Allowed: This parameter is broadcast by the engine control system, and indicates to other devices on the network whether or not it will respond to requests to inhibit engine fueling via SPN 5793 Desired Engine Fueling State. Wi...";
CM_ SG_ 2566703358 EngnFlngDsrdRqstCnt "Engine Fueling Desired Request Count: A signal issued by the engine control system indicating the number of devices from which the engine control system has received a fueling desired request. Requests included in this count are either from an extern...";
CM_ SG_ 2566703358 EngnFlngInhtPrvntdRsn "Engine Fueling Inhibit Prevented Reason: If Engine Fueling Inhibit Allowed (SPN 5795) indicates that the engine will inhibit fueling, then this parameter and Engine Fueling Inhibit Prevented Reason Extension (SPN 8145) will indicate the reason.If SPN...";
CM_ SG_ 2566703358 EngnFlngInhtPrvntdRsnExtnsn "Engine Fueling Inhibit Prevented Reason Extension: If Engine Fueling Inhibit Allowed (SPN 5795) indicates that the engine will inhibit fueling, then this parameter indicate the reason.  If more than one reason exists at the same time, then it is up t...";
CM_ SG_ 2566703358 EngnFlngInhtRqstCnt "Engine Fueling Inhibit Request Count: A signal issued by the engine control system indicating the number of devices from which the engine control system has received a fueling not desired request. Requests included in this count are either from an ex...";
CM_ SG_ 2566703358 EngnGsSstttnFlPrntg "Engine Gas Substitution Fuel Percentage: Percentage of Gaseous fuel used. 0% means no Gaseous fuel used and 100% means completely gaseous fuel is used.Gas substitution is the process for a dual fuel engine system of substituting gas, e.g. natural gas...";
CM_ SG_ 2566703358 EngnPrttnDrtOvrrdStts "Engine Protection Derate Override Status: Status of overriding an engine protection derate.This is to temporarily override an engine protection derate due to coolant temperature, oil pressure etc... This is for applications such as fire, rescue, and mi...";
CM_ SG_ 2566703358 FeedbackEngineFuelingState "Feedback Engine Fueling State: This parameter provides feedback to the network that SPN 5793 Desired Engine Fueling State was honored. SPN 5795 Engine Fueling Inhibit Allowed indicates the engine's current ability to honor requests via SPN 5793 Desir...";
CM_ SG_ 2566703358 SrAddrssfCntrllngDvfrFlngStt "Source Address of Controlling Device for Fueling State: The J1939 source address of the device currently controlling the fueling state via SPN 5793.254 (FEh) is used to indicate that the Source Address of Controlling Device for Fueling State paramete...";
CM_ SG_ 2566703358 RemainingEngineMotoringTime "Remaining Engine Motoring Time: A nonzero value of this parameter indicates that the engine requires motoring.  It reflects the consecutive period of time the engine needs motoring (i.e. fueling equal to zero with engine spinning) to allow certain en...";
CM_ SG_ 2566703358 EnginePerformanceBiasLevel "Engine Performance Bias Level: This parameter reflects the actual engine performance bias level in use. For values between 0% and 50%, functionality is biased toward fuel economy, with values closer to 0% indicating more bias toward fuel economy.50% ...";
CM_ SG_ 2566703358 MinimumEngineMotoringSpeed "Minimum Engine Motoring Speed: Indicates the engine speed that needs to be equaled or exceeded while motoring (i.e. fueling equal to zero with engine spinning).   When Remaining Engine Motoring Time (See SPN 12857) is a valid value this speed must be...";
CM_ BO_ 2566703614 "Engine Fuel/Throttle Valve Information 2";
CM_ SG_ 2566703614 EngineFuelValve1Temperature "Engine Fuel Valve 1 Temperature: Temperature of the Engine Fuel Valve 1 drive circuitry. Temperature excursions may affect the torque output.";
CM_ SG_ 2566703614 EngineFuelValve2Temperature "Engine Fuel Valve 2 Temperature: Temperature of the Engine Fuel Valve 2 drive circuitry. Temperature excursions may affect the torque output.";
CM_ SG_ 2566703614 EngineThrottleValve1Position2 "Engine Throttle Valve 1 Position 2: The position of the valve used to regulate the supply of a fluid, usually air or fuel/air mixture, to an engine. This position is measured by a second sensor.";
CM_ SG_ 2566703614 EngineThrottleValve1Temperature "Engine Throttle Valve 1 Temperature: Temperature of the engine throttle valve 1 drive circuitry (SPN 51).  Temperature excursions may affect the torque output.";
CM_ SG_ 2566703614 EngineThrottleValve2Temperature "Engine Throttle Valve 2 Temperature: Temperature of the engine throttle valve 2 drive circuitry (SPN 3673).  Temperature excursions may affect the torque output.";
CM_ SG_ 2566703614 EngnFlRkFlSpplTmprtr "Engine Fuel Rack Fuel Supply Temperature: Temperature of fuel in the engine fuel rack.";
CM_ SG_ 2566703614 EngnTrhrgrWstgtAttr2Tmprtr "Engine Turbocharger Wastegate Actuator 2 Temperature: Temperature of the Engine Turbocharger Wastegate Actuator 2 drive circuitry.  Temperature excursions may affect the torque output.";
CM_ BO_ 2566703870 "Engine Exhaust Gas Recirculation 2 Actuator";
CM_ SG_ 2566703870 EExstGsRt2Att1TptStts "Engine Exhaust Gas Recirculation 2 Actuator 1 Temperature Status: Used to identify the status of the Engine Exhaust Gas Recirculation 2 Actuator 1 drive circuitry temperature.  Temperature excursions may affect the torque output.000b = High Most seve...";
CM_ SG_ 2566703870 EExstGsRt2Att2TptStts "Engine Exhaust Gas Recirculation 2 Actuator 2 Temperature Status: Used to identify the status of the Engine Exhaust Gas Recirculation 2 Actuator 2 drive circuitry temperature.  Temperature excursions may affect the torque output.000b = High Most seve...";
CM_ SG_ 2566703870 EngnExhstGsRrltn2Attr1DsrdPstn "Engine Exhaust Gas Recirculation 2 Actuator 1 Desired Position: The requested position of the Engine Exhaust Gas Recirculation 2 Actuator 1 by the engine ECU, where 0% represents fully closed and 100% represents fully open.This is the position that t...";
CM_ SG_ 2566703870 EngnExhstGsRrltn2Attr1OprtnStts "Engine Exhaust Gas Recirculation 2 Actuator 1 Operation Status: Used to identify the status of Exhaust Gas Recirculation 2 Actuator 10000b = Normal0001b = Alarm (fully operational but needs service)0010b = Alarm High Severity (functional but transien...";
CM_ SG_ 2566703870 EngnExhstGsRrltn2Attr1PrlmnrFMI "Engine Exhaust Gas Recirculation 2 Actuator 1 Preliminary FMI: Used to identify the applicable J1939-73 FMI detected in the Engine Exhaust Gas Recirculation 2 Actuator 1 by the manufacturer’s software.  When there are multiple failures, the most seve...";
CM_ SG_ 2566703870 EngnExhstGsRrltn2Attr1Tmprtr "Engine Exhaust Gas Recirculation 2 Actuator 1 Temperature: Temperature of the Engine Exhaust Gas Recirculation 2 Actuator 1 drive circuitry.  Temperature excursions may affect the torque output.";
CM_ SG_ 2566703870 EngnExhstGsRrltn2Attr2DsrdPstn "Engine Exhaust Gas Recirculation 2 Actuator 2 Desired Position: The requested position of the Engine Exhaust Gas Recirculation 2 Actuator 2 by the engine ECU, where 0% represents fully closed and 100% represents fully open.This is the position that t...";
CM_ SG_ 2566703870 EngnExhstGsRrltn2Attr2OprtnStts "Engine Exhaust Gas Recirculation 2 Actuator 2 Operation Status: Used to identify the status of Exhaust Gas Recirculation 2 Actuator 20000b = Normal0001b = Alarm (fully operational but needs service)0010b = Alarm High Severity (functional but transien...";
CM_ SG_ 2566703870 EngnExhstGsRrltn2Attr2PrlmnrFMI "Engine Exhaust Gas Recirculation 2 Actuator 2 Preliminary FMI: Used to identify the applicable J1939-73 FMI detected in the Engine Exhaust Gas Recirculation 2 Actuator 2 by the manufacturer’s software. When there are multiple failures, the most sever...";
CM_ SG_ 2566703870 EngnExhstGsRrltn2Attr2Tmprtr "Engine Exhaust Gas Recirculation 2 Actuator 2 Temperature: Temperature of the Engine Exhaust Gas Recirculation 2 Actuator 2 drive circuitry.  Temperature excursions may affect the torque output.";
CM_ BO_ 2566704126 "Engine Exhaust Gas Recirculation 1 Actuator";
CM_ SG_ 2566704126 EExstGsRt1Att1TptStts "Engine Exhaust Gas Recirculation 1 Actuator 1 Temperature Status: Used to identify the status of the Engine Exhaust Gas Recirculation 1 Actuator 1 drive circuitry temperature.  Temperature excursions may affect the torque output.000b = High Most seve...";
CM_ SG_ 2566704126 EExstGsRt1Att2TptStts "Engine Exhaust Gas Recirculation 1 Actuator 2 Temperature Status: Used to identify the status of the Engine Exhaust Gas Recirculation 1 Actuator 2 drive circuitry temperature.  Temperature excursions may affect the torque output.000b = High Most seve...";
CM_ SG_ 2566704126 EngnExhstGsRrltn1Attr1DsrdPstn "Engine Exhaust Gas Recirculation 1 Actuator 1 Desired Position: The requested position of the Engine Exhaust Gas Recirculation 1 Actuator 1 by the engine ECU, where 0% represents fully closed and 100% represents fully open.This is the position that t...";
CM_ SG_ 2566704126 EngnExhstGsRrltn1Attr1OprtnStts "Engine Exhaust Gas Recirculation 1 Actuator 1 Operation Status: Used to identify the status of Exhaust Gas Recirculation 1 Actuator 10000b = Normal0001b = Alarm (fully operational but needs service)0010b = Alarm High Severity (functional but transien...";
CM_ SG_ 2566704126 EngnExhstGsRrltn1Attr1PrlmnrFMI "Engine Exhaust Gas Recirculation 1 Actuator 1 Preliminary FMI: Used to identify the applicable J1939-73 FMI detected in the Engine Exhaust Gas Recirculation 1 Actuator 1 by the manufacturer’s software.  When there are multiple failures, the most seve...";
CM_ SG_ 2566704126 EngnExhstGsRrltn1Attr1Tmprtr "Engine Exhaust Gas Recirculation 1 Actuator 1 Temperature: Temperature of the Engine Exhaust Gas Recirculation 1 Actuator 1 drive circuitry.  Temperature excursions may affect the torque output.";
CM_ SG_ 2566704126 EngnExhstGsRrltn1Attr2DsrdPstn "Engine Exhaust Gas Recirculation 1 Actuator 2 Desired Position: The requested position of the Engine Exhaust Gas Recirculation 1 Actuator 2 by the engine ECU, where 0% represents fully closed and 100% represents fully open.This is the position that t...";
CM_ SG_ 2566704126 EngnExhstGsRrltn1Attr2OprtnStts "Engine Exhaust Gas Recirculation 1 Actuator 2 Operation Status: Used to identify the status of Exhaust Gas Recirculation 1 Actuator 20000b = Normal0001b = Alarm (fully operational but needs service)0010b = Alarm High Severity (functional but transien...";
CM_ SG_ 2566704126 EngnExhstGsRrltn1Attr2PrlmnrFMI "Engine Exhaust Gas Recirculation 1 Actuator 2 Preliminary FMI: Used to identify the applicable J1939-73 FMI detected in the Engine Exhaust Gas Recirculation 1 Actuator 2 by the manufacturer’s software. When there are multiple failures, the most sever...";
CM_ SG_ 2566704126 EngnExhstGsRrltn1Attr2Tmprtr "Engine Exhaust Gas Recirculation 1 Actuator 2 Temperature: Temperature of the Engine Exhaust Gas Recirculation 1 Actuator 2 drive circuitry.  Temperature excursions may affect the torque output.";
CM_ BO_ 2566704382 "Electronic Engine Controller 12";
CM_ SG_ 2566704382 Aftrtrtmnt1Otlt1GsSnsrPwrSppl "Aftertreatment 1 Outlet 1 Gas Sensor Power Supply: State signal which indicates when the Aftertreatment 1 Outlet 1 Gas Sensor driver output is being driven. On means the ECU is powering the Aftertreatment 1 Outlet 1 Gas Sensor. Note that the ECU is e...";
CM_ SG_ 2566704382 Aftrtrtmnt1Otlt2GsSnsrPwrSppl "Aftertreatment 1 Outlet 2 Gas Sensor Power Supply: State signal which indicates when the Aftertreatment 1 Outlet 2 Gas Sensor driver output is being driven.00b = Off01b = On: The ECU is powering the Aftertreatment 1 Outlet 2 Gas Sensor10b = Error11b ...";
CM_ SG_ 2566704382 Aftrtrtmnt2Otlt1GsSnsrPwrSppl "Aftertreatment 2 Outlet 1 Gas Sensor Power Supply: State signal which indicates when the Aftertreatment 2 Outlet 1 Gas Sensor driver output is being driven.  On means the ECU is powering the Aftertreatment 2 Outlet 1 Gas Sensor.  Note that the ECU is...";
CM_ SG_ 2566704382 EngnExhst1GsSnsr1PwrSppl "Engine Exhaust 1 Gas Sensor 1 Power Supply: State signal which indicates when the Engine Exhaust 1 Intake 1 Gas Sensor driver output is being driven.  On means the ECU is powering the Engine Exhaust 1 Intake 1 Gas Sensor.  Note that the ECU is extern...";
CM_ SG_ 2566704382 EngnExhst2GsSnsr1PwrSppl "Engine Exhaust 2 Gas Sensor 1 Power Supply: State signal which indicates when the Engine Exhaust 2 Intake 1 Gas Sensor driver output is being driven.  On means the ECU is powering the Engine Exhaust 2 Intake 1 Gas Sensor.  Note that the ECU is extern...";
CM_ SG_ 2566704382 EngnExhst1GsSnsr2PwrSppl "Engine Exhaust 1 Gas Sensor 2 Power Supply: State signal which indicates when the Engine Exhaust 1 Gas Sensor 2 driver output is being driven.  This sensor is located at the intake of the aftertreatment system if an aftertreatment system exists.00b =...";
CM_ BO_ 2566705150 "NOx Sensor Self-Diagnosis Request";
CM_ SG_ 2566705150 Atttt1OttNOxSsSdssT "Aftertreatment 1 Outlet NOx Sensor Self-diagnosis Trigger: Signal to trigger the self-diagnosis of NOx sensor ATO1 (Aftertreatment Outlet Bank 1)0000b = Diagnostic mode disabled0001b = NOx Sensor ATO1 Self-diagnosis Request at Lambda=1.00010b = NOx S...";
CM_ SG_ 2566705150 Atttt2OttNOxSsSdssT "Aftertreatment 2 Outlet NOx Sensor Self-diagnosis Trigger: Signal to trigger the self-diagnosis of NOx sensor ATO2 (Aftertreatment Outlet Bank 2)0000b = Diagnostic mode disabled0001b = NOx Sensor ATO2 Self-diagnosis Request at Lambda=1.00010b = NOx S...";
CM_ SG_ 2566705150 EngnExhst1NOxSnsrSlfdgnssTrggr "Engine Exhaust 1 NOx Sensor Self-diagnosis Trigger: Signal to trigger the self-diagnosis of NOx sensor Engine Exhaust Bank 1 (EEB1).  This sensor is located at the intake of the aftertreatment system if an aftertreatment system exists.0000b = Diagnos...";
CM_ SG_ 2566705150 EngnExhst2NOxSnsrSlfdgnssTrggr "Engine Exhaust 2 NOx Sensor Self-diagnosis Trigger: Signal to trigger the self-diagnosis of NOx sensor Engine Exhaust Bank 2 (EEB2).  This sensor is located at the intake of the aftertreatment system if an aftertreatment system exists.0000b = Diagnos...";
CM_ BO_ 2566705406 "Engine Particulate Sensor Information";
CM_ SG_ 2566705406 Aftrtrtmnt1PrtltSnsr "Aftertreatment 1 Particulate Sensor: The particulate sensor measures the mass concentration of particulate matter in the exhaust downstream of the DPF in exhaust bank 1.";
CM_ SG_ 2566705406 Aftrtrtmnt1PrtltSnsrCrrnt "Aftertreatment 1 Particulate Sensor Current: Raw aftertreatment 1 PM sensor electrical current reading.";
CM_ SG_ 2566705406 Aftrtrtmnt2PrtltSnsr "Aftertreatment 2 Particulate Sensor: The particulate sensor measures the mass concentration of particulate matter in the exhaust downstream of the DPF in exhaust bank 2.";
CM_ BO_ 2566706686 "Aftertreatment 1 Diesel Exhaust Fluid Pump 1 Information";
CM_ SG_ 2566706686 Aftrtrtmnt1DslExhstFldPmpHtr "Aftertreatment 1 Diesel Exhaust Fluid Pump Heater: Percentage of heating applied to the aftertreatment 1 diesel exhaust fluid pump heater. A value of 0% means no heating applied, a value of 100% means full heating applied. The diesel exhaust fluid pu...";
CM_ SG_ 2566706686 Atttt1DsExstFdDsUt1HtR "Aftertreatment 1 Diesel Exhaust Fluid Dosing Unit 1 Heater Relay: The status of the relay that controls Aftertreatment 1 diesel exhaust fluid dosing Unit 1 Heater.00b = Off01b = On10b = Error11b = Not available";
CM_ SG_ 2566706686 Atttt1DsExstFdPp2MtSpd "Aftertreatment 1 Diesel Exhaust Fluid Pump 2 Motor Speed: Rotational speed of the motor driving the second pump for the diesel exhaust fluid used in aftertreatment system 1 (exhaust bank 1).";
CM_ SG_ 2566706686 Atttt1DsExstFdPpPwSpp "Aftertreatment 1 Diesel Exhaust Fluid Pump Power Supply: State signal which indicates when the aftertreatment 1 Diesel Exhaust Fluid (DEF) pump power output is being driven.  On means the ECU is powering the aftertreatment 1 DEF pump power output.  N...";
CM_ BO_ 2566706942 "Aftertreatment 1 Diesel Particulate Filter 2 Soot 5";
CM_ SG_ 2566706942 Atttt1DsPttFt2StSsAssFq3 "Aftertreatment 1 Diesel Particulate Filter 2 Soot Sensor Analysis Frequency 3: The analysis frequency associated with the frequency 3 soot signal for the diesel particulate filter 2 soot sensor.  See SPN 5646.";
CM_ SG_ 2566706942 Atttt1DsPttFt2StSsAssFq4 "Aftertreatment 1 Diesel Particulate Filter 2 Soot Sensor Analysis Frequency 4: The analysis frequency associated with the frequency 4 soot signal for the diesel particulate filter 2 soot sensor.  See SPN 5647.";
CM_ SG_ 2566706942 Atttt1DsPttFt2StSsFq3StS "Aftertreatment 1 Diesel Particulate Filter 2 Soot Sensor Frequency 3 Soot Signal: The soot signal attenuation measurement for analysis frequency 3 for the diesel particulate filter 2 soot sensor.  See SPN 5646.";
CM_ SG_ 2566706942 Atttt1DsPttFt2StSsFq4StS "Aftertreatment 1 Diesel Particulate Filter 2 Soot Sensor Frequency 4 Soot Signal: The soot signal attenuation measurement for analysis frequency 4 for the diesel particulate filter 2 soot sensor.  See SPN 5647.";
CM_ BO_ 2566707198 "Aftertreatment 1 Diesel Particulate Filter 2 Soot 4";
CM_ SG_ 2566707198 Atttt1DsPttFt2StSsAssFq1 "Aftertreatment 1 Diesel Particulate Filter 2 Soot Sensor Analysis Frequency 1: The analysis frequency associated with the frequency 1 soot signal for the diesel particulate filter 2 soot sensor.  See SPN 5644.";
CM_ SG_ 2566707198 Atttt1DsPttFt2StSsAssFq2 "Aftertreatment 1 Diesel Particulate Filter 2 Soot Sensor Analysis Frequency 2: The analysis frequency associated with the frequency 2 soot signal for the diesel particulate filter 2 soot sensor.  See SPN 5645.";
CM_ SG_ 2566707198 Atttt1DsPttFt2StSsFq1StS "Aftertreatment 1 Diesel Particulate Filter 2 Soot Sensor Frequency 1 Soot Signal: The soot signal attenuation measurement for analysis frequency 1 for the diesel particulate filter 2 soot sensor.  See SPN 5644.";
CM_ SG_ 2566707198 Atttt1DsPttFt2StSsFq2StS "Aftertreatment 1 Diesel Particulate Filter 2 Soot Sensor Frequency 2 Soot Signal: The soot signal attenuation measurement for analysis frequency 2 for the diesel particulate filter 2 soot sensor.  See SPN 5645.";
CM_ BO_ 2566707454 "Aftertreatment 1 Diesel Particulate Filter 2 Soot 3";
CM_ SG_ 2566707454 Atttt1DsPttFt2StSsAssRqstFq1 "Aftertreatment 1 Diesel Particulate Filter 2 Soot Sensor Analysis Request Frequency 1: First requested analysis frequency for the diesel particulate filter 2 soot sensor.";
CM_ SG_ 2566707454 Atttt1DsPttFt2StSsAssRqstFq2 "Aftertreatment 1 Diesel Particulate Filter 2 Soot Sensor Analysis Request Frequency 2: Second requested analysis frequency for the diesel particulate filter 2 soot sensor.";
CM_ SG_ 2566707454 Atttt1DsPttFt2StSsAssRqstFq3 "Aftertreatment 1 Diesel Particulate Filter 2 Soot Sensor Analysis Request Frequency 3: Third requested analysis frequency for the diesel particulate filter 2 soot sensor.";
CM_ SG_ 2566707454 Atttt1DsPttFt2StSsAssRqstFq4 "Aftertreatment 1 Diesel Particulate Filter 2 Soot Sensor Analysis Request Frequency 4: Fourth requested analysis frequency for the diesel particulate filter 2 soot sensor.";
CM_ BO_ 2566707710 "Aftertreatment 1 Diesel Particulate Filter 1 Soot 5";
CM_ SG_ 2566707710 Atttt1DsPttFt1StSsAssFq3 "Aftertreatment 1 Diesel Particulate Filter 1 Soot Sensor Analysis Frequency 3: The analysis frequency associated with the frequency 3 soot signal for the diesel particulate filter 1 soot sensor.  See SPN 5634.";
CM_ SG_ 2566707710 Atttt1DsPttFt1StSsAssFq4 "Aftertreatment 1 Diesel Particulate Filter 1 Soot Sensor Analysis Frequency 4: The analysis frequency associated with the frequency 4 soot signal for the diesel particulate filter 1 soot sensor.  See SPN 5635.";
CM_ SG_ 2566707710 Atttt1DsPttFt1StSsFq3StS "Aftertreatment 1 Diesel Particulate Filter 1 Soot Sensor Frequency 3 Soot Signal: The soot signal attenuation measurement for analysis frequency 3 for the diesel particulate filter 1 soot sensor.  See SPN 5634.";
CM_ SG_ 2566707710 Atttt1DsPttFt1StSsFq4StS "Aftertreatment 1 Diesel Particulate Filter 1 Soot Sensor Frequency 4 Soot Signal: The soot signal attenuation measurement for analysis frequency 4 for the diesel particulate filter 1 soot sensor.  See SPN 5635.";
CM_ BO_ 2566707966 "Aftertreatment 1 Diesel Particulate Filter 1 Soot 4";
CM_ SG_ 2566707966 Atttt1DsPttFt1StSsAssFq1 "Aftertreatment 1 Diesel Particulate Filter 1 Soot Sensor Analysis Frequency 1: The analysis frequency associated with the frequency 1 soot signal for the diesel particulate filter 1 soot sensor.  See SPN 5632.";
CM_ SG_ 2566707966 Atttt1DsPttFt1StSsAssFq2 "Aftertreatment 1 Diesel Particulate Filter 1 Soot Sensor Analysis Frequency 2: The analysis frequency associated with the frequency 2 soot signal for the diesel particulate filter 1 soot sensor.  See SPN 5633.";
CM_ SG_ 2566707966 Atttt1DsPttFt1StSsFq1StS "Aftertreatment 1 Diesel Particulate Filter 1 Soot Sensor Frequency 1 Soot Signal: The soot signal attenuation measurement for analysis frequency 1 for the diesel particulate filter 1 soot sensor.  See SPN 5632.";
CM_ SG_ 2566707966 Atttt1DsPttFt1StSsFq2StS "Aftertreatment 1 Diesel Particulate Filter 1 Soot Sensor Frequency 2 Soot Signal: The soot signal attenuation measurement for analysis frequency 2 for the diesel particulate filter 1 soot sensor.  See SPN 5633.";
CM_ BO_ 2566708222 "Aftertreatment 1 Diesel Particulate Filter 1 Soot 3";
CM_ SG_ 2566708222 Atttt1DsPttFt1StSsAssRqstFq1 "Aftertreatment 1 Diesel Particulate Filter 1 Soot Sensor Analysis Request Frequency 1: First requested analysis frequency for the diesel particulate filter 1 soot sensor.";
CM_ SG_ 2566708222 Atttt1DsPttFt1StSsAssRqstFq2 "Aftertreatment 1 Diesel Particulate Filter 1 Soot Sensor Analysis Request Frequency 2: Second requested analysis frequency for the diesel particulate filter 1 soot sensor.";
CM_ SG_ 2566708222 Atttt1DsPttFt1StSsAssRqstFq3 "Aftertreatment 1 Diesel Particulate Filter 1 Soot Sensor Analysis Request Frequency 3: Third requested analysis frequency for the diesel particulate filter 1 soot sensor.";
CM_ SG_ 2566708222 Atttt1DsPttFt1StSsAssRqstFq4 "Aftertreatment 1 Diesel Particulate Filter 1 Soot Sensor Analysis Request Frequency 4: Fourth requested analysis frequency for the diesel particulate filter 1 soot sensor.";
CM_ BO_ 2566708478 "Cruise Control / Vehicle Speed 3";
CM_ SG_ 2566708478 AdptvCrsCntrlRdnssStts "Adaptive Cruise Control Readiness Status: This parameter is used to indicate an application's state of readiness for responding to commands from an adaptive cruise control system controller.00b = Off -- Cruise Control System is not configured to acce...";
CM_ SG_ 2566708478 AEBSreadinessstate "AEBS readiness state: Advanced emergency braking systems (AEBS) will limit the engine torque via TSC1 during warning and braking phases. Therefore the engine controller gives a feedback to the AEBS if it is configured and able to obey these limitatio...";
CM_ SG_ 2566708478 CrsCntrlDrvrCnlltnStts "Cruise Control Driver Cancellation Status: State signal which indicates that the cruise control is cancelled by driver action.  Driver actions could include switch off, brake pedal activation, clutch pedal actuation, cancel switch, or other reasons d...";
CM_ SG_ 2566708478 CrsCntrlStSpdHghRsltn "Cruise Control Set Speed (High Resolution): Value of set (chosen) velocity of velocity control system. See SPN 86 for an alternate resolution.If an algorithm that can modify the cruise control set point exists in the system, such as Predictive Cruise...";
CM_ SG_ 2566708478 CruiseControlSpeed "Cruise Control Speed: This parameter is the vehicle speed that the cruise control algorithm is currently using as its cruise control set point.Cruise Control Speed (SPN 7319) will include the effects of other algorithms, such as Predictive Cruise Con...";
CM_ SG_ 2566708478 CruiseControlSystemCommandState "Cruise Control System Command State: Indicates the current state of the cruise control system due to the Cruise Control System Commands, which include Cruise Control Disable Command (SPN 5603), Cruise Control Resume Command (SPN 5604), Cruise Control...";
CM_ SG_ 2566708478 PrdtvCrsCntrlStSpdOffstStts "Predictive Cruise Control Set Speed Offset Status: This parameter indicates if the cruise control algorithm is currently adding the value in Predictive Cruise Control Set Speed Offset (SPN 7316) to the Cruise Control Set Speed (SPN 86 or SPN 6809) fo...";
CM_ SG_ 2566708478 SAddssCtDvDsCsCt "Source Address of Controlling Device for Disabling Cruise Control: The source address of the SAE J1939 device that is currently sending the Cruise Control Disable Command (SPN 5603).If there are multiple devices sending Cruise Control Disable Command...";
CM_ SG_ 2566708478 SAddssCtDvPsCsCt "Source Address of Controlling Device for Pausing Cruise Control: The source address of the SAE J1939 device that is currently sending the Cruise Control Pause Command (SPN 5605).If there are multiple devices sending Cruise Control Pause Command with ...";
CM_ BO_ 2566708734 "Aftertreatment 2 Air Control 3";
CM_ SG_ 2566708734 Aftrtrtmnt2SndrArAsltPrssr "Aftertreatment 2 Secondary Air Absolute Pressure: Absolute pressure of the secondary air for aftertreatment 2. Secondary air is air provided to the exhaust system (per SAE J2403).For gage pressure, see SPN 3838.";
CM_ BO_ 2566708990 "Aftertreatment 1 Air Control 3";
CM_ SG_ 2566708990 Aftrtrtmnt1SndrArAsltPrssr "Aftertreatment 1 Secondary Air Absolute Pressure: Absolute pressure of the secondary air for aftertreatment 1. Secondary air is air provided to the exhaust system (per SAE J2403).For gage pressure, see SPN 3837.";
CM_ SG_ 2566708990 OprtrIndmntOvrrdRnwlRqrd "Operator Inducement Override Renewal Required: Indicates the required operator inducement override renewal state.00b = Not Required01b = Required10b = Error11b = Not Available";
CM_ BO_ 2566709246 "Engine Fluid Level/Pressure 12";
CM_ SG_ 2566709246 EFSppPpItAstPssExtddR "Engine Fuel Supply Pump Intake Absolute Pressure (Extended Range): Absolute pressure of fuel at the fuel supply pump intake. See Figures SPN16_A & SPN16_B. See SPN 1381 for alternate resolution.Engine Fuel Supply Pump Intake Absolute Pressure (Extend...";
CM_ SG_ 2566709246 EngineFuelFilterDegradation "Engine Fuel Filter Degradation: The estimated percentage relative to the useful life of the engine fuel filter. This is not a calculation of the physical restriction of the filter.  0% is typical of a new filter.  100% is typical of an end of life fi...";
CM_ SG_ 2566709246 EngineFuelReturnPressure "Engine Fuel Return Pressure: Used to read fuel (or gas) pressure passing through the return line.";
CM_ SG_ 2566709246 EngnFlDlvrAsltPrssr "Engine Fuel Delivery Absolute Pressure: Absolute pressure of fuel in system as delivered from supply pump to the injection pump.  See also SPN 94 for Fuel Delivery Pressure (Gage).";
CM_ SG_ 2566709246 EngnFltrdFlDlvrAsltPrssr "Engine Filtered Fuel Delivery Absolute Pressure: Absolute pressure of fuel in system as delivered from supply pump to the injection pump after the pressure side fuel filter.  See SPN 5579 for gage pressure of fuel in system after the pressure side fu...";
CM_ SG_ 2566709246 EngnFltrdFlDlvrPrssr "Engine Filtered Fuel Delivery Pressure: Gage pressure of fuel in system as delivered from supply pump to the injection pump after the pressure side fuel filter.  See SPN 5580 for absolute pressure of fuel in system after the pressure side fuel filter...";
CM_ SG_ 2566709246 EngnThrttlVlv2DffrntlPrssr "Engine Throttle Valve 2 Differential Pressure: The differential pressure between the intake and outlet of the throttle valve 2 (SPN 3673). The differential pressure is measured from the intake with respect to the outlet of the throttle valve.";
CM_ BO_ 2566709502 "Diesel Particulate Filter Control 2";
CM_ SG_ 2566709502 Aftertreatment1FuelMassRate "Aftertreatment 1 Fuel Mass Rate: Mass rate of total fuel being delivered to aftertreatment 1 for DPF regeneration.";
CM_ SG_ 2566709502 Aftertreatment2FuelMassRate "Aftertreatment 2 Fuel Mass Rate: Mass rate of total fuel being delivered to Atertreatment 2 for DPF regeneration.";
CM_ SG_ 2566709502 Atttt1DsPttFtItTptStPt "Aftertreatment 1 Diesel Particulate Filter Intake Temperature Set Point: Set point temperature for the particulate filter (DPF) regeneration at the intake to the DPF for Exhaust bank 1.";
CM_ SG_ 2566709502 EngineUnburnedFuelPercentage "Engine Unburned Fuel Percentage: The unburned amount of diesel fuel coming out of the engine. This fuel increases the temperature while oxidated in the DOC. Therefore, this amount of fuel also needs to be taken into account of the HCD temperature con...";
CM_ BO_ 2566709758 "Fuel Economy 2 (Liquid)";
CM_ SG_ 2566709758 EngineDieselFuelDemandRate "Engine Diesel Fuel Demand Rate: Amount of diesel fuel that would be consumed by an engine per unit of time if it were not substituting gaseous fuel.  This parameter is the sum of SPN 183 and the amount of diesel fuel that is being displaced by gaseou...";
CM_ SG_ 2566709758 EngineFuelRateHighResolution "Engine Fuel Rate (High Resolution): Amount of fuel consumed by engine per unit of time.  NOTE - See SPN 183 for alternate resolution.";
CM_ BO_ 2566710014 "Supplemental Fan Status";
CM_ SG_ 2566710014 SpplmntlFnCntrllrECUTmprtr "Supplemental Fan Controller ECU Temperature: Measured temperature of Supplemental Fan Controller ECU.";
CM_ SG_ 2566710014 SpplmntlFnCntrllrTmprtrStts "Supplemental Fan Controller Temperature Status: Internal Controller Temperature Status of Supplemental Fan.000b = High most severe 001b = High Least severe 010b = In Range 011b = Low Least severe 100b = Low Most severe 101b = Not Defined 110b = Error...";
CM_ SG_ 2566710014 SupplementalFanCurrent "Supplemental Fan Current: Measured electrical current of supplemental fan drive.";
CM_ SG_ 2566710014 SupplementalFanDirectionStatus "Supplemental Fan Direction Status: Rotational Direction of Supplemental Fan. Fan could be spinning forward or reverse.00b = Forward01b = Reverse10b = Error11b = Not available/Not installed";
CM_ SG_ 2566710014 SupplementalFanDriveStatus "Supplemental Fan Drive Status: The drive status of the Supplemental Fan. This status parameter indicates the overall health of the fan drive. It will indicate that the fan is working OK or if there is an internal fault such as open winding or interna...";
CM_ SG_ 2566710014 SupplementalFanEnableStatus "Supplemental Fan Enable Status: Enable/Disable Status of Supplemental Fan.00b = Disabled01b = Enabled10b = Error11b = Not available/Not installed";
CM_ SG_ 2566710014 SupplementalFanPower "Supplemental Fan Power: Estimated Power output of Supplemental Fan";
CM_ SG_ 2566710014 SupplementalFanSpeed "Supplemental Fan Speed: Measured speed of supplemental fan.";
CM_ SG_ 2566710014 SupplementalFanVelocityStatus "Supplemental Fan Velocity Status: Status of the rotational velocity of Supplemental Fan. Used to indicate if the fan is spinning at the desired speed. If fan is not able to obtain the commanded speed, velocity error is indicated. If fan is unable to ...";
CM_ BO_ 2566710526 "Engine Fuel Properties";
CM_ SG_ 2566710526 EngineFuelDensity "Engine Fuel Density: Density of engine fuel";
CM_ SG_ 2566710526 EngineFuelDynamicViscosity "Engine Fuel Dynamic Viscosity: Dynamic viscosity of engine fuel";
CM_ SG_ 2566710526 EngnFl1Tmprtr1HghRsltn "Engine Fuel 1 Temperature 1 (High Resolution): Engine Fuel Temperature of the first fuel type. See also SPNs 174 or 3468 for alternate resolution.";
CM_ SG_ 2566710526 EngnFlDltrtHghRsltn "Engine Fuel Dielectricity (High Resolution): Engine fuel relative dielectricity.";
CM_ BO_ 2566710782 "Hydraulic Oil Properties";
CM_ SG_ 2566710782 HdrlOlRltvDltrtHghRsltn "Hydraulic Oil Relative Dielectricity (High Resolution): Hydraulic oil relative dielectricity used to describe the hydraulic oil quality.  This hydraulic fluid is for the entire hydraulics system of a piece of equipment.";
CM_ SG_ 2566710782 HdrlOlTmprtrHghRsltn "Hydraulic Oil Temperature (High Resolution): Hydraulic Oil Temperature.  This hydraulic fluid is for the entire hydraulics system of a piece of equipment.";
CM_ SG_ 2566710782 HydraulicOilDensity "Hydraulic Oil Density: Density of hydraulic oil.  This hydraulic fluid is for the entire hydraulics system of a piece of equipment.";
CM_ SG_ 2566710782 HydraulicOilDynamicViscosity "Hydraulic Oil Dynamic Viscosity: Dynamic viscosity of hydraulic oil.  This hydraulic fluid is for the entire hydraulics system of a piece of equipment.";
CM_ BO_ 2566711038 "Vehicle/Chassis Lubrication System 2";
CM_ SG_ 2566711038 LubricationCycleModeLockStatus "Lubrication Cycle Mode Lock Status: Reports status of the ability to change the lubrication cycle mode.  Locking the lubrication mode would prevent the changing of the lubrication cycle mode, perhaps by an operator00b = Not Locked01b = Locked10b = Er...";
CM_ SG_ 2566711038 LubricationCycleModeStatus "Lubrication Cycle Mode Status: Reports the current lubrication cycle mode of the lubrication system000b = Cycle mode # 1 (Lowest Lubrication Frequency)001b = Cycle mode # 2010b = Cycle mode # 3 (Highest Lubrication Frequency)011b to 101b = Reserved 1...";
CM_ SG_ 2566711038 LubricationOperationModeStatus "Lubrication Operation Mode Status: Reports the current operational mode status of the lubrication system.  Automatic is the normal operation mode of lubrication system. In this mode the operator has the privilege to change duty cycle mode, if the lub...";
CM_ SG_ 2566711038 LubricationPumpEnableStatus "Lubrication Pump Enable Status: Reports the operational status of the lubrication system pump.  In the disabled state, the lubrication pump will not run a lubrication cycle.  In the enabled state, the lubrication system will perform normal operations...";
CM_ SG_ 2566711038 LubricationReservoirLevel "Lubrication Reservoir Level: Reports the status of the lubrication system reservior level.  The lubrication reservoir stores the grease for the lubrication system. The lubrication pump draws grease from this reservoir and pushes it into the vehicle/c...";
CM_ SG_ 2566711038 LubricationTimingCycleStatus "Lubrication Timing Cycle Status: Reports the status of the lubrication activation clock.00b = Paused 01b = Enabled10b = Error 11b = Not available or not installed     Note:  In some vehicles or machines, lubrication is only required when the vehicle ...";
CM_ BO_ 2566711294 "Engine Configuration 3";
CM_ SG_ 2566711294 EngnFrtnPrntTrqAtIdlPnt1 "Engine Friction Percent Torque At Idle, Point 1: The static portion of the friction torque at speed point 1 (SPN 188) of the engine torque map in the engine configuration message.  This parameter does not include Estimated Pumping – Percent Torque (S...";
CM_ SG_ 2566711294 EngnFrtnPrntTrqPnt2 "Engine Friction Percent Torque, Point 2: The static portion of the friction torque at speed point 2 (SPN 528) of the engine torque map in the engine configuration message.  This parameter does not include Estimated Pumping – Percent Torque (SPN 5398)...";
CM_ SG_ 2566711294 EngnFrtnPrntTrqPnt3 "Engine Friction Percent Torque, Point 3: The static portion of the friction torque at speed point 3 (SPN 529) of the engine torque map in the engine configuration message.  This parameter does not include Estimated Pumping – Percent Torque (SPN 5398)...";
CM_ SG_ 2566711294 EngnFrtnPrntTrqPnt4 "Engine Friction Percent Torque, Point 4: The static portion of the friction torque at speed point 4 (SPN 530) of the engine torque map in the engine configuration message.  This parameter does not include Estimated Pumping – Percent Torque (SPN 5398)...";
CM_ SG_ 2566711294 EngnFrtnPrntTrqPnt5 "Engine Friction Percent Torque, Point 5: The static portion of the friction torque at speed point 5 (SPN 531) of the engine torque map in the engine configuration message.  This parameter does not include Estimated Pumping – Percent Torque (SPN 5398)...";
CM_ SG_ 2566711294 EngnFrtnPrntTrqPnt6 "Engine Friction Percent Torque, Point 6: For engine configuration map modes 1 and 2, this is the static portion of the friction torque at speed point 6 (SPN 532) of the engine torque map.  For engine configuration map mode 3, this parameter is the st...";
CM_ SG_ 2566711294 EngnFrtnPrntTrqPnt7 "Engine Friction Percent Torque, Point 7: The static portion of the friction torque at speed point 7 (SPN 533) of the engine torque map in the engine configuration message.  This parameter does not include Estimated Pumping – Percent Torque (SPN 5398)...";
CM_ BO_ 2566711550 "Intake Valve Actuation Control";
CM_ SG_ 2566711550 ItVvAttSstOPss1SdCt "Intake Valve Actuation System Oil Pressure 1 Solenoid Control: Indicates the current command to the solenoid that controls the intake valve actuation system oil pressure 1 valve. This valve opens or closes a connection from the intake valve actuation...";
CM_ SG_ 2566711550 ItVvAttSstOPss2SdCt "Intake Valve Actuation System Oil Pressure 2 Solenoid Control: Indicates the current command to the solenoid that controls the intake valve actuation system oil pressure 2 valve. This valve opens or closes a connection from the intake valve actuation...";
BA_DEF_ SG_  "SPN" INT 0 524287;
BA_DEF_ BO_  "VFrameFormat" ENUM  "StandardCAN","ExtendedCAN","reserved","J1939PG";
BA_DEF_DEF_  "SPN" 0;
BA_DEF_DEF_  "VFrameFormat" "J1939PG";
BA_ "SPN" SG_ 2566670334 Axle10MonitoredTireCount 6960;
BA_ "SPN" SG_ 2566670334 Axle11MonitoredTireCount 6961;
BA_ "SPN" SG_ 2566670334 Axle12MonitoredTireCount 6962;
BA_ "SPN" SG_ 2566670334 Axle1MonitoredTireCount 6951;
BA_ "SPN" SG_ 2566670334 Axle2MonitoredTireCount 6952;
BA_ "SPN" SG_ 2566670334 Axle3MonitoredTireCount 6953;
BA_ "SPN" SG_ 2566670334 Axle4MonitoredTireCount 6954;
BA_ "SPN" SG_ 2566670334 Axle5MonitoredTireCount 6955;
BA_ "SPN" SG_ 2566670334 Axle6MonitoredTireCount 6956;
BA_ "SPN" SG_ 2566670334 Axle7MonitoredTireCount 6957;
BA_ "SPN" SG_ 2566670334 Axle8MonitoredTireCount 6958;
BA_ "SPN" SG_ 2566670334 Axle9MonitoredTireCount 6959;
BA_ "SPN" SG_ 2566670334 NumberofAxlesontheVehicle 6949;
BA_ "SPN" SG_ 2566670334 NumberofTiresontheVehicle 6950;
BA_ "SPN" SG_ 2566670590 Atttt2SCRSstAvDstBtwSstCEvts 6947;
BA_ "SPN" SG_ 2566670590 Atttt2SCRSstAvTBtwSstCEvts 6946;
BA_ "SPN" SG_ 2566670590 Atttt2SCRSstTtNSstCEvts 6943;
BA_ "SPN" SG_ 2566670590 Atttt2SCRSstTtNSstCItRqsts 6944;
BA_ "SPN" SG_ 2566670590 Atttt2SCRSstTtNSstCMRqsts 6945;
BA_ "SPN" SG_ 2566670590 Atttt2SCRSstTtSstCT 6942;
BA_ "SPN" SG_ 2566670846 Aftrtrtmnt1SCRSstmTtlClnngTm 6935;
BA_ "SPN" SG_ 2566670846 Atttt1SCRSstAvDstBtwSstCEvts 6940;
BA_ "SPN" SG_ 2566670846 Atttt1SCRSstAvTBtwSstCEvts 6939;
BA_ "SPN" SG_ 2566670846 Atttt1SCRSstTtNSstCEvts 6936;
BA_ "SPN" SG_ 2566670846 Atttt1SCRSstTtNSstCItRqsts 6937;
BA_ "SPN" SG_ 2566670846 Atttt1SCRSstTtNSstCMRqsts 6938;
BA_ "SPN" SG_ 2566670846 TtlAftrtrtmntOprtngHrs 8629;
BA_ "SPN" SG_ 2566671102 Atttt1SCRSstCdtsNtMtAtvC 7848;
BA_ "SPN" SG_ 2566671102 SCRSstCItdDtAtPdOId 6922;
BA_ "SPN" SG_ 2566671102 SCRSstCItdDtLwExstTpt 6926;
BA_ "SPN" SG_ 2566671102 SCRSstCItdDtPtSstLt 6930;
BA_ "SPN" SG_ 2566671102 SCRSstCItdDtVSpdAvAwdSpd 6924;
BA_ "SPN" SG_ 2566671102 SCRSstCItdDtVSpdBwAwdSpd 6932;
BA_ "SPN" SG_ 2566671102 SCRSstmClnngAtmtInttnCnfgrtn 6933;
BA_ "SPN" SG_ 2566671102 SCRSstmClnngInhtdDtClthDsnggd 6919;
BA_ "SPN" SG_ 2566671102 SCRSstmClnngInhtdDtEngnNtWrmdUp 6931;
BA_ "SPN" SG_ 2566671102 SCRSstmClnngInhtdDtInhtSwth 6918;
BA_ "SPN" SG_ 2566671102 SCRSstmClnngInhtdDtOtfNtrl 6923;
BA_ "SPN" SG_ 2566671102 SCRSstmClnngInhtdDtPrkngBrkNtSt 6925;
BA_ "SPN" SG_ 2566671102 SCRSstmClnngInhtdDtPTOAtv 6921;
BA_ "SPN" SG_ 2566671102 SCRSstmClnngInhtdDtSrvBrkAtv 6920;
BA_ "SPN" SG_ 2566671102 SCRSstmClnngInhtdDtSstmFltAtv 6927;
BA_ "SPN" SG_ 2566671102 SCRSstmClnngInhtdDtSstmTmt 6928;
BA_ "SPN" SG_ 2566671102 SCRSstmClnngInhtdDtTmprrSstmLkt 6929;
BA_ "SPN" SG_ 2566671102 SCRSstmClnngInhtdStts 6917;
BA_ "SPN" SG_ 2566671102 SCRSystemCleaningForcedStatus 6934;
BA_ "SPN" SG_ 2566671102 SCRSystemCleaningLampCommand 6915;
BA_ "SPN" SG_ 2566671102 SCRSystemCleaningStatus 6916;
BA_ "SPN" SG_ 2566671358 CylinderFuelRate 7333;
BA_ "SPN" SG_ 2566671358 EngineExhaustFlowRate 6895;
BA_ "SPN" SG_ 2566671358 PEMSEngineFuelMassFlowRate 6893;
BA_ "SPN" SG_ 2566671358 VehicleFuelRate 6894;
BA_ "SPN" SG_ 2566671614 NSCROptIdtOvdEvtsR 6879;
BA_ "SPN" SG_ 2566671614 SCROprtrIndmntOvrrdEnl 6877;
BA_ "SPN" SG_ 2566671614 SCROprtrIndmntOvrrdTmRmnng 6878;
BA_ "SPN" SG_ 2566671614 TtlNmrfSCROprtrIndmntOvrrdEvnts 6880;
BA_ "SPN" SG_ 2566671870 Aftrtrtmnt2DslExhstFldDsr2Prssr 8153;
BA_ "SPN" SG_ 2566671870 Aftrtrtmnt2DslExhstFldDsrPrssr 6876;
BA_ "SPN" SG_ 2566671870 Atttt2DsExstFdDs2AstPss 7464;
BA_ "SPN" SG_ 2566671870 Atttt2DsExstFdDs2Tpt 7465;
BA_ "SPN" SG_ 2566672126 Aftrtrtmnt1DslExhstFldDsr2Prssr 8152;
BA_ "SPN" SG_ 2566672126 Aftrtrtmnt1DslExhstFldDsrPrssr 6875;
BA_ "SPN" SG_ 2566672126 Atttt1DsExstFdDs2AstPss 7459;
BA_ "SPN" SG_ 2566672126 Atttt1DsExstFdDs2Tpt 7460;
BA_ "SPN" SG_ 2566672382 PayloadWeightSensor1Status 6855;
BA_ "SPN" SG_ 2566672382 PayloadWeightSensor2Status 6856;
BA_ "SPN" SG_ 2566672382 PayloadWeightSensor3Status 6857;
BA_ "SPN" SG_ 2566672382 PayloadWeightSensor4Status 6858;
BA_ "SPN" SG_ 2566672382 PayloadWeightSensor5Status 6859;
BA_ "SPN" SG_ 2566672382 PayloadWeightSensor6Status 6860;
BA_ "SPN" SG_ 2566672382 PayloadWeightSensor7Status 6861;
BA_ "SPN" SG_ 2566672382 PayloadWeightSensor8Status 6862;
BA_ "SPN" SG_ 2566672638 DeliveredPayloadConfidence 6850;
BA_ "SPN" SG_ 2566672638 DeliveredPayloadWeight 6849;
BA_ "SPN" SG_ 2566672638 HaulCycleCount 6847;
BA_ "SPN" SG_ 2566672638 HaulModeStatus 6848;
BA_ "SPN" SG_ 2566672638 PldDlvrTrnstnStts 7702;
BA_ "SPN" SG_ 2566673406 GasLeakageDetection1Pressure 6837;
BA_ "SPN" SG_ 2566673406 GasLeakageDetection2Pressure 6838;
BA_ "SPN" SG_ 2566673406 GasLeakageDetection3Pressure 6839;
BA_ "SPN" SG_ 2566673406 GssFlLkg1Cnntrtn 6834;
BA_ "SPN" SG_ 2566673406 GssFlLkg2Cnntrtn 6835;
BA_ "SPN" SG_ 2566673406 GssFlLkg3Cnntrtn 6836;
BA_ "SPN" SG_ 2566674174 AftrtrtmntSCRMlfntnTm 6819;
BA_ "SPN" SG_ 2566674174 SCROperatorInducementTotalTime 7095;
BA_ "SPN" SG_ 2566674430 DslExhstFldQltMlfntnTm 6818;
BA_ "SPN" SG_ 2566674430 DslExhstFldTnk1EmptTm 6817;
BA_ "SPN" SG_ 2566674686 EngnTrhrgr2LOlPrssr 6811;
BA_ "SPN" SG_ 2566674686 EngnTrhrgr2OlTmprtr 8850;
BA_ "SPN" SG_ 2566674686 EngnTrhrgr3LOlPrssr 6812;
BA_ "SPN" SG_ 2566674686 EngnTrhrgr4LOlPrssr 6813;
BA_ "SPN" SG_ 2566675966 HVESSNominalVoltage 8115;
BA_ "SPN" SG_ 2566675966 HVESSRmmnddMnmmOprtngVltg 8116;
BA_ "SPN" SG_ 2566675966 HVESSRmmnddMxmmOprtngVltg 8117;
BA_ "SPN" SG_ 2566675966 HVESSRmmnddMnmmSttOfChrg 8118;
BA_ "SPN" SG_ 2566675966 HVESSRmmnddMxmmSttOfChrg 8119;
BA_ "SPN" SG_ 2566675966 HVESSRmmnddMxmmOprtngTmprtr 8120;
BA_ "SPN" SG_ 2566675966 HVESSRmmnddMnmmOprtngTmprtr 8208;
BA_ "SPN" SG_ 2566675966 HVESSCellMaximumVoltageLimit 8209;
BA_ "SPN" SG_ 2566675966 HVESSCellMinimumVoltageLimit 8210;
BA_ "SPN" SG_ 2566675966 HVESSNumberofHVESPsConfigured 12904;
BA_ "SPN" SG_ 2566687742 Aftrtrtmnt1PrtltSnsrDttnStts 6777;
BA_ "SPN" SG_ 2566687742 Aftrtrtmnt1PrtltSnsrHtrRsstn 7070;
BA_ "SPN" SG_ 2566687742 Aftrtrtmnt1PrtltSnsrMxmmRsstn 6781;
BA_ "SPN" SG_ 2566687742 Aftrtrtmnt1PrtltSnsrPwrSppl 6778;
BA_ "SPN" SG_ 2566687742 Aftrtrtmnt1PrtltSnsrTmprtr 6780;
BA_ "SPN" SG_ 2566687742 Atttt1PttSsRtFdCt 6779;
BA_ "SPN" SG_ 2566687998 Aftrtrtmnt1PrtltSnsrAtvAmltnTm 6775;
BA_ "SPN" SG_ 2566687998 Aftrtrtmnt1PrtltSnsrHtrStt 6772;
BA_ "SPN" SG_ 2566687998 Aftrtrtmnt1PrtltSnsrRgnrtnStt 6774;
BA_ "SPN" SG_ 2566687998 Aftrtrtmnt1PrtltSnsrRgnrtnStts 6773;
BA_ "SPN" SG_ 2566687998 Aftrtrtmnt1PrtltSnsrRsstn 6771;
BA_ "SPN" SG_ 2566687998 Atttt1PttSsTBtwRts 6776;
BA_ "SPN" SG_ 2566689278 EngineExhaustDesiredNOx 6580;
BA_ "SPN" SG_ 2566689278 EngineExhaustNOx 6579;
BA_ "SPN" SG_ 2566689278 EngnExhstNOxSnsrPwrSppl 9812;
BA_ "SPN" SG_ 2566689534 EngineMainChamberAirFuelRatio 6575;
BA_ "SPN" SG_ 2566689534 EnginePrechamberAirFuelRatio 6577;
BA_ "SPN" SG_ 2566689534 EngnMnChmrDsrdArFlRt 6576;
BA_ "SPN" SG_ 2566689534 EngnPrhmrDsrdArFlRt 6578;
BA_ "SPN" SG_ 2566689790 EngnMnChmrFlAsltPrssr 6571;
BA_ "SPN" SG_ 2566689790 EngnMnChmrFlDsrdAsltPrssr 6572;
BA_ "SPN" SG_ 2566689790 EngnPrhmrFlAsltPrssr 6573;
BA_ "SPN" SG_ 2566689790 EngnPrhmrFlDsrdAsltPrssr 6574;
BA_ "SPN" SG_ 2566690046 AfterrunCompleteThisCycle 6482;
BA_ "SPN" SG_ 2566690046 AttttDsExstFdDsCdwCptLstC 6479;
BA_ "SPN" SG_ 2566690046 AttttDsExstFdDsCdwCptTsC 6478;
BA_ "SPN" SG_ 2566690046 AttttDsExstFdDsCdwItptCt 6476;
BA_ "SPN" SG_ 2566690046 AttttDsExstFdDsPCptLstC 6481;
BA_ "SPN" SG_ 2566690046 AttttDsExstFdDsPCptTsC 6480;
BA_ "SPN" SG_ 2566690046 AttttDsExstFdDsPItptCt 6477;
BA_ "SPN" SG_ 2566690558 EngineCommonRailOilPressure 7720;
BA_ "SPN" SG_ 2566690558 EngineExhaustPressure2 5749;
BA_ "SPN" SG_ 2566690558 EngnCmmnRlOlAsltPrssr 7721;
BA_ "SPN" SG_ 2566690558 EngnExhstPrssr1ExtnddRng 6384;
BA_ "SPN" SG_ 2566690558 EOFtItPssHRstExtddR 7470;
BA_ "SPN" SG_ 2566690814 CircleSteerModeActuatorState 6380;
BA_ "SPN" SG_ 2566690814 CrabSteerModeActuatorState 6381;
BA_ "SPN" SG_ 2566690814 FrontSteeringAxleCenteredStatus 6376;
BA_ "SPN" SG_ 2566690814 RearSteeringAxleCenteredStatus 6377;
BA_ "SPN" SG_ 2566690814 StrngCntrllrECUTmprtr 6374;
BA_ "SPN" SG_ 2566690814 Wheel2SteerActuatorState 6378;
BA_ "SPN" SG_ 2566690814 Wheel4SteerActuatorState 6379;
BA_ "SPN" SG_ 2566690814 RequestedSteeringMode 6375;
BA_ "SPN" SG_ 2566690814 SteeringModeTwoWheelSwitchInput 11733;
BA_ "SPN" SG_ 2566690814 SteeringModeCrabSwitchInput 11734;
BA_ "SPN" SG_ 2566690814 SteeringModeCircleSwitchInput 11735;
BA_ "SPN" SG_ 2566690814 SteeringModeStatus 11736;
BA_ "SPN" SG_ 2566691326 AssemblyUnitIdentification 6369;
BA_ "SPN" SG_ 2566691326 NmrfAssmlUntIdntftnFlds 6368;
BA_ "SPN" SG_ 2566691582 Joystick3Lamp10Status 6367;
BA_ "SPN" SG_ 2566691582 Joystick3Lamp1Status 6358;
BA_ "SPN" SG_ 2566691582 Joystick3Lamp2Status 6359;
BA_ "SPN" SG_ 2566691582 Joystick3Lamp3Status 6360;
BA_ "SPN" SG_ 2566691582 Joystick3Lamp4Status 6361;
BA_ "SPN" SG_ 2566691582 Joystick3Lamp5Status 6362;
BA_ "SPN" SG_ 2566691582 Joystick3Lamp6Status 6363;
BA_ "SPN" SG_ 2566691582 Joystick3Lamp7Status 6364;
BA_ "SPN" SG_ 2566691582 Joystick3Lamp8Status 6365;
BA_ "SPN" SG_ 2566691582 Joystick3Lamp9Status 6366;
BA_ "SPN" SG_ 2566691838 Joystick2Lamp10Status 6357;
BA_ "SPN" SG_ 2566691838 Joystick2Lamp1Status 6348;
BA_ "SPN" SG_ 2566691838 Joystick2Lamp2Status 6349;
BA_ "SPN" SG_ 2566691838 Joystick2Lamp3Status 6350;
BA_ "SPN" SG_ 2566691838 Joystick2Lamp4Status 6351;
BA_ "SPN" SG_ 2566691838 Joystick2Lamp5Status 6352;
BA_ "SPN" SG_ 2566691838 Joystick2Lamp6Status 6353;
BA_ "SPN" SG_ 2566691838 Joystick2Lamp7Status 6354;
BA_ "SPN" SG_ 2566691838 Joystick2Lamp8Status 6355;
BA_ "SPN" SG_ 2566691838 Joystick2Lamp9Status 6356;
BA_ "SPN" SG_ 2566692094 Joystick1Lamp10Status 6347;
BA_ "SPN" SG_ 2566692094 Joystick1Lamp1Status 6338;
BA_ "SPN" SG_ 2566692094 Joystick1Lamp2Status 6339;
BA_ "SPN" SG_ 2566692094 Joystick1Lamp3Status 6340;
BA_ "SPN" SG_ 2566692094 Joystick1Lamp4Status 6341;
BA_ "SPN" SG_ 2566692094 Joystick1Lamp5Status 6342;
BA_ "SPN" SG_ 2566692094 Joystick1Lamp6Status 6343;
BA_ "SPN" SG_ 2566692094 Joystick1Lamp7Status 6344;
BA_ "SPN" SG_ 2566692094 Joystick1Lamp8Status 6345;
BA_ "SPN" SG_ 2566692094 Joystick1Lamp9Status 6346;
BA_ "SPN" SG_ 2566692862 DisplayRemainPowered 6846;
BA_ "SPN" SG_ 2566692862 EngineFuel2Tank1Level 6642;
BA_ "SPN" SG_ 2566692862 EngineFuel2Tank2Level 6643;
BA_ "SPN" SG_ 2566692862 EngineFuel2Tank3Level 6644;
BA_ "SPN" SG_ 2566692862 EngineFuel2Tank4Level 6645;
BA_ "SPN" SG_ 2566692862 EngineOilLevelHighLow 8856;
BA_ "SPN" SG_ 2566692862 EngnOlFltrDffrntlPrssrExtnddRng 6321;
BA_ "SPN" SG_ 2566697470 EngnIgntnCntrlMdl1Stt 6216;
BA_ "SPN" SG_ 2566697470 EngnIgntnCntrlMdl1Tmprtr 6214;
BA_ "SPN" SG_ 2566697470 EngnIgntnCntrlMdl2Stt 6217;
BA_ "SPN" SG_ 2566697470 EngnIgntnCntrlMdl2Tmprtr 6215;
BA_ "SPN" SG_ 2566697726 SwitchedOutput10Current 6121;
BA_ "SPN" SG_ 2566697726 SwitchedOutput11Current 6122;
BA_ "SPN" SG_ 2566697726 SwitchedOutput12Current 6123;
BA_ "SPN" SG_ 2566697726 SwitchedOutput13Current 6124;
BA_ "SPN" SG_ 2566697726 SwitchedOutput14Current 6125;
BA_ "SPN" SG_ 2566697726 SwitchedOutput15Current 6126;
BA_ "SPN" SG_ 2566697726 SwitchedOutput16Current 6127;
BA_ "SPN" SG_ 2566697726 SwitchedOutput17Current 6128;
BA_ "SPN" SG_ 2566697726 SwitchedOutput18Current 6129;
BA_ "SPN" SG_ 2566697726 SwitchedOutput19Current 6130;
BA_ "SPN" SG_ 2566697726 SwitchedOutput1Current 6112;
BA_ "SPN" SG_ 2566697726 SwitchedOutput20Current 6131;
BA_ "SPN" SG_ 2566697726 SwitchedOutput21Current 6132;
BA_ "SPN" SG_ 2566697726 SwitchedOutput22Current 6133;
BA_ "SPN" SG_ 2566697726 SwitchedOutput23Current 6134;
BA_ "SPN" SG_ 2566697726 SwitchedOutput24Current 6135;
BA_ "SPN" SG_ 2566697726 SwitchedOutput25Current 6136;
BA_ "SPN" SG_ 2566697726 SwitchedOutput26Current 6137;
BA_ "SPN" SG_ 2566697726 SwitchedOutput27Current 6138;
BA_ "SPN" SG_ 2566697726 SwitchedOutput28Current 6139;
BA_ "SPN" SG_ 2566697726 SwitchedOutput29Current 6140;
BA_ "SPN" SG_ 2566697726 SwitchedOutput2Current 6113;
BA_ "SPN" SG_ 2566697726 SwitchedOutput30Current 6141;
BA_ "SPN" SG_ 2566697726 SwitchedOutput31Current 6142;
BA_ "SPN" SG_ 2566697726 SwitchedOutput32Current 6143;
BA_ "SPN" SG_ 2566697726 SwitchedOutput3Current 6114;
BA_ "SPN" SG_ 2566697726 SwitchedOutput4Current 6115;
BA_ "SPN" SG_ 2566697726 SwitchedOutput5Current 6116;
BA_ "SPN" SG_ 2566697726 SwitchedOutput6Current 6117;
BA_ "SPN" SG_ 2566697726 SwitchedOutput7Current 6118;
BA_ "SPN" SG_ 2566697726 SwitchedOutput8Current 6119;
BA_ "SPN" SG_ 2566697726 SwitchedOutput9Current 6120;
BA_ "SPN" SG_ 2566697982 FusedOutput10Current 6089;
BA_ "SPN" SG_ 2566697982 FusedOutput11Current 6090;
BA_ "SPN" SG_ 2566697982 FusedOutput12Current 6091;
BA_ "SPN" SG_ 2566697982 FusedOutput13Current 6092;
BA_ "SPN" SG_ 2566697982 FusedOutput14Current 6093;
BA_ "SPN" SG_ 2566697982 FusedOutput15Current 6094;
BA_ "SPN" SG_ 2566697982 FusedOutput16Current 6095;
BA_ "SPN" SG_ 2566697982 FusedOutput17Current 6096;
BA_ "SPN" SG_ 2566697982 FusedOutput18Current 6097;
BA_ "SPN" SG_ 2566697982 FusedOutput19Current 6098;
BA_ "SPN" SG_ 2566697982 FusedOutput1Current 6080;
BA_ "SPN" SG_ 2566697982 FusedOutput20Current 6099;
BA_ "SPN" SG_ 2566697982 FusedOutput21Current 6100;
BA_ "SPN" SG_ 2566697982 FusedOutput22Current 6101;
BA_ "SPN" SG_ 2566697982 FusedOutput23Current 6102;
BA_ "SPN" SG_ 2566697982 FusedOutput24Current 6103;
BA_ "SPN" SG_ 2566697982 FusedOutput25Current 6104;
BA_ "SPN" SG_ 2566697982 FusedOutput26Current 6105;
BA_ "SPN" SG_ 2566697982 FusedOutput27Current 6106;
BA_ "SPN" SG_ 2566697982 FusedOutput28Current 6107;
BA_ "SPN" SG_ 2566697982 FusedOutput29Current 6108;
BA_ "SPN" SG_ 2566697982 FusedOutput2Current 6081;
BA_ "SPN" SG_ 2566697982 FusedOutput30Current 6109;
BA_ "SPN" SG_ 2566697982 FusedOutput31Current 6110;
BA_ "SPN" SG_ 2566697982 FusedOutput32Current 6111;
BA_ "SPN" SG_ 2566697982 FusedOutput3Current 6082;
BA_ "SPN" SG_ 2566697982 FusedOutput4Current 6083;
BA_ "SPN" SG_ 2566697982 FusedOutput5Current 6084;
BA_ "SPN" SG_ 2566697982 FusedOutput6Current 6085;
BA_ "SPN" SG_ 2566697982 FusedOutput7Current 6086;
BA_ "SPN" SG_ 2566697982 FusedOutput8Current 6087;
BA_ "SPN" SG_ 2566697982 FusedOutput9Current 6088;
BA_ "SPN" SG_ 2566698238 SwitchedOutput1 6051;
BA_ "SPN" SG_ 2566698238 SwitchedOutput10 6058;
BA_ "SPN" SG_ 2566698238 SwitchedOutput11 6057;
BA_ "SPN" SG_ 2566698238 SwitchedOutput12 6056;
BA_ "SPN" SG_ 2566698238 SwitchedOutput13 6063;
BA_ "SPN" SG_ 2566698238 SwitchedOutput14 6062;
BA_ "SPN" SG_ 2566698238 SwitchedOutput15 6061;
BA_ "SPN" SG_ 2566698238 SwitchedOutput16 6060;
BA_ "SPN" SG_ 2566698238 SwitchedOutput17 6067;
BA_ "SPN" SG_ 2566698238 SwitchedOutput18 6066;
BA_ "SPN" SG_ 2566698238 SwitchedOutput19 6065;
BA_ "SPN" SG_ 2566698238 SwitchedOutput2 6050;
BA_ "SPN" SG_ 2566698238 SwitchedOutput20 6064;
BA_ "SPN" SG_ 2566698238 SwitchedOutput21 6071;
BA_ "SPN" SG_ 2566698238 SwitchedOutput22 6070;
BA_ "SPN" SG_ 2566698238 SwitchedOutput23 6069;
BA_ "SPN" SG_ 2566698238 SwitchedOutput24 6068;
BA_ "SPN" SG_ 2566698238 SwitchedOutput25 6075;
BA_ "SPN" SG_ 2566698238 SwitchedOutput26 6074;
BA_ "SPN" SG_ 2566698238 SwitchedOutput27 6073;
BA_ "SPN" SG_ 2566698238 SwitchedOutput28 6072;
BA_ "SPN" SG_ 2566698238 SwitchedOutput29 6079;
BA_ "SPN" SG_ 2566698238 SwitchedOutput3 6049;
BA_ "SPN" SG_ 2566698238 SwitchedOutput30 6078;
BA_ "SPN" SG_ 2566698238 SwitchedOutput31 6077;
BA_ "SPN" SG_ 2566698238 SwitchedOutput32 6076;
BA_ "SPN" SG_ 2566698238 SwitchedOutput4 6048;
BA_ "SPN" SG_ 2566698238 SwitchedOutput5 6055;
BA_ "SPN" SG_ 2566698238 SwitchedOutput6 6054;
BA_ "SPN" SG_ 2566698238 SwitchedOutput7 6053;
BA_ "SPN" SG_ 2566698238 SwitchedOutput8 6052;
BA_ "SPN" SG_ 2566698238 SwitchedOutput9 6059;
BA_ "SPN" SG_ 2566698494 FusedOutput1 6019;
BA_ "SPN" SG_ 2566698494 FusedOutput10 6026;
BA_ "SPN" SG_ 2566698494 FusedOutput11 6025;
BA_ "SPN" SG_ 2566698494 FusedOutput12 6024;
BA_ "SPN" SG_ 2566698494 FusedOutput13 6031;
BA_ "SPN" SG_ 2566698494 FusedOutput14 6030;
BA_ "SPN" SG_ 2566698494 FusedOutput15 6029;
BA_ "SPN" SG_ 2566698494 FusedOutput16 6028;
BA_ "SPN" SG_ 2566698494 FusedOutput17 6035;
BA_ "SPN" SG_ 2566698494 FusedOutput18 6034;
BA_ "SPN" SG_ 2566698494 FusedOutput19 6033;
BA_ "SPN" SG_ 2566698494 FusedOutput2 6018;
BA_ "SPN" SG_ 2566698494 FusedOutput20 6032;
BA_ "SPN" SG_ 2566698494 FusedOutput21 6039;
BA_ "SPN" SG_ 2566698494 FusedOutput22 6038;
BA_ "SPN" SG_ 2566698494 FusedOutput23 6037;
BA_ "SPN" SG_ 2566698494 FusedOutput24 6036;
BA_ "SPN" SG_ 2566698494 FusedOutput25 6043;
BA_ "SPN" SG_ 2566698494 FusedOutput26 6042;
BA_ "SPN" SG_ 2566698494 FusedOutput27 6041;
BA_ "SPN" SG_ 2566698494 FusedOutput28 6040;
BA_ "SPN" SG_ 2566698494 FusedOutput29 6047;
BA_ "SPN" SG_ 2566698494 FusedOutput3 6017;
BA_ "SPN" SG_ 2566698494 FusedOutput30 6046;
BA_ "SPN" SG_ 2566698494 FusedOutput31 6045;
BA_ "SPN" SG_ 2566698494 FusedOutput32 6044;
BA_ "SPN" SG_ 2566698494 FusedOutput4 6016;
BA_ "SPN" SG_ 2566698494 FusedOutput5 6023;
BA_ "SPN" SG_ 2566698494 FusedOutput6 6022;
BA_ "SPN" SG_ 2566698494 FusedOutput7 6021;
BA_ "SPN" SG_ 2566698494 FusedOutput8 6020;
BA_ "SPN" SG_ 2566698494 FusedOutput9 6027;
BA_ "SPN" SG_ 2566698750 SLIBatteryPackCapacity 5982;
BA_ "SPN" SG_ 2566698750 SLIBatteryPackHealth 5983;
BA_ "SPN" SG_ 2566698750 SLIBatteryPackStateofCharge 5981;
BA_ "SPN" SG_ 2566698750 SLICrnkngPrdtdMnmmBttrVltg 7497;
BA_ "SPN" SG_ 2566699006 HrdBttrPkRmnngChrg 5464;
BA_ "SPN" SG_ 2566699006 HrdSstmEngnStpStrtRmnngPrntg 8558;
BA_ "SPN" SG_ 2566699006 HrdPrplsnMdMxmmSpdSttng 9708;
BA_ "SPN" SG_ 2566699006 HrdPrplsnMdRmnngDstn 9709;
BA_ "SPN" SG_ 2566699262 Atttt2DsPttFtTtNxtAtvRt 5979;
BA_ "SPN" SG_ 2566699262 Atttt2SCRSstTSLstSstCEvt 6948;
BA_ "SPN" SG_ 2566699518 Atttt1DsPttFtTtNxtAtvRt 5978;
BA_ "SPN" SG_ 2566699518 Atttt1SCRSstTSLstSstCEvt 6941;
BA_ "SPN" SG_ 2566699774 Atttt2DsExstFdCtMd1PwSpp1 5968;
BA_ "SPN" SG_ 2566699774 Atttt2DsExstFdCtMd1PwSpp2 6310;
BA_ "SPN" SG_ 2566699774 Atttt2DsExstFdCtMd1RCt 5967;
BA_ "SPN" SG_ 2566699774 Atttt2DsExstFdCtMd2PwSpp1 7533;
BA_ "SPN" SG_ 2566699774 Atttt2DsExstFdCtMd2PwSpp2 7534;
BA_ "SPN" SG_ 2566699774 Atttt2DsExstFdCtMd2RCt 7532;
BA_ "SPN" SG_ 2566699774 Atttt2DsExstFdCtMdCtB 8483;
BA_ "SPN" SG_ 2566700030 Atttt1DsExstFdCtMd1PwSpp1 5966;
BA_ "SPN" SG_ 2566700030 Atttt1DsExstFdCtMd1PwSpp2 6309;
BA_ "SPN" SG_ 2566700030 Atttt1DsExstFdCtMd1RCt 5965;
BA_ "SPN" SG_ 2566700030 Atttt1DsExstFdCtMd2PwSpp1 7522;
BA_ "SPN" SG_ 2566700030 Atttt1DsExstFdCtMd2PwSpp2 7523;
BA_ "SPN" SG_ 2566700030 Atttt1DsExstFdCtMd2RCt 7521;
BA_ "SPN" SG_ 2566700030 Atttt1DsExstFdCtMdCtB 7417;
BA_ "SPN" SG_ 2566700286 Aftrtrtmnt2TtlDslExhstFldUsd 5964;
BA_ "SPN" SG_ 2566700542 Aftrtrtmnt1TtlDslExhstFldUsd 5963;
BA_ "SPN" SG_ 2566700542 AftrtrtmntTrpDslExhstFld 6563;
BA_ "SPN" SG_ 2566701566 TransmissionClutch2Pressure 5937;
BA_ "SPN" SG_ 2566701566 TrnsmssnOlTrnsmssnClrOtltTmprtr 5938;
BA_ "SPN" SG_ 2566701822 ExtrnlEnrgSrCnntnStts 7898;
BA_ "SPN" SG_ 2566701822 HrdPrplsnMdTrnstnStts 7897;
BA_ "SPN" SG_ 2566701822 HrdSstmEltrAltrntrIndtr 7451;
BA_ "SPN" SG_ 2566701822 HrdSstmHghVltgExpsrIndtr 7454;
BA_ "SPN" SG_ 2566701822 HrdSstmIntlztnIndtr 7453;
BA_ "SPN" SG_ 2566701822 HrdSstmMtrOvrspdAdlAlrm 7450;
BA_ "SPN" SG_ 2566701822 HrdSstmMtrOvrspdIndtr 7449;
BA_ "SPN" SG_ 2566701822 HrdSstmPrplsnDslStts 8267;
BA_ "SPN" SG_ 2566701822 HrdSstmRgnrtvBrkngIndtr 7452;
BA_ "SPN" SG_ 2566701822 HybridPropulsionModeStatus 7896;
BA_ "SPN" SG_ 2566701822 HybridSystemEngineAssistStatus 7418;
BA_ "SPN" SG_ 2566701822 HybridSystemOBDRelatedDTCStatus 6810;
BA_ "SPN" SG_ 2566701822 HybridSystemOverheatIndicator 5873;
BA_ "SPN" SG_ 2566701822 HybridSystemServiceIndicator 7448;
BA_ "SPN" SG_ 2566701822 HybridSystemStopIndicator 5874;
BA_ "SPN" SG_ 2566701822 HybridSystemWarningIndicator 5872;
BA_ "SPN" SG_ 2566701822 PropulsionSystemActive 7315;
BA_ "SPN" SG_ 2566701822 StoredEnergySourceLevel 7895;
BA_ "SPN" SG_ 2566701822 StrdEnrgSrInrsngMdAllwd 7894;
BA_ "SPN" SG_ 2566701822 StrdEnrgSrOnlMdAllwd 7893;
BA_ "SPN" SG_ 2566702078 SupplyGasMethanePercentage 5867;
BA_ "SPN" SG_ 2566702334 Aftrtrtmnt2SCRIntrmdtTmprtr 5864;
BA_ "SPN" SG_ 2566702334 Atttt2SCRItdtTptPFMI 5865;
BA_ "SPN" SG_ 2566702590 Aftrtrtmnt1SCRIntrmdtTmprtr 5862;
BA_ "SPN" SG_ 2566702590 Atttt1SCRItdtTptPFMI 5863;
BA_ "SPN" SG_ 2566703358 EngineDualFuelMode 6791;
BA_ "SPN" SG_ 2566703358 EngineFuelingInhibitAllowed 5795;
BA_ "SPN" SG_ 2566703358 EngnFlngDsrdRqstCnt 6897;
BA_ "SPN" SG_ 2566703358 EngnFlngInhtPrvntdRsn 5866;
BA_ "SPN" SG_ 2566703358 EngnFlngInhtPrvntdRsnExtnsn 8145;
BA_ "SPN" SG_ 2566703358 EngnFlngInhtRqstCnt 6896;
BA_ "SPN" SG_ 2566703358 EngnGsSstttnFlPrntg 6333;
BA_ "SPN" SG_ 2566703358 EngnPrttnDrtOvrrdStts 9174;
BA_ "SPN" SG_ 2566703358 FeedbackEngineFuelingState 5794;
BA_ "SPN" SG_ 2566703358 SrAddrssfCntrllngDvfrFlngStt 6307;
BA_ "SPN" SG_ 2566703358 RemainingEngineMotoringTime 12857;
BA_ "SPN" SG_ 2566703358 EnginePerformanceBiasLevel 10297;
BA_ "SPN" SG_ 2566703358 MinimumEngineMotoringSpeed 12858;
BA_ "SPN" SG_ 2566703614 EngineFuelValve1Temperature 5785;
BA_ "SPN" SG_ 2566703614 EngineFuelValve2Temperature 5786;
BA_ "SPN" SG_ 2566703614 EngineThrottleValve1Position2 6650;
BA_ "SPN" SG_ 2566703614 EngineThrottleValve1Temperature 5783;
BA_ "SPN" SG_ 2566703614 EngineThrottleValve2Temperature 5784;
BA_ "SPN" SG_ 2566703614 EngnFlRkFlSpplTmprtr 7314;
BA_ "SPN" SG_ 2566703614 EngnTrhrgrWstgtAttr2Tmprtr 5787;
BA_ "SPN" SG_ 2566703870 EExstGsRt2Att1TptStts 5774;
BA_ "SPN" SG_ 2566703870 EExstGsRt2Att2TptStts 5778;
BA_ "SPN" SG_ 2566703870 EngnExhstGsRrltn2Attr1DsrdPstn 5776;
BA_ "SPN" SG_ 2566703870 EngnExhstGsRrltn2Attr1OprtnStts 5781;
BA_ "SPN" SG_ 2566703870 EngnExhstGsRrltn2Attr1PrlmnrFMI 5773;
BA_ "SPN" SG_ 2566703870 EngnExhstGsRrltn2Attr1Tmprtr 5775;
BA_ "SPN" SG_ 2566703870 EngnExhstGsRrltn2Attr2DsrdPstn 5780;
BA_ "SPN" SG_ 2566703870 EngnExhstGsRrltn2Attr2OprtnStts 5782;
BA_ "SPN" SG_ 2566703870 EngnExhstGsRrltn2Attr2PrlmnrFMI 5777;
BA_ "SPN" SG_ 2566703870 EngnExhstGsRrltn2Attr2Tmprtr 5779;
BA_ "SPN" SG_ 2566704126 EExstGsRt1Att1TptStts 5764;
BA_ "SPN" SG_ 2566704126 EExstGsRt1Att2TptStts 5768;
BA_ "SPN" SG_ 2566704126 EngnExhstGsRrltn1Attr1DsrdPstn 5766;
BA_ "SPN" SG_ 2566704126 EngnExhstGsRrltn1Attr1OprtnStts 5771;
BA_ "SPN" SG_ 2566704126 EngnExhstGsRrltn1Attr1PrlmnrFMI 5763;
BA_ "SPN" SG_ 2566704126 EngnExhstGsRrltn1Attr1Tmprtr 5765;
BA_ "SPN" SG_ 2566704126 EngnExhstGsRrltn1Attr2DsrdPstn 5770;
BA_ "SPN" SG_ 2566704126 EngnExhstGsRrltn1Attr2OprtnStts 5772;
BA_ "SPN" SG_ 2566704126 EngnExhstGsRrltn1Attr2PrlmnrFMI 5767;
BA_ "SPN" SG_ 2566704126 EngnExhstGsRrltn1Attr2Tmprtr 5769;
BA_ "SPN" SG_ 2566704382 Aftrtrtmnt1Otlt1GsSnsrPwrSppl 5759;
BA_ "SPN" SG_ 2566704382 Aftrtrtmnt1Otlt2GsSnsrPwrSppl 8147;
BA_ "SPN" SG_ 2566704382 Aftrtrtmnt2Otlt1GsSnsrPwrSppl 5761;
BA_ "SPN" SG_ 2566704382 EngnExhst1GsSnsr1PwrSppl 5758;
BA_ "SPN" SG_ 2566704382 EngnExhst2GsSnsr1PwrSppl 5760;
BA_ "SPN" SG_ 2566704382 EngnExhst1GsSnsr2PwrSppl 8146;
BA_ "SPN" SG_ 2566705150 Atttt1OttNOxSsSdssT 5709;
BA_ "SPN" SG_ 2566705150 Atttt2OttNOxSsSdssT 5711;
BA_ "SPN" SG_ 2566705150 EngnExhst1NOxSnsrSlfdgnssTrggr 5710;
BA_ "SPN" SG_ 2566705150 EngnExhst2NOxSnsrSlfdgnssTrggr 5712;
BA_ "SPN" SG_ 2566705406 Aftrtrtmnt1PrtltSnsr 5835;
BA_ "SPN" SG_ 2566705406 Aftrtrtmnt1PrtltSnsrCrrnt 7393;
BA_ "SPN" SG_ 2566705406 Aftrtrtmnt2PrtltSnsr 5836;
BA_ "SPN" SG_ 2566706686 Aftrtrtmnt1DslExhstFldPmpHtr 5706;
BA_ "SPN" SG_ 2566706686 Atttt1DsExstFdDsUt1HtR 5746;
BA_ "SPN" SG_ 2566706686 Atttt1DsExstFdPp2MtSpd 7461;
BA_ "SPN" SG_ 2566706686 Atttt1DsExstFdPpPwSpp 8474;
BA_ "SPN" SG_ 2566706942 Atttt1DsPttFt2StSsAssFq3 5652;
BA_ "SPN" SG_ 2566706942 Atttt1DsPttFt2StSsAssFq4 5654;
BA_ "SPN" SG_ 2566706942 Atttt1DsPttFt2StSsFq3StS 5653;
BA_ "SPN" SG_ 2566706942 Atttt1DsPttFt2StSsFq4StS 5655;
BA_ "SPN" SG_ 2566707198 Atttt1DsPttFt2StSsAssFq1 5648;
BA_ "SPN" SG_ 2566707198 Atttt1DsPttFt2StSsAssFq2 5650;
BA_ "SPN" SG_ 2566707198 Atttt1DsPttFt2StSsFq1StS 5649;
BA_ "SPN" SG_ 2566707198 Atttt1DsPttFt2StSsFq2StS 5651;
BA_ "SPN" SG_ 2566707454 Atttt1DsPttFt2StSsAssRqstFq1 5644;
BA_ "SPN" SG_ 2566707454 Atttt1DsPttFt2StSsAssRqstFq2 5645;
BA_ "SPN" SG_ 2566707454 Atttt1DsPttFt2StSsAssRqstFq3 5646;
BA_ "SPN" SG_ 2566707454 Atttt1DsPttFt2StSsAssRqstFq4 5647;
BA_ "SPN" SG_ 2566707710 Atttt1DsPttFt1StSsAssFq3 5640;
BA_ "SPN" SG_ 2566707710 Atttt1DsPttFt1StSsAssFq4 5642;
BA_ "SPN" SG_ 2566707710 Atttt1DsPttFt1StSsFq3StS 5641;
BA_ "SPN" SG_ 2566707710 Atttt1DsPttFt1StSsFq4StS 5643;
BA_ "SPN" SG_ 2566707966 Atttt1DsPttFt1StSsAssFq1 5636;
BA_ "SPN" SG_ 2566707966 Atttt1DsPttFt1StSsAssFq2 5638;
BA_ "SPN" SG_ 2566707966 Atttt1DsPttFt1StSsFq1StS 5637;
BA_ "SPN" SG_ 2566707966 Atttt1DsPttFt1StSsFq2StS 5639;
BA_ "SPN" SG_ 2566708222 Atttt1DsPttFt1StSsAssRqstFq1 5632;
BA_ "SPN" SG_ 2566708222 Atttt1DsPttFt1StSsAssRqstFq2 5633;
BA_ "SPN" SG_ 2566708222 Atttt1DsPttFt1StSsAssRqstFq3 5634;
BA_ "SPN" SG_ 2566708222 Atttt1DsPttFt1StSsAssRqstFq4 5635;
BA_ "SPN" SG_ 2566708478 AdptvCrsCntrlRdnssStts 5606;
BA_ "SPN" SG_ 2566708478 AEBSreadinessstate 6208;
BA_ "SPN" SG_ 2566708478 CrsCntrlDrvrCnlltnStts 7836;
BA_ "SPN" SG_ 2566708478 CrsCntrlStSpdHghRsltn 6809;
BA_ "SPN" SG_ 2566708478 CruiseControlSpeed 7319;
BA_ "SPN" SG_ 2566708478 CruiseControlSystemCommandState 5607;
BA_ "SPN" SG_ 2566708478 PrdtvCrsCntrlStSpdOffstStts 7318;
BA_ "SPN" SG_ 2566708478 SAddssCtDvDsCsCt 5608;
BA_ "SPN" SG_ 2566708478 SAddssCtDvPsCsCt 5609;
BA_ "SPN" SG_ 2566708734 Aftrtrtmnt2SndrArAsltPrssr 5590;
BA_ "SPN" SG_ 2566708990 Aftrtrtmnt1SndrArAsltPrssr 5589;
BA_ "SPN" SG_ 2566708990 OprtrIndmntOvrrdRnwlRqrd 10154;
BA_ "SPN" SG_ 2566709246 EFSppPpItAstPssExtddR 7472;
BA_ "SPN" SG_ 2566709246 EngineFuelFilterDegradation 5584;
BA_ "SPN" SG_ 2566709246 EngineFuelReturnPressure 6816;
BA_ "SPN" SG_ 2566709246 EngnFlDlvrAsltPrssr 5578;
BA_ "SPN" SG_ 2566709246 EngnFltrdFlDlvrAsltPrssr 5580;
BA_ "SPN" SG_ 2566709246 EngnFltrdFlDlvrPrssr 5579;
BA_ "SPN" SG_ 2566709246 EngnThrttlVlv2DffrntlPrssr 7595;
BA_ "SPN" SG_ 2566709502 Aftertreatment1FuelMassRate 5503;
BA_ "SPN" SG_ 2566709502 Aftertreatment2FuelMassRate 5834;
BA_ "SPN" SG_ 2566709502 Atttt1DsPttFtItTptStPt 5501;
BA_ "SPN" SG_ 2566709502 EngineUnburnedFuelPercentage 5502;
BA_ "SPN" SG_ 2566709758 EngineDieselFuelDemandRate 7596;
BA_ "SPN" SG_ 2566709758 EngineFuelRateHighResolution 1600;
BA_ "SPN" SG_ 2566710014 SpplmntlFnCntrllrECUTmprtr 5561;
BA_ "SPN" SG_ 2566710014 SpplmntlFnCntrllrTmprtrStts 5559;
BA_ "SPN" SG_ 2566710014 SupplementalFanCurrent 5563;
BA_ "SPN" SG_ 2566710014 SupplementalFanDirectionStatus 5557;
BA_ "SPN" SG_ 2566710014 SupplementalFanDriveStatus 5560;
BA_ "SPN" SG_ 2566710014 SupplementalFanEnableStatus 5556;
BA_ "SPN" SG_ 2566710014 SupplementalFanPower 5564;
BA_ "SPN" SG_ 2566710014 SupplementalFanSpeed 5562;
BA_ "SPN" SG_ 2566710014 SupplementalFanVelocityStatus 5558;
BA_ "SPN" SG_ 2566710526 EngineFuelDensity 5538;
BA_ "SPN" SG_ 2566710526 EngineFuelDynamicViscosity 5537;
BA_ "SPN" SG_ 2566710526 EngnFl1Tmprtr1HghRsltn 5540;
BA_ "SPN" SG_ 2566710526 EngnFlDltrtHghRsltn 5539;
BA_ "SPN" SG_ 2566710782 HdrlOlRltvDltrtHghRsltn 5535;
BA_ "SPN" SG_ 2566710782 HdrlOlTmprtrHghRsltn 5536;
BA_ "SPN" SG_ 2566710782 HydraulicOilDensity 5534;
BA_ "SPN" SG_ 2566710782 HydraulicOilDynamicViscosity 5533;
BA_ "SPN" SG_ 2566711038 LubricationCycleModeLockStatus 5515;
BA_ "SPN" SG_ 2566711038 LubricationCycleModeStatus 5516;
BA_ "SPN" SG_ 2566711038 LubricationOperationModeStatus 5517;
BA_ "SPN" SG_ 2566711038 LubricationPumpEnableStatus 5518;
BA_ "SPN" SG_ 2566711038 LubricationReservoirLevel 5519;
BA_ "SPN" SG_ 2566711038 LubricationTimingCycleStatus 5520;
BA_ "SPN" SG_ 2566711294 EngnFrtnPrntTrqAtIdlPnt1 5471;
BA_ "SPN" SG_ 2566711294 EngnFrtnPrntTrqPnt2 5472;
BA_ "SPN" SG_ 2566711294 EngnFrtnPrntTrqPnt3 5473;
BA_ "SPN" SG_ 2566711294 EngnFrtnPrntTrqPnt4 5474;
BA_ "SPN" SG_ 2566711294 EngnFrtnPrntTrqPnt5 5475;
BA_ "SPN" SG_ 2566711294 EngnFrtnPrntTrqPnt6 5476;
BA_ "SPN" SG_ 2566711294 EngnFrtnPrntTrqPnt7 5477;
BA_ "SPN" SG_ 2566711550 ItVvAttSstOPss1SdCt 5499;
BA_ "SPN" SG_ 2566711550 ItVvAttSstOPss2SdCt 5500;
